// *************************************************************************** *
// *                                                                           *
// *                      Mentor Graphics Corporation                          *
// *                          All rights reserved                              *
// *                                                                           *
// *************************************************************************** *
// *                                                                           *
// * Description:         CANDB File                                           *
// * Generated at:        2020-04-14 13:10:23                                  *
// * System:              SDB20010                                             *
// * Variant:             EX11_AVP                                             *
// * Network:             ChassisCAN1                                          *
// *                                                                           *
// *************************************************************************** *
// *                                                                           *
// *             THIS CONFIGURATION MIGHT CONTAIN SOME ERRORS                  *
// *              IF THE INPUT MODEL WAS NOT PROPERLY FORMED!                  *
// *                    Do Not Use this File directly!                         *
// *                                                                           *
// *************************************************************************** *
VERSION "ChassisCAN1"

NS_ :

BS_:

BU_:  ASDM ECM ETC MVEM PAS PSCM1 SAS TCM VDDM

BO_ 147 AsdmChas1Fr01: 8 ASDM
 SG_ AsyADL3FuncCtrlSts_UB : 32|1@0+ (1,0) [0|1] "" PSCM1
 SG_ AsyADL3FuncCtrlStsADMod : 27|2@0+ (1,0) [0|3] "" PSCM1
 SG_ AsyADL3FuncCtrlStsChks : 23|8@0+ (1.0,0.0) [0.0|255.0] "Unitless" PSCM1
 SG_ AsyADL3FuncCtrlStsCntr : 31|4@0+ (1.0,0.0) [0.0|15.0] "Unitless" PSCM1
 SG_ AsyADL3FuncCtrlStsCtrlSts : 33|1@0+ (1,0) [0|1] "" PSCM1
 SG_ AsyADL3FuncCtrlStsDegraded : 39|4@0+ (1.0,0.0) [0.0|15.0] "Unitless" PSCM1
 SG_ AsyADL3FuncCtrlStsQf : 25|2@0+ (1,0) [0|3] "" PSCM1
 SG_ AsyADL3FuncCtrlStsSts : 35|2@0+ (1,0) [0|3] "" PSCM1
 SG_ AsyADModeReq_UB : 48|1@0+ (1,0) [0|1] "" PSCM1
 SG_ AsyADModeReqADActiveReq : 51|2@0+ (1,0) [0|3] "" PSCM1
 SG_ AsyADModeReqADDeactiveReq : 49|1@0+ (1,0) [0|1] "" PSCM1
 SG_ AsyADModeReqChks : 47|8@0+ (1.0,0.0) [0.0|255.0] "Unitless" PSCM1
 SG_ AsyADModeReqCntr : 55|4@0+ (1.0,0.0) [0.0|15.0] "Unitless" PSCM1
 SG_ PASFuncActive : 15|1@0+ (1,0) [0|1] "" Vector_XXX
 SG_ PASFuncActive_UB : 14|1@0+ (1,0) [0|1] "" Vector_XXX
 SG_ RctaBrkReqQM : 13|1@0+ (1,0) [0|1] "" Vector_XXX
 SG_ RctaBrkReqQM_UB : 12|1@0+ (1,0) [0|1] "" Vector_XXX
 SG_ RcwmBrkReqQM : 11|1@0+ (1,0) [0|1] "" Vector_XXX
 SG_ RcwmBrkReqQM_UB : 10|1@0+ (1,0) [0|1] "" Vector_XXX

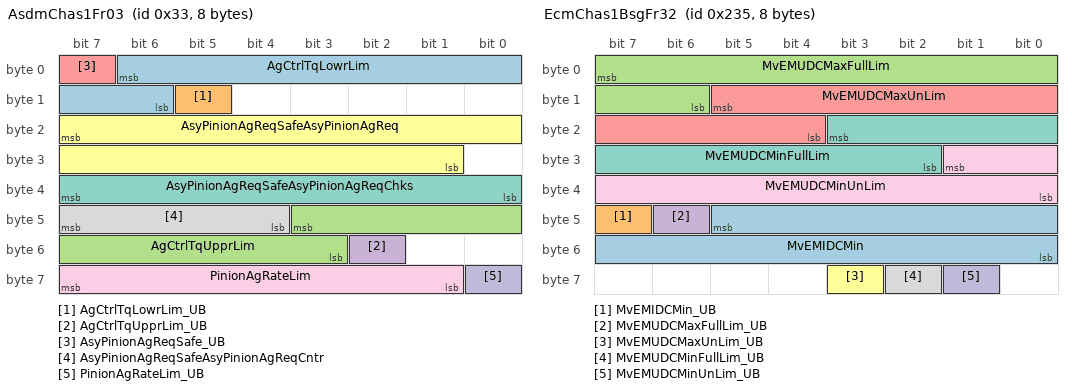
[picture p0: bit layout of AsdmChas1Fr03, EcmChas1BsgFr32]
BO_ 51 AsdmChas1Fr03: 8 ASDM
 SG_ AgCtrlTqLowrLim : 6|9@0+ (0.125,-30.0) [-30.0|30.0] "Nm" PSCM1
 SG_ AgCtrlTqLowrLim_UB : 13|1@0+ (1,0) [0|1] "" PSCM1
 SG_ AgCtrlTqUpprLim : 43|9@0+ (0.125,-30.0) [-30.0|30.0] "Nm" PSCM1
 SG_ AgCtrlTqUpprLim_UB : 50|1@0+ (1,0) [0|1] "" PSCM1
 SG_ AsyPinionAgReqSafe_UB : 7|1@0+ (1,0) [0|1] "" PSCM1
 SG_ AsyPinionAgReqSafeAsyPinionAgReq : 23|15@0+ (0.0009765625,-14.5) [-14.5|17.4990234375] "rad" PSCM1
 SG_ AsyPinionAgReqSafeAsyPinionAgReqChks : 39|8@0+ (1.0,0.0) [0.0|255.0] "Unitless" PSCM1
 SG_ AsyPinionAgReqSafeAsyPinionAgReqCntr : 47|4@0+ (1.0,0.0) [0.0|15.0] "Unitless" PSCM1
 SG_ PinionAgRateLim : 63|7@0+ (0.0175,0.0) [0.0|1.7500000000000002] "rad/s" PSCM1
 SG_ PinionAgRateLim_UB : 56|1@0+ (1,0) [0|1] "" PSCM1

BO_ 1321 AsdmChas1NMFr: 8 ASDM
 SG_ PNC16_ASDM : 16|1@0+ (1,0) [0|0] "" VDDM
 SG_ PNC17_ASDM : 17|1@0+ (1,0) [0|0] "" VDDM
 SG_ PNC18_ASDM : 18|1@0+ (1,0) [0|0] "" VDDM
 SG_ PNC19_ASDM : 19|1@0+ (1,0) [0|0] "" VDDM
 SG_ PNC20_ASDM : 20|1@0+ (1,0) [0|0] "" VDDM
 SG_ PNC21_ASDM : 21|1@0+ (1,0) [0|0] "" VDDM
 SG_ PNC22_ASDM : 22|1@0+ (1,0) [0|0] "" VDDM
 SG_ PNC23_ASDM : 23|1@0+ (1,0) [0|0] "" VDDM
 SG_ PNC24_ASDM : 24|1@0+ (1,0) [0|0] "" VDDM
 SG_ PNC25_ASDM : 25|1@0+ (1,0) [0|0] "" VDDM
 SG_ PNC26_ASDM : 26|1@0+ (1,0) [0|0] "" VDDM
 SG_ PNC27_ASDM : 27|1@0+ (1,0) [0|0] "" VDDM
 SG_ PNC28_ASDM : 28|1@0+ (1,0) [0|0] "" VDDM
 SG_ PNC29_ASDM : 29|1@0+ (1,0) [0|0] "" VDDM
 SG_ PNC30_ASDM : 30|1@0+ (1,0) [0|0] "" VDDM
 SG_ PNC31_ASDM : 31|1@0+ (1,0) [0|0] "" VDDM
 SG_ PNC32_ASDM : 32|1@0+ (1,0) [0|0] "" VDDM
 SG_ PNC33_ASDM : 33|1@0+ (1,0) [0|0] "" VDDM
 SG_ PNC34_ASDM : 34|1@0+ (1,0) [0|0] "" VDDM
 SG_ PNC35_ASDM : 35|1@0+ (1,0) [0|0] "" VDDM
 SG_ PNC36_ASDM : 36|1@0+ (1,0) [0|0] "" VDDM
 SG_ PNC37_ASDM : 37|1@0+ (1,0) [0|0] "" VDDM
 SG_ PNC38_ASDM : 38|1@0+ (1,0) [0|0] "" VDDM
 SG_ PNC39_ASDM : 39|1@0+ (1,0) [0|0] "" VDDM
 SG_ NM_PNI_ASDM : 14|1@0+ (1,0) [0|0] "" VDDM
 SG_ NM_AW_ASDM : 12|1@0+ (1,0) [0|0] "" VDDM
 SG_ NM_CS_ASDM : 11|1@0+ (1,0) [0|0] "" VDDM
 SG_ NM_RMR_ASDM : 8|1@0+ (1,0) [0|0] "" VDDM
 SG_ NM_NodeID_ASDM : 7|8@0+ (1,0) [0|0] "" VDDM

BO_ 565 EcmChas1BsgFr32: 8 ECM
 SG_ MvEMIDCMin : 45|14@0+ (1.0,-500.0) [-500.0|9500.0] "A" MVEM
 SG_ MvEMIDCMin_UB : 47|1@0+ (1,0) [0|1] "" MVEM
 SG_ MvEMUDCMaxFullLim : 7|10@0+ (0.1,0.0) [0.0|102.30000000000001] "Volt" MVEM
 SG_ MvEMUDCMaxFullLim_UB : 46|1@0+ (1,0) [0|1] "" MVEM
 SG_ MvEMUDCMaxUnLim : 13|10@0+ (0.1,0.0) [0.0|102.30000000000001] "Volt" MVEM
 SG_ MvEMUDCMaxUnLim_UB : 59|1@0+ (1,0) [0|1] "" MVEM
 SG_ MvEMUDCMinFullLim : 19|10@0+ (0.1,0.0) [0.0|102.30000000000001] "Volt" MVEM
 SG_ MvEMUDCMinFullLim_UB : 58|1@0+ (1,0) [0|1] "" MVEM
 SG_ MvEMUDCMinUnLim : 25|10@0+ (0.1,0.0) [0.0|102.30000000000001] "Volt" MVEM
 SG_ MvEMUDCMinUnLim_UB : 57|1@0+ (1,0) [0|1] "" MVEM

BO_ 631 EcmChas1BsgFr33: 8 ECM
 SG_ MvEMCooltFlowForDtElec : 7|9@0+ (0.1,0.0) [0.0|51.1] "L / min" MVEM
 SG_ MvEMCooltFlowForDtElec_UB : 8|1@0+ (1,0) [0|1] "" MVEM
 SG_ MvEMCooltT : 23|8@0+ (1.0,-50.0) [-50.0|200.0] "degC" MVEM
 SG_ MvEMCooltT_UB : 14|1@0+ (1,0) [0|1] "" MVEM

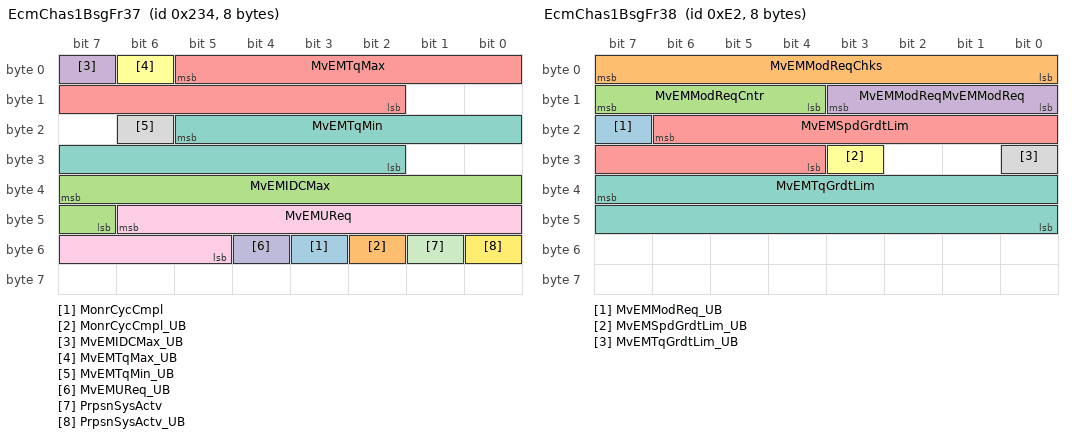
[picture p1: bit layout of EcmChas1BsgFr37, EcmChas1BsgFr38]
BO_ 564 EcmChas1BsgFr37: 8 ECM
 SG_ MonrCycCmpl : 51|1@0+ (1,0) [0|1] "" MVEM
 SG_ MonrCycCmpl_UB : 50|1@0+ (1,0) [0|1] "" MVEM
 SG_ MvEMIDCMax : 39|9@0+ (1.0,0.0) [0.0|511.0] "A" MVEM
 SG_ MvEMIDCMax_UB : 7|1@0+ (1,0) [0|1] "" MVEM
 SG_ MvEMTqMax : 5|12@0+ (0.1,-70.0) [-70.0|70.0] "NewtonMeter" MVEM
 SG_ MvEMTqMax_UB : 6|1@0+ (1,0) [0|1] "" MVEM
 SG_ MvEMTqMin : 21|12@0+ (0.1,-70.0) [-70.0|70.0] "NewtonMeter" MVEM
 SG_ MvEMTqMin_UB : 22|1@0+ (1,0) [0|1] "" MVEM
 SG_ MvEMUReq : 46|10@0+ (0.1,0.0) [0.0|102.30000000000001] "Volt" MVEM
 SG_ MvEMUReq_UB : 52|1@0+ (1,0) [0|1] "" MVEM
 SG_ PrpsnSysActv : 49|1@0+ (1,0) [0|1] "" MVEM
 SG_ PrpsnSysActv_UB : 48|1@0+ (1,0) [0|1] "" MVEM

BO_ 226 EcmChas1BsgFr38: 8 ECM
 SG_ MvEMModReq_UB : 23|1@0+ (1,0) [0|1] "" MVEM
 SG_ MvEMModReqChks : 7|8@0+ (1.0,0.0) [0.0|255.0] "Unitless" MVEM
 SG_ MvEMModReqCntr : 15|4@0+ (1.0,0.0) [0.0|15.0] "Unitless" MVEM
 SG_ MvEMModReqMvEMModReq : 11|4@0+ (1,0) [0|15] "" MVEM
 SG_ MvEMSpdGrdtLim : 22|11@0+ (20.0,0.0) [0.0|40000.0] "RpmPerSec" MVEM
 SG_ MvEMSpdGrdtLim_UB : 27|1@0+ (1,0) [0|1] "" MVEM
 SG_ MvEMTqGrdtLim : 39|16@0+ (1.0,0.0) [0.0|55000.0] "Nm/s" MVEM
 SG_ MvEMTqGrdtLim_UB : 24|1@0+ (1,0) [0|1] "" MVEM

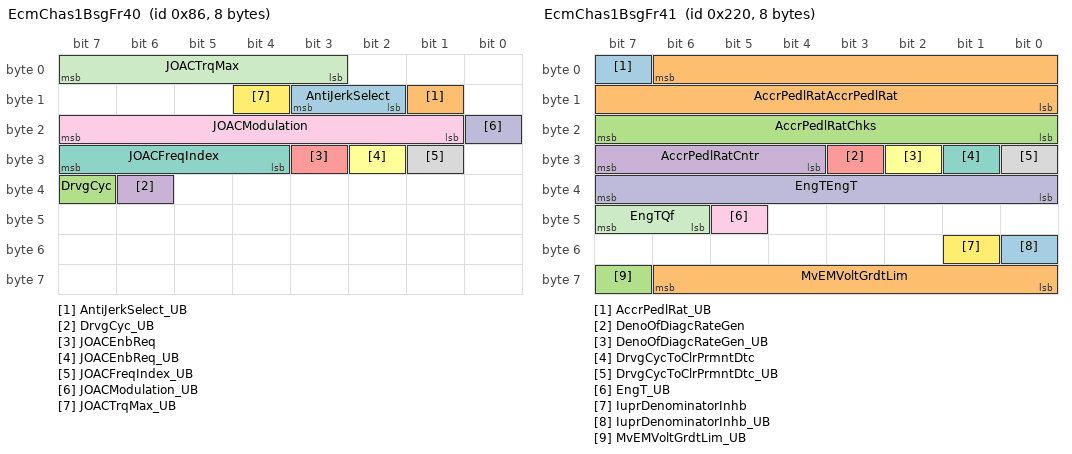
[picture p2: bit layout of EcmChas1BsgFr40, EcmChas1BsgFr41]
BO_ 134 EcmChas1BsgFr40: 8 ECM
 SG_ AntiJerkSelect : 11|2@0+ (1,0) [0|3] "" MVEM
 SG_ AntiJerkSelect_UB : 9|1@0+ (1,0) [0|1] "" MVEM
 SG_ DrvgCyc : 39|1@0+ (1,0) [0|1] "" MVEM
 SG_ DrvgCyc_UB : 38|1@0+ (1,0) [0|1] "" MVEM
 SG_ JOACEnbReq : 27|1@0+ (1,0) [0|1] "" MVEM
 SG_ JOACEnbReq_UB : 26|1@0+ (1,0) [0|1] "" MVEM
 SG_ JOACFreqIndex : 31|4@0+ (1,0) [0|15] "" MVEM
 SG_ JOACFreqIndex_UB : 25|1@0+ (1,0) [0|1] "" MVEM
 SG_ JOACModulation : 23|7@0+ (1.0,0.0) [0.0|100.0] "Unitless" MVEM
 SG_ JOACModulation_UB : 16|1@0+ (1,0) [0|1] "" MVEM
 SG_ JOACTrqMax : 7|5@0+ (1.0,0.0) [0.0|25.0] "Unitless" MVEM
 SG_ JOACTrqMax_UB : 12|1@0+ (1,0) [0|1] "" MVEM

BO_ 544 EcmChas1BsgFr41: 8 ECM
 SG_ AccrPedlRat_UB : 7|1@0+ (1,0) [0|1] "" MVEM
 SG_ AccrPedlRatAccrPedlRat : 6|15@0+ (0.00390625,0.0) [0.0|100.0] "%" MVEM
 SG_ AccrPedlRatChks : 23|8@0+ (1.0,0.0) [0.0|255.0] "Unitless" MVEM
 SG_ AccrPedlRatCntr : 31|4@0+ (1.0,0.0) [0.0|15.0] "Unitless" MVEM
 SG_ DenoOfDiagcRateGen : 27|1@0+ (1,0) [0|1] "" MVEM
 SG_ DenoOfDiagcRateGen_UB : 26|1@0+ (1,0) [0|1] "" MVEM
 SG_ DrvgCycToClrPrmntDtc : 25|1@0+ (1,0) [0|1] "" MVEM
 SG_ DrvgCycToClrPrmntDtc_UB : 24|1@0+ (1,0) [0|1] "" MVEM
 SG_ EngT_UB : 45|1@0+ (1,0) [0|1] "" MVEM
 SG_ EngTEngT : 39|8@0+ (1.0,-50.0) [-50.0|200.0] "degC" MVEM
 SG_ EngTQf : 47|2@0+ (1,0) [0|3] "" MVEM
 SG_ IuprDenominatorInhb : 49|1@0+ (1,0) [0|1] "" MVEM
 SG_ IuprDenominatorInhb_UB : 48|1@0+ (1,0) [0|1] "" MVEM
 SG_ MvEMVoltGrdtLim : 62|7@0+ (1.0,0.0) [0.0|100.0] "V/s" MVEM
 SG_ MvEMVoltGrdtLim_UB : 63|1@0+ (1,0) [0|1] "" MVEM

BO_ 530 EcmChas1BsgFr42: 8 ECM
 SG_ EngTiOn : 31|16@0+ (1.0,0.0) [0.0|65535.0] "s" MVEM
 SG_ EngTiOn_UB : 13|1@0+ (1,0) [0|1] "" MVEM
 SG_ LoadValCalcd : 7|8@0+ (0.392156862745,0.0) [0.0|99.999999999975] "%" MVEM
 SG_ LoadValCalcd_UB : 15|1@0+ (1,0) [0|1] "" MVEM
 SG_ ThrPos : 23|8@0+ (0.5,0.0) [0.0|100.0] "%" MVEM
 SG_ ThrPos_UB : 14|1@0+ (1,0) [0|1] "" MVEM

BO_ 32 EcmChas1Fr01: 8 ECM
 SG_ PtCluSlipCtrl_UB : 5|1@0+ (1,0) [0|1] "" TCM
 SG_ PtCluSlipCtrlModReq : 3|2@0+ (1,0) [0|3] "" TCM
 SG_ PtCluSlipCtrlReq : 4|1@0+ (1,0) [0|1] "" TCM
 SG_ PtCluSlipCtrlSpdReq : 1|10@0+ (1.0,0.0) [0.0|1023.0] "rpm" TCM
 SG_ PtCluTqCp_UB : 21|1@0+ (1,0) [0|1] "" TCM
 SG_ PtCluTqCpReq1 : 20|13@0+ (0.1,-5.0) [-5.0|814.1] "NewtonMeter" TCM
 SG_ PtCluTqCpReq2 : 36|13@0+ (0.1,-5.0) [-5.0|814.1] "NewtonMeter" TCM
 SG_ PtEngTqDstbcActv : 6|1@0+ (1,0) [0|1] "" TCM
 SG_ PtEngTqDstbcActv_UB : 7|1@0+ (1,0) [0|1] "" TCM
 SG_ PtEngTqModlnSts : 23|2@0+ (1,0) [0|3] "" TCM
 SG_ PtEngTqModlnSts_UB : 55|1@0+ (1,0) [0|1] "" TCM
 SG_ PtGearActtnReq3 : 59|4@0+ (1,0) [0|15] "" TCM
 SG_ PtGearActtnReq3_UB : 53|1@0+ (1,0) [0|1] "" TCM
 SG_ PtRotReqAckd1 : 48|1@0+ (1,0) [0|1] "" TCM
 SG_ PtRotReqAckd1_UB : 50|1@0+ (1,0) [0|1] "" TCM
 SG_ PtRotReqAckd2 : 49|1@0+ (1,0) [0|1] "" TCM
 SG_ PtRotReqAckd2_UB : 51|1@0+ (1,0) [0|1] "" TCM

BO_ 37 EcmChas1Fr02: 8 ECM
 SG_ PtCluTqCpMaxCmd1 : 40|1@0+ (1,0) [0|1] "" TCM
 SG_ PtCluTqCpMaxCmd1_UB : 45|1@0+ (1,0) [0|1] "" TCM
 SG_ PtCluTqCpMaxCmd2 : 41|1@0+ (1,0) [0|1] "" TCM
 SG_ PtCluTqCpMaxCmd2_UB : 46|1@0+ (1,0) [0|1] "" TCM
 SG_ PtCluTqCpMinCmd1 : 42|1@0+ (1,0) [0|1] "" TCM
 SG_ PtCluTqCpMinCmd1_UB : 55|1@0+ (1,0) [0|1] "" TCM
 SG_ PtCluTqCpMinCmd2 : 43|1@0+ (1,0) [0|1] "" TCM
 SG_ PtCluTqCpMinCmd2_UB : 54|1@0+ (1,0) [0|1] "" TCM
 SG_ PtDirAllwdToTrsmActr_UB : 47|1@0+ (1,0) [0|1] "" TCM
 SG_ PtDirAllwdToTrsmActrChks : 39|8@0+ (1.0,0.0) [0.0|255.0] "Unitless" TCM
 SG_ PtDirAllwdToTrsmActrCntr : 27|4@0+ (1.0,0.0) [0.0|15.0] "Unitless" TCM
 SG_ PtDirAllwdToTrsmActrFwd : 28|1@0+ (1,0) [0|1] "" TCM
 SG_ PtDirAllwdToTrsmActrNeut : 29|1@0+ (1,0) [0|1] "" TCM
 SG_ PtDirAllwdToTrsmActrParkRls : 30|1@0+ (1,0) [0|1] "" TCM
 SG_ PtDirAllwdToTrsmActrRvs : 31|1@0+ (1,0) [0|1] "" TCM
 SG_ PtGearActrAdpnCmd : 44|1@0+ (1,0) [0|1] "" TCM
 SG_ PtGearActrAdpnCmd_UB : 53|1@0+ (1,0) [0|1] "" TCM
 SG_ PtGearActtn_UB : 7|1@0+ (1,0) [0|1] "" TCM,VDDM
 SG_ PtGearActtnAllwdSts1 : 6|2@0+ (1,0) [0|3] "" TCM,VDDM
 SG_ PtGearActtnAllwdSts2 : 4|2@0+ (1,0) [0|3] "" TCM,VDDM
 SG_ PtGearActtnModReq : 2|2@0+ (1,0) [0|3] "" TCM,VDDM
 SG_ PtGearActtnPfmncReq : 23|8@0+ (1.0,0.0) [0.0|255.0] "Unitless" TCM,VDDM
 SG_ PtGearActtnPrio : 0|1@0+ (1,0) [0|1] "" TCM,VDDM
 SG_ PtGearActtnReq1 : 15|4@0+ (1,0) [0|15] "" TCM,VDDM
 SG_ PtGearActtnReq2 : 11|4@0+ (1,0) [0|15] "" TCM,VDDM

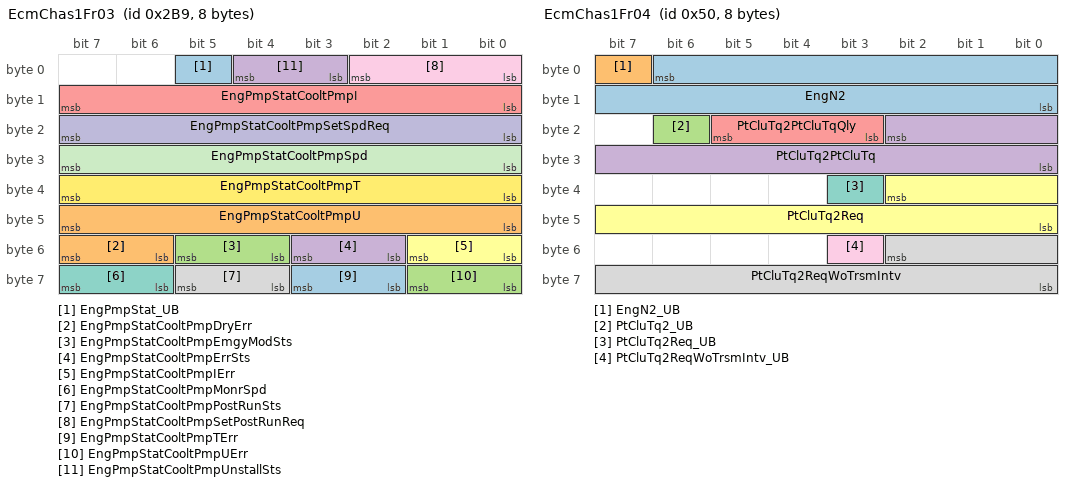
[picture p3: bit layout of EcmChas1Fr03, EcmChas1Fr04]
BO_ 697 EcmChas1Fr03: 8 ECM
 SG_ EngPmpStat_UB : 5|1@0+ (1,0) [0|1] "" VDDM
 SG_ EngPmpStatCooltPmpDryErr : 55|2@0+ (1,0) [0|3] "" VDDM
 SG_ EngPmpStatCooltPmpEmgyModSts : 53|2@0+ (1,0) [0|3] "" VDDM
 SG_ EngPmpStatCooltPmpErrSts : 51|2@0+ (1,0) [0|3] "" VDDM
 SG_ EngPmpStatCooltPmpI : 15|8@0+ (0.2,0.0) [0.0|50.800000000000004] "A" VDDM
 SG_ EngPmpStatCooltPmpIErr : 49|2@0+ (1,0) [0|3] "" VDDM
 SG_ EngPmpStatCooltPmpMonrSpd : 63|2@0+ (1,0) [0|3] "" VDDM
 SG_ EngPmpStatCooltPmpPostRunSts : 61|2@0+ (1,0) [0|3] "" VDDM
 SG_ EngPmpStatCooltPmpSetPostRunReq : 2|3@0+ (1,0) [0|7] "" VDDM
 SG_ EngPmpStatCooltPmpSetSpdReq : 23|8@0+ (1.0,0.0) [0.0|254.0] "Unitless" VDDM
 SG_ EngPmpStatCooltPmpSpd : 31|8@0+ (1.0,0.0) [0.0|254.0] "Unitless" VDDM
 SG_ EngPmpStatCooltPmpT : 39|8@0+ (1.0,-50.0) [-50.0|200.0] "degC" VDDM
 SG_ EngPmpStatCooltPmpTErr : 59|2@0+ (1,0) [0|3] "" VDDM
 SG_ EngPmpStatCooltPmpU : 47|8@0+ (0.1,0.0) [0.0|25.0] "Volt" VDDM
 SG_ EngPmpStatCooltPmpUErr : 57|2@0+ (1,0) [0|3] "" VDDM
 SG_ EngPmpStatCooltPmpUnstallSts : 4|2@0+ (1,0) [0|3] "" VDDM

BO_ 80 EcmChas1Fr04: 8 ECM
 SG_ EngN2 : 6|15@0+ (0.5,0.0) [0.0|16383.5] "rpm" TCM,VDDM
 SG_ EngN2_UB : 7|1@0+ (1,0) [0|1] "" TCM,VDDM
 SG_ PtCluTq2_UB : 22|1@0+ (1,0) [0|1] "" TCM
 SG_ PtCluTq2PtCluTq : 18|11@0+ (1.0,-1024.0) [-1024.0|1023.0] "NewtonMeter" TCM
 SG_ PtCluTq2PtCluTqQly : 21|3@0+ (1,0) [0|7] "" TCM
 SG_ PtCluTq2Req : 34|11@0+ (1.0,-1024.0) [-1024.0|1023.0] "NewtonMeter" TCM
 SG_ PtCluTq2Req_UB : 35|1@0+ (1,0) [0|1] "" TCM
 SG_ PtCluTq2ReqWoTrsmIntv : 50|11@0+ (1.0,-1024.0) [-1024.0|1023.0] "NewtonMeter" TCM
 SG_ PtCluTq2ReqWoTrsmIntv_UB : 51|1@0+ (1,0) [0|1] "" TCM

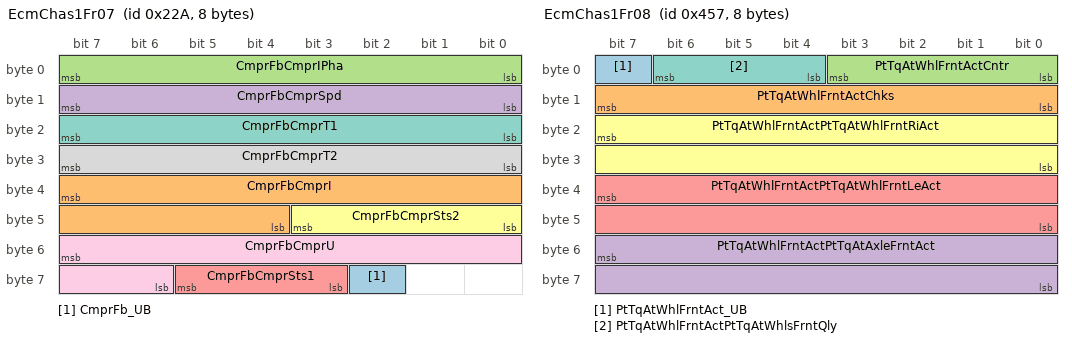
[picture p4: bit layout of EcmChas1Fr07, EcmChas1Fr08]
BO_ 554 EcmChas1Fr07: 8 ECM
 SG_ CmprFb_UB : 58|1@0+ (1,0) [0|1] "" VDDM
 SG_ CmprFbCmprI : 39|12@0+ (0.1,0.0) [0.0|409.5] "A" VDDM
 SG_ CmprFbCmprIPha : 7|8@0+ (0.5,0.0) [0.0|127.0] "A" VDDM
 SG_ CmprFbCmprSpd : 15|8@0+ (50.0,0.0) [0.0|12700.0] "rpm" VDDM
 SG_ CmprFbCmprSts1 : 61|3@0+ (1,0) [0|7] "" VDDM
 SG_ CmprFbCmprSts2 : 43|4@0+ (1,0) [0|15] "" VDDM
 SG_ CmprFbCmprT1 : 23|8@0+ (1.0,-50.0) [-50.0|204.0] "degC" VDDM
 SG_ CmprFbCmprT2 : 31|8@0+ (1.0,-50.0) [-50.0|204.0] "degC" VDDM
 SG_ CmprFbCmprU : 55|10@0+ (2.0,0.0) [0.0|2046.0] "Volt" VDDM

BO_ 1111 EcmChas1Fr08: 8 ECM
 SG_ PtTqAtWhlFrntAct_UB : 7|1@0+ (1,0) [0|1] "" PSCM1
 SG_ PtTqAtWhlFrntActChks : 15|8@0+ (1.0,0.0) [0.0|255.0] "Unitless" PSCM1
 SG_ PtTqAtWhlFrntActCntr : 3|4@0+ (1.0,0.0) [0.0|15.0] "Unitless" PSCM1
 SG_ PtTqAtWhlFrntActPtTqAtAxleFrntAct : 55|16@0- (1.0,0.0) [-20000.0|20000.0] "NewtonMeter" PSCM1
 SG_ PtTqAtWhlFrntActPtTqAtWhlFrntLeAct : 39|16@0- (1.0,0.0) [-20000.0|20000.0] "NewtonMeter" PSCM1
 SG_ PtTqAtWhlFrntActPtTqAtWhlFrntRiAct : 23|16@0- (1.0,0.0) [-20000.0|20000.0] "NewtonMeter" PSCM1
 SG_ PtTqAtWhlFrntActPtTqAtWhlsFrntQly : 6|3@0+ (1,0) [0|7] "" PSCM1

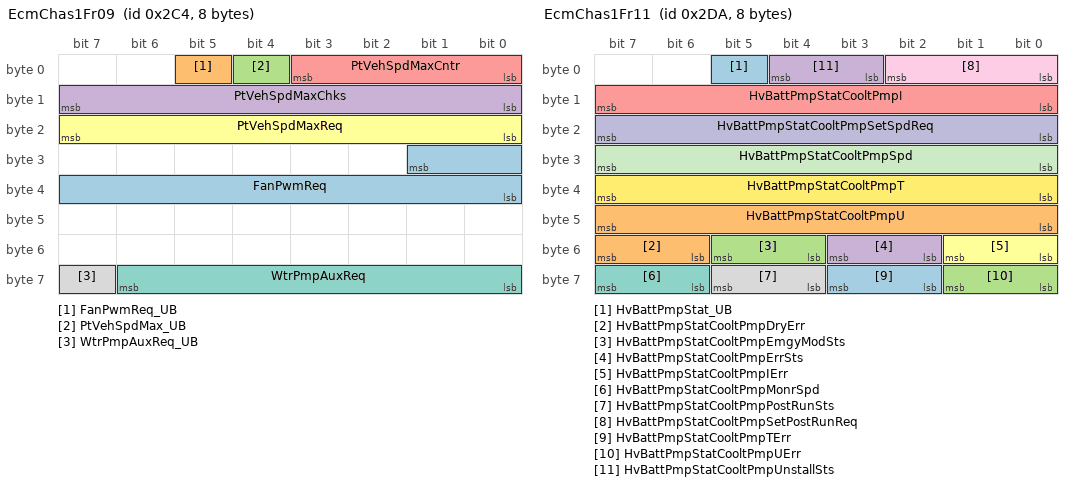
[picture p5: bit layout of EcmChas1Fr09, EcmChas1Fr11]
BO_ 708 EcmChas1Fr09: 8 ECM
 SG_ FanPwmReq : 25|10@0+ (0.1,0.0) [0.0|100.0] "%" VDDM
 SG_ FanPwmReq_UB : 5|1@0+ (1,0) [0|1] "" VDDM
 SG_ PtVehSpdMax_UB : 4|1@0+ (1,0) [0|1] "" VDDM
 SG_ PtVehSpdMaxChks : 15|8@0+ (1.0,0.0) [0.0|255.0] "Unitless" VDDM
 SG_ PtVehSpdMaxCntr : 3|4@0+ (1.0,0.0) [0.0|15.0] "Unitless" VDDM
 SG_ PtVehSpdMaxReq : 23|8@0+ (0.4,0.0) [0.0|102.0] "m/s" VDDM
 SG_ WtrPmpAuxReq : 62|7@0+ (1.0,0.0) [0.0|100.0] "%" VDDM
 SG_ WtrPmpAuxReq_UB : 63|1@0+ (1,0) [0|1] "" VDDM

BO_ 730 EcmChas1Fr11: 8 ECM
 SG_ HvBattPmpStat_UB : 5|1@0+ (1,0) [0|1] "" VDDM
 SG_ HvBattPmpStatCooltPmpDryErr : 55|2@0+ (1,0) [0|3] "" VDDM
 SG_ HvBattPmpStatCooltPmpEmgyModSts : 53|2@0+ (1,0) [0|3] "" VDDM
 SG_ HvBattPmpStatCooltPmpErrSts : 51|2@0+ (1,0) [0|3] "" VDDM
 SG_ HvBattPmpStatCooltPmpI : 15|8@0+ (0.2,0.0) [0.0|50.800000000000004] "A" VDDM
 SG_ HvBattPmpStatCooltPmpIErr : 49|2@0+ (1,0) [0|3] "" VDDM
 SG_ HvBattPmpStatCooltPmpMonrSpd : 63|2@0+ (1,0) [0|3] "" VDDM
 SG_ HvBattPmpStatCooltPmpPostRunSts : 61|2@0+ (1,0) [0|3] "" VDDM
 SG_ HvBattPmpStatCooltPmpSetPostRunReq : 2|3@0+ (1,0) [0|7] "" VDDM
 SG_ HvBattPmpStatCooltPmpSetSpdReq : 23|8@0+ (1.0,0.0) [0.0|254.0] "Unitless" VDDM
 SG_ HvBattPmpStatCooltPmpSpd : 31|8@0+ (1.0,0.0) [0.0|254.0] "Unitless" VDDM
 SG_ HvBattPmpStatCooltPmpT : 39|8@0+ (1.0,-50.0) [-50.0|200.0] "degC" VDDM
 SG_ HvBattPmpStatCooltPmpTErr : 59|2@0+ (1,0) [0|3] "" VDDM
 SG_ HvBattPmpStatCooltPmpU : 47|8@0+ (0.1,0.0) [0.0|25.0] "Volt" VDDM
 SG_ HvBattPmpStatCooltPmpUErr : 57|2@0+ (1,0) [0|3] "" VDDM
 SG_ HvBattPmpStatCooltPmpUnstallSts : 4|2@0+ (1,0) [0|3] "" VDDM

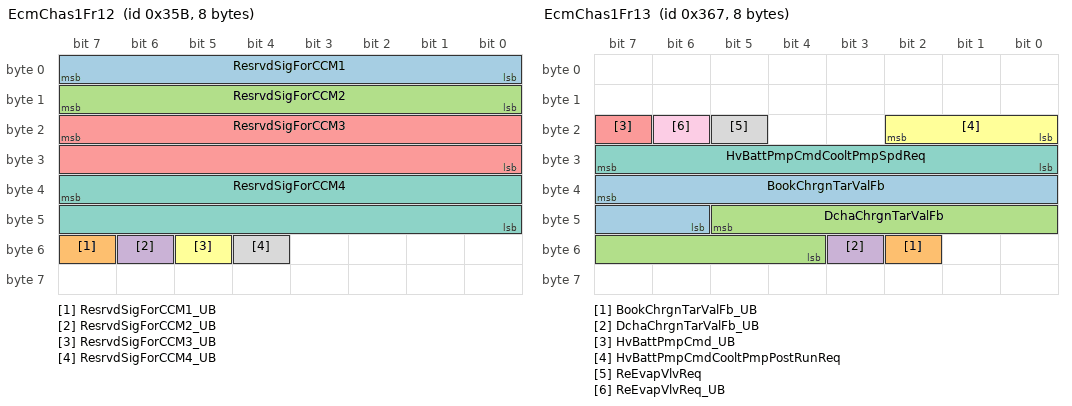
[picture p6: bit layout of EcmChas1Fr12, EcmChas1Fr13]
BO_ 859 EcmChas1Fr12: 8 ECM
 SG_ ResrvdSigForCCM1 : 7|8@0+ (1.0,0.0) [0.0|255.0] "Unitless" VDDM
 SG_ ResrvdSigForCCM1_UB : 55|1@0+ (1,0) [0|1] "" VDDM
 SG_ ResrvdSigForCCM2 : 15|8@0+ (1.0,0.0) [0.0|255.0] "Unitless" VDDM
 SG_ ResrvdSigForCCM2_UB : 54|1@0+ (1,0) [0|1] "" VDDM
 SG_ ResrvdSigForCCM3 : 23|16@0+ (1.0,0.0) [0.0|65535.0] "Unitless" VDDM
 SG_ ResrvdSigForCCM3_UB : 53|1@0+ (1,0) [0|1] "" VDDM
 SG_ ResrvdSigForCCM4 : 39|16@0+ (1.0,0.0) [0.0|65535.0] "Unitless" VDDM
 SG_ ResrvdSigForCCM4_UB : 52|1@0+ (1,0) [0|1] "" VDDM

BO_ 871 EcmChas1Fr13: 8 ECM
 SG_ BookChrgnTarValFb : 39|10@0+ (0.1,0.0) [0.0|100.0] "%" VDDM
 SG_ BookChrgnTarValFb_UB : 50|1@0+ (1,0) [0|1] "" VDDM
 SG_ DchaChrgnTarValFb : 45|10@0+ (0.1,0.0) [0.0|100.0] "%" VDDM
 SG_ DchaChrgnTarValFb_UB : 51|1@0+ (1,0) [0|1] "" VDDM
 SG_ HvBattPmpCmd_UB : 23|1@0+ (1,0) [0|1] "" VDDM
 SG_ HvBattPmpCmdCooltPmpPostRunReq : 18|3@0+ (1,0) [0|7] "" VDDM
 SG_ HvBattPmpCmdCooltPmpSpdReq : 31|8@0+ (1.0,0.0) [0.0|254.0] "Unitless" VDDM
 SG_ ReEvapVlvReq : 21|1@0+ (1,0) [0|1] "" VDDM
 SG_ ReEvapVlvReq_UB : 22|1@0+ (1,0) [0|1] "" VDDM

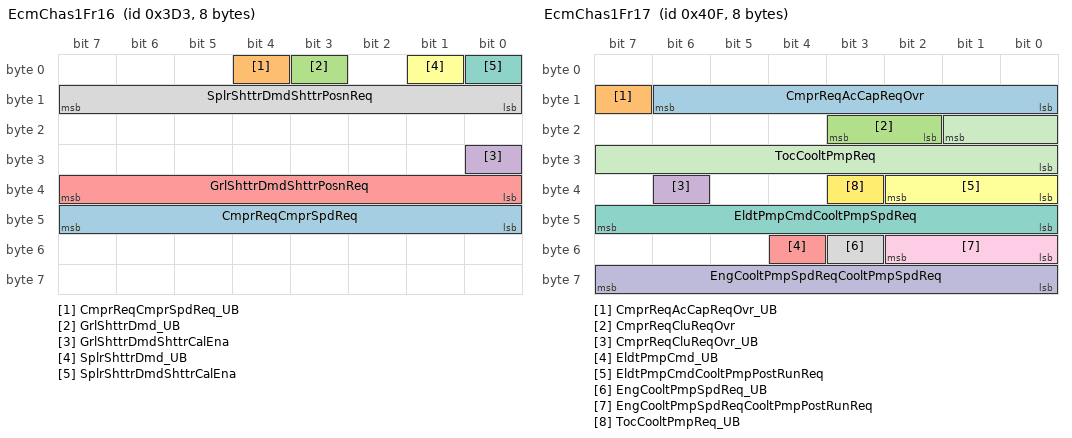
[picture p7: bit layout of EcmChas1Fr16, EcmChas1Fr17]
BO_ 979 EcmChas1Fr16: 8 ECM
 SG_ CmprReqCmprSpdReq : 47|8@0+ (50.0,0.0) [0.0|12700.0] "rpm" VDDM
 SG_ CmprReqCmprSpdReq_UB : 4|1@0+ (1,0) [0|1] "" VDDM
 SG_ GrlShttrDmd_UB : 3|1@0+ (1,0) [0|1] "" VDDM
 SG_ GrlShttrDmdShttrCalEna : 24|1@0+ (1,0) [0|1] "" VDDM
 SG_ GrlShttrDmdShttrPosnReq : 39|8@0+ (1.0,0.0) [0.0|255.0] "Unitless" VDDM
 SG_ SplrShttrDmd_UB : 1|1@0+ (1,0) [0|1] "" VDDM
 SG_ SplrShttrDmdShttrCalEna : 0|1@0+ (1,0) [0|1] "" VDDM
 SG_ SplrShttrDmdShttrPosnReq : 15|8@0+ (1.0,0.0) [0.0|255.0] "Unitless" VDDM

BO_ 1039 EcmChas1Fr17: 8 ECM
 SG_ CmprReqAcCapReqOvr : 14|7@0+ (1.0,0.0) [0.0|100.0] "%" VDDM
 SG_ CmprReqAcCapReqOvr_UB : 15|1@0+ (1,0) [0|1] "" VDDM
 SG_ CmprReqCluReqOvr : 19|2@0+ (1,0) [0|3] "" VDDM
 SG_ CmprReqCluReqOvr_UB : 38|1@0+ (1,0) [0|1] "" VDDM
 SG_ EldtPmpCmd_UB : 52|1@0+ (1,0) [0|1] "" VDDM
 SG_ EldtPmpCmdCooltPmpPostRunReq : 34|3@0+ (1,0) [0|7] "" VDDM
 SG_ EldtPmpCmdCooltPmpSpdReq : 47|8@0+ (1.0,0.0) [0.0|254.0] "Unitless" VDDM
 SG_ EngCooltPmpSpdReq_UB : 51|1@0+ (1,0) [0|1] "" VDDM
 SG_ EngCooltPmpSpdReqCooltPmpPostRunReq : 50|3@0+ (1,0) [0|7] "" VDDM
 SG_ EngCooltPmpSpdReqCooltPmpSpdReq : 63|8@0+ (1.0,0.0) [0.0|254.0] "Unitless" VDDM
 SG_ TocCooltPmpReq : 17|10@0+ (0.1,0.0) [0.0|100.0] "%" VDDM
 SG_ TocCooltPmpReq_UB : 35|1@0+ (1,0) [0|1] "" VDDM

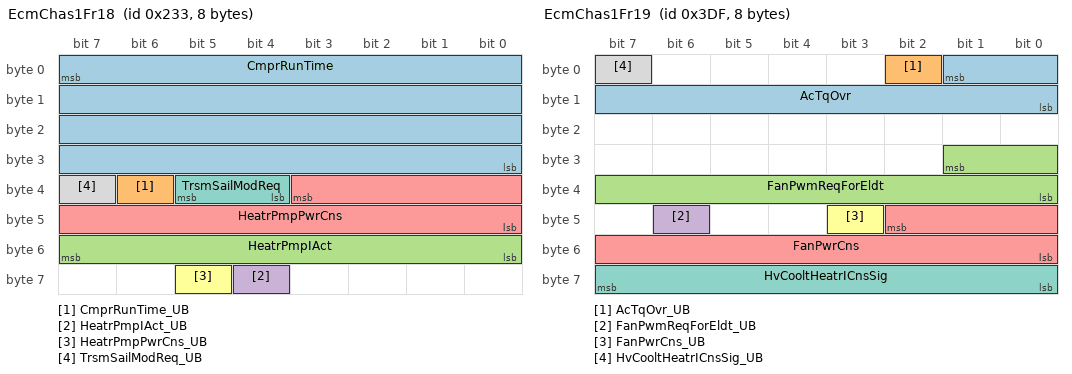
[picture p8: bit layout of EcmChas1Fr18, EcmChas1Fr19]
BO_ 563 EcmChas1Fr18: 8 ECM
 SG_ CmprRunTime : 7|32@0+ (1.0,0.0) [0.0|4294967295.0] "Unitless" VDDM
 SG_ CmprRunTime_UB : 38|1@0+ (1,0) [0|1] "" VDDM
 SG_ HeatrPmpIAct : 55|8@0+ (0.2,0.0) [0.0|50.800000000000004] "A" VDDM
 SG_ HeatrPmpIAct_UB : 60|1@0+ (1,0) [0|1] "" VDDM
 SG_ HeatrPmpPwrCns : 35|12@0+ (1.0,0.0) [0.0|4095.0] "W" VDDM
 SG_ HeatrPmpPwrCns_UB : 61|1@0+ (1,0) [0|1] "" VDDM
 SG_ TrsmSailModReq : 37|2@0+ (1,0) [0|3] "" TCM
 SG_ TrsmSailModReq_UB : 39|1@0+ (1,0) [0|1] "" TCM

BO_ 991 EcmChas1Fr19: 8 ECM
 SG_ AcTqOvr : 1|10@0+ (1.0,0.0) [0.0|1000.0] "NewtonMeter" VDDM
 SG_ AcTqOvr_UB : 2|1@0+ (1,0) [0|1] "" VDDM
 SG_ FanPwmReqForEldt : 25|10@0+ (0.1,0.0) [0.0|100.0] "%" VDDM
 SG_ FanPwmReqForEldt_UB : 46|1@0+ (1,0) [0|1] "" VDDM
 SG_ FanPwrCns : 42|11@0+ (1.0,0.0) [0.0|2047.0] "W" VDDM
 SG_ FanPwrCns_UB : 43|1@0+ (1,0) [0|1] "" VDDM
 SG_ HvCooltHeatrICnsSig : 63|8@0+ (0.25,0.0) [0.0|63.75] "Unitless" VDDM
 SG_ HvCooltHeatrICnsSig_UB : 7|1@0+ (1,0) [0|1] "" VDDM

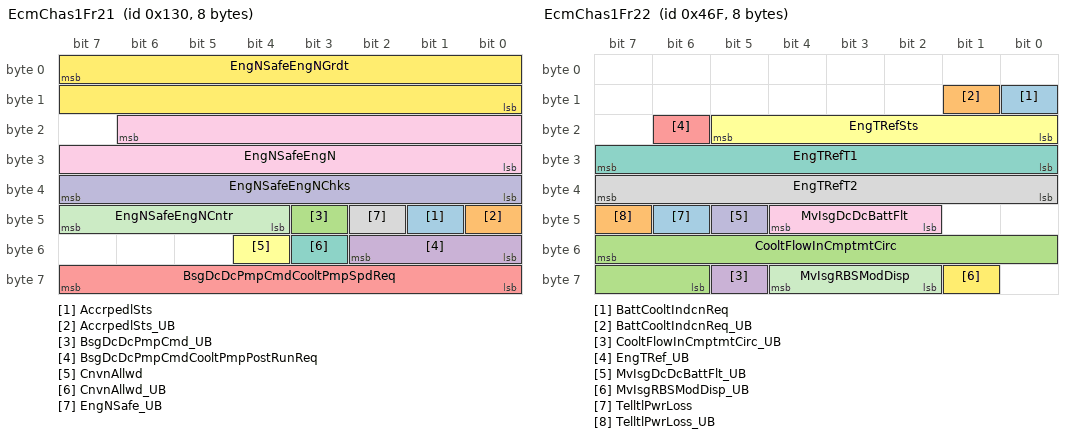
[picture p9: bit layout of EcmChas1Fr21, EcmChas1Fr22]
BO_ 304 EcmChas1Fr21: 8 ECM
 SG_ AccrpedlSts : 41|1@0+ (1,0) [0|1] "" VDDM
 SG_ AccrpedlSts_UB : 40|1@0+ (1,0) [0|1] "" VDDM
 SG_ BsgDcDcPmpCmd_UB : 43|1@0+ (1,0) [0|1] "" VDDM
 SG_ BsgDcDcPmpCmdCooltPmpPostRunReq : 50|3@0+ (1,0) [0|7] "" VDDM
 SG_ BsgDcDcPmpCmdCooltPmpSpdReq : 63|8@0+ (1.0,0.0) [0.0|254.0] "Unitless" VDDM
 SG_ CnvnAllwd : 52|1@0+ (1,0) [0|1] "" VDDM
 SG_ CnvnAllwd_UB : 51|1@0+ (1,0) [0|1] "" VDDM
 SG_ EngNSafe_UB : 42|1@0+ (1,0) [0|1] "" MVEM,SAS
 SG_ EngNSafeEngN : 22|15@0+ (0.5,0.0) [0.0|16383.5] "rpm" MVEM,SAS
 SG_ EngNSafeEngNChks : 39|8@0+ (1.0,0.0) [0.0|255.0] "Unitless" MVEM,SAS
 SG_ EngNSafeEngNCntr : 47|4@0+ (1.0,0.0) [0.0|15.0] "Unitless" MVEM,SAS
 SG_ EngNSafeEngNGrdt : 7|16@0- (1.0,0.0) [-30000.0|32767.0] "RpmPerSec" MVEM,SAS

BO_ 1135 EcmChas1Fr22: 8 ECM
 SG_ BattCooltIndcnReq : 8|1@0+ (1,0) [0|1] "" VDDM
 SG_ BattCooltIndcnReq_UB : 9|1@0+ (1,0) [0|1] "" VDDM
 SG_ CooltFlowInCmptmtCirc : 55|10@0+ (0.05,0.0) [0.0|51.150000000000006] "L / min" VDDM
 SG_ CooltFlowInCmptmtCirc_UB : 61|1@0+ (1,0) [0|1] "" VDDM
 SG_ EngTRef_UB : 22|1@0+ (1,0) [0|1] "" TCM
 SG_ EngTRefSts : 21|6@0+ (1.0,0.0) [0.0|63.0] "Unitless" TCM
 SG_ EngTRefT1 : 31|8@0+ (1.0,-50.0) [-50.0|200.0] "degC" TCM
 SG_ EngTRefT2 : 39|8@0+ (1.0,-50.0) [-50.0|200.0] "degC" TCM
 SG_ MvIsgDcDcBattFlt : 44|3@0+ (1,0) [0|7] "" VDDM
 SG_ MvIsgDcDcBattFlt_UB : 45|1@0+ (1,0) [0|1] "" VDDM
 SG_ MvIsgRBSModDisp : 60|3@0+ (1,0) [0|7] "" VDDM
 SG_ MvIsgRBSModDisp_UB : 57|1@0+ (1,0) [0|1] "" VDDM
 SG_ TelltlPwrLoss : 46|1@0+ (1,0) [0|1] "" VDDM
 SG_ TelltlPwrLoss_UB : 47|1@0+ (1,0) [0|1] "" VDDM

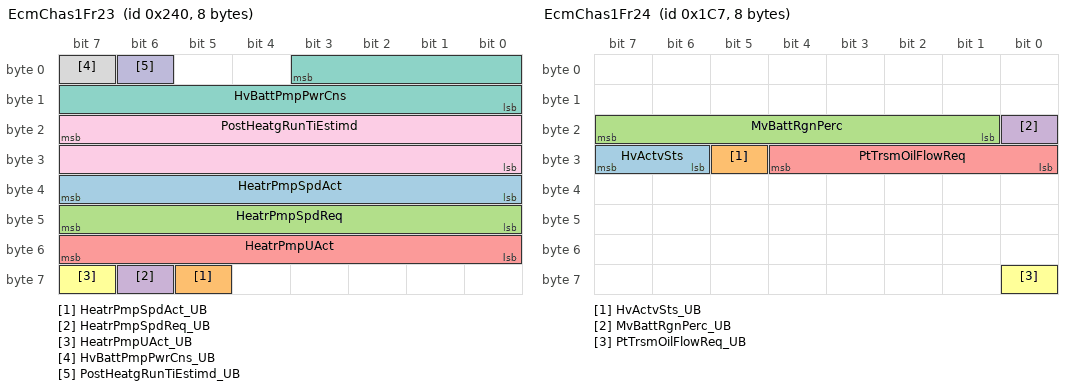
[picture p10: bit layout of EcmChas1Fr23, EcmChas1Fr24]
BO_ 576 EcmChas1Fr23: 8 ECM
 SG_ HeatrPmpSpdAct : 39|8@0+ (1.0,0.0) [0.0|254.0] "Unitless" VDDM
 SG_ HeatrPmpSpdAct_UB : 61|1@0+ (1,0) [0|1] "" VDDM
 SG_ HeatrPmpSpdReq : 47|8@0+ (1.0,0.0) [0.0|254.0] "Unitless" VDDM
 SG_ HeatrPmpSpdReq_UB : 62|1@0+ (1,0) [0|1] "" VDDM
 SG_ HeatrPmpUAct : 55|8@0+ (0.1,0.0) [0.0|25.0] "Volt" VDDM
 SG_ HeatrPmpUAct_UB : 63|1@0+ (1,0) [0|1] "" VDDM
 SG_ HvBattPmpPwrCns : 3|12@0+ (1.0,0.0) [0.0|4095.0] "W" VDDM
 SG_ HvBattPmpPwrCns_UB : 7|1@0+ (1,0) [0|1] "" VDDM
 SG_ PostHeatgRunTiEstimd : 23|16@0+ (1.0,0.0) [0.0|65535.0] "Unitless" VDDM
 SG_ PostHeatgRunTiEstimd_UB : 6|1@0+ (1,0) [0|1] "" VDDM

BO_ 455 EcmChas1Fr24: 8 ECM
 SG_ HvActvSts : 31|2@0+ (1,0) [0|3] "" VDDM
 SG_ HvActvSts_UB : 29|1@0+ (1,0) [0|1] "" VDDM
 SG_ MvBattRgnPerc : 23|7@0+ (1.0,0.0) [0.0|100.0] "%" VDDM
 SG_ MvBattRgnPerc_UB : 16|1@0+ (1,0) [0|1] "" VDDM
 SG_ PtTrsmOilFlowReq : 28|5@0+ (1,0) [0|31] "" TCM
 SG_ PtTrsmOilFlowReq_UB : 56|1@0+ (1,0) [0|1] "" TCM

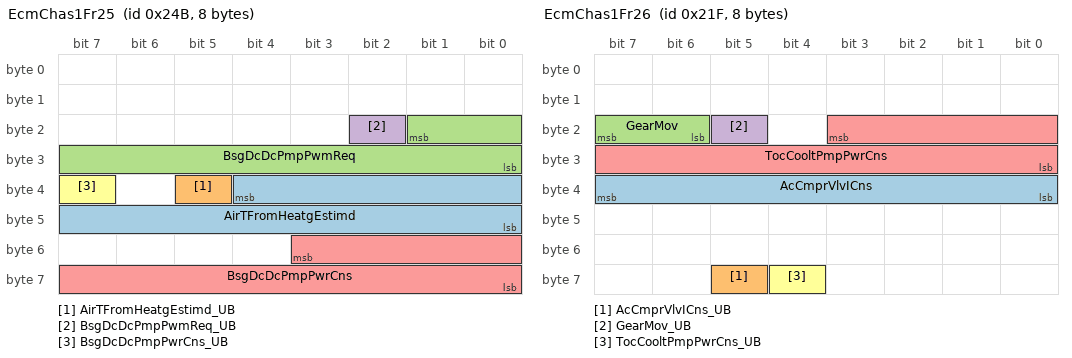
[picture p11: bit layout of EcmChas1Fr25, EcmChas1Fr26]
BO_ 587 EcmChas1Fr25: 8 ECM
 SG_ AirTFromHeatgEstimd : 36|13@0- (0.1,0.0) [-256.0|255.9] "degC" VDDM
 SG_ AirTFromHeatgEstimd_UB : 37|1@0+ (1,0) [0|1] "" VDDM
 SG_ BsgDcDcPmpPwmReq : 17|10@0+ (0.1,0.0) [0.0|100.0] "%" VDDM
 SG_ BsgDcDcPmpPwmReq_UB : 18|1@0+ (1,0) [0|1] "" VDDM
 SG_ BsgDcDcPmpPwrCns : 51|12@0+ (1.0,0.0) [0.0|4095.0] "W" VDDM
 SG_ BsgDcDcPmpPwrCns_UB : 39|1@0+ (1,0) [0|1] "" VDDM

BO_ 543 EcmChas1Fr26: 8 ECM
 SG_ AcCmprVlvICns : 39|8@0+ (0.05,0.0) [0.0|12.600000000000001] "A" VDDM
 SG_ AcCmprVlvICns_UB : 61|1@0+ (1,0) [0|1] "" VDDM
 SG_ GearMov : 23|2@0+ (1,0) [0|3] "" VDDM
 SG_ GearMov_UB : 21|1@0+ (1,0) [0|1] "" VDDM
 SG_ TocCooltPmpPwrCns : 19|12@0+ (1.0,0.0) [0.0|4095.0] "W" VDDM
 SG_ TocCooltPmpPwrCns_UB : 60|1@0+ (1,0) [0|1] "" VDDM

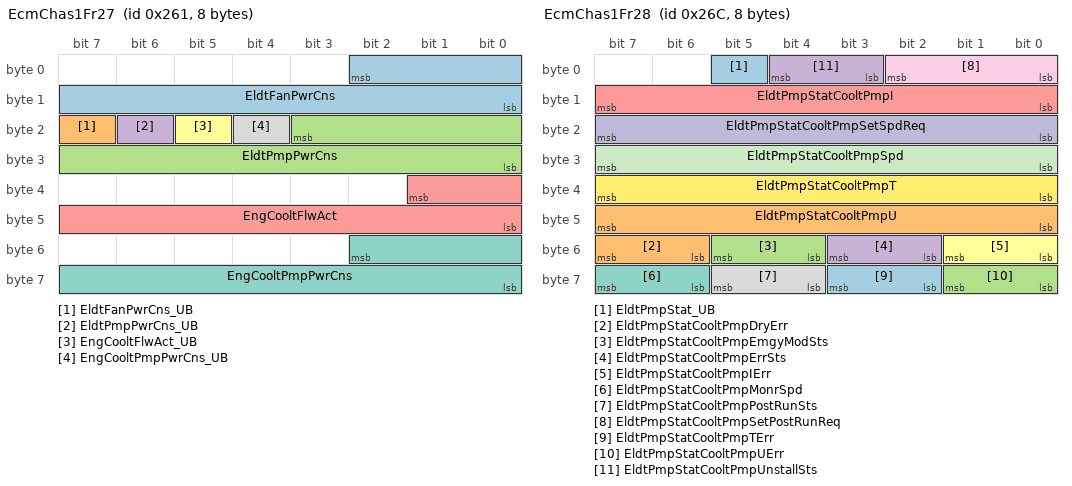
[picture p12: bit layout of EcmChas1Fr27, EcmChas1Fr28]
BO_ 609 EcmChas1Fr27: 8 ECM
 SG_ EldtFanPwrCns : 2|11@0+ (1.0,0.0) [0.0|2047.0] "W" VDDM
 SG_ EldtFanPwrCns_UB : 23|1@0+ (1,0) [0|1] "" VDDM
 SG_ EldtPmpPwrCns : 19|12@0+ (1.0,0.0) [0.0|4095.0] "W" VDDM
 SG_ EldtPmpPwrCns_UB : 22|1@0+ (1,0) [0|1] "" VDDM
 SG_ EngCooltFlwAct : 33|10@0+ (0.1,0.0) [0.0|102.30000000000001] "L / min" VDDM
 SG_ EngCooltFlwAct_UB : 21|1@0+ (1,0) [0|1] "" VDDM
 SG_ EngCooltPmpPwrCns : 50|11@0+ (1.0,0.0) [0.0|2047.0] "W" VDDM
 SG_ EngCooltPmpPwrCns_UB : 20|1@0+ (1,0) [0|1] "" VDDM

BO_ 620 EcmChas1Fr28: 8 ECM
 SG_ EldtPmpStat_UB : 5|1@0+ (1,0) [0|1] "" VDDM
 SG_ EldtPmpStatCooltPmpDryErr : 55|2@0+ (1,0) [0|3] "" VDDM
 SG_ EldtPmpStatCooltPmpEmgyModSts : 53|2@0+ (1,0) [0|3] "" VDDM
 SG_ EldtPmpStatCooltPmpErrSts : 51|2@0+ (1,0) [0|3] "" VDDM
 SG_ EldtPmpStatCooltPmpI : 15|8@0+ (0.2,0.0) [0.0|50.800000000000004] "A" VDDM
 SG_ EldtPmpStatCooltPmpIErr : 49|2@0+ (1,0) [0|3] "" VDDM
 SG_ EldtPmpStatCooltPmpMonrSpd : 63|2@0+ (1,0) [0|3] "" VDDM
 SG_ EldtPmpStatCooltPmpPostRunSts : 61|2@0+ (1,0) [0|3] "" VDDM
 SG_ EldtPmpStatCooltPmpSetPostRunReq : 2|3@0+ (1,0) [0|7] "" VDDM
 SG_ EldtPmpStatCooltPmpSetSpdReq : 23|8@0+ (1.0,0.0) [0.0|254.0] "Unitless" VDDM
 SG_ EldtPmpStatCooltPmpSpd : 31|8@0+ (1.0,0.0) [0.0|254.0] "Unitless" VDDM
 SG_ EldtPmpStatCooltPmpT : 39|8@0+ (1.0,-50.0) [-50.0|200.0] "degC" VDDM
 SG_ EldtPmpStatCooltPmpTErr : 59|2@0+ (1,0) [0|3] "" VDDM
 SG_ EldtPmpStatCooltPmpU : 47|8@0+ (0.1,0.0) [0.0|25.0] "Volt" VDDM
 SG_ EldtPmpStatCooltPmpUErr : 57|2@0+ (1,0) [0|3] "" VDDM
 SG_ EldtPmpStatCooltPmpUnstallSts : 4|2@0+ (1,0) [0|3] "" VDDM

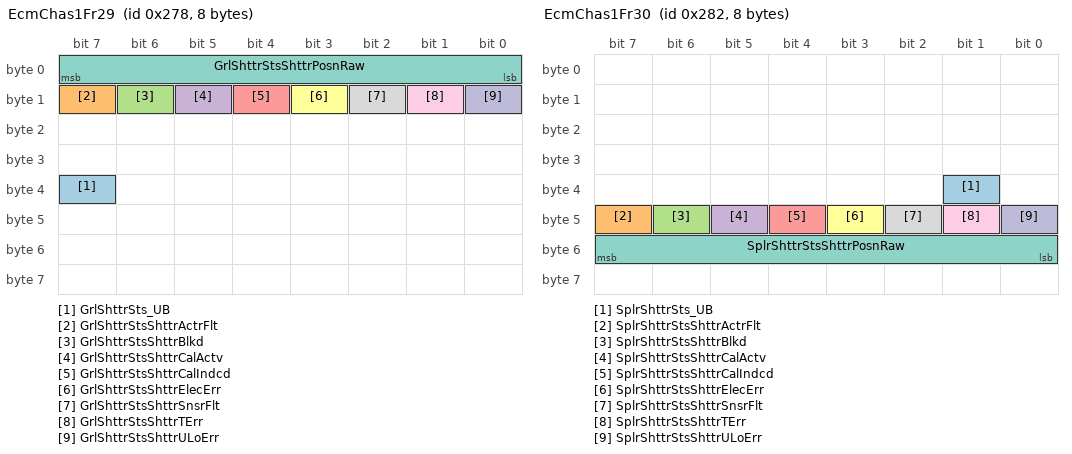
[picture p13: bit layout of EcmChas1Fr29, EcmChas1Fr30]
BO_ 632 EcmChas1Fr29: 8 ECM
 SG_ GrlShttrSts_UB : 39|1@0+ (1,0) [0|1] "" VDDM
 SG_ GrlShttrStsShttrActrFlt : 15|1@0+ (1,0) [0|1] "" VDDM
 SG_ GrlShttrStsShttrBlkd : 14|1@0+ (1,0) [0|1] "" VDDM
 SG_ GrlShttrStsShttrCalActv : 13|1@0+ (1,0) [0|1] "" VDDM
 SG_ GrlShttrStsShttrCalIndcd : 12|1@0+ (1,0) [0|1] "" VDDM
 SG_ GrlShttrStsShttrElecErr : 11|1@0+ (1,0) [0|1] "" VDDM
 SG_ GrlShttrStsShttrPosnRaw : 7|8@0+ (1.0,0.0) [0.0|255.0] "Unitless" VDDM
 SG_ GrlShttrStsShttrSnsrFlt : 10|1@0+ (1,0) [0|1] "" VDDM
 SG_ GrlShttrStsShttrTErr : 9|1@0+ (1,0) [0|1] "" VDDM
 SG_ GrlShttrStsShttrULoErr : 8|1@0+ (1,0) [0|1] "" VDDM

BO_ 642 EcmChas1Fr30: 8 ECM
 SG_ SplrShttrSts_UB : 33|1@0+ (1,0) [0|1] "" VDDM
 SG_ SplrShttrStsShttrActrFlt : 47|1@0+ (1,0) [0|1] "" VDDM
 SG_ SplrShttrStsShttrBlkd : 46|1@0+ (1,0) [0|1] "" VDDM
 SG_ SplrShttrStsShttrCalActv : 45|1@0+ (1,0) [0|1] "" VDDM
 SG_ SplrShttrStsShttrCalIndcd : 44|1@0+ (1,0) [0|1] "" VDDM
 SG_ SplrShttrStsShttrElecErr : 43|1@0+ (1,0) [0|1] "" VDDM
 SG_ SplrShttrStsShttrPosnRaw : 55|8@0+ (1.0,0.0) [0.0|255.0] "Unitless" VDDM
 SG_ SplrShttrStsShttrSnsrFlt : 42|1@0+ (1,0) [0|1] "" VDDM
 SG_ SplrShttrStsShttrTErr : 41|1@0+ (1,0) [0|1] "" VDDM
 SG_ SplrShttrStsShttrULoErr : 40|1@0+ (1,0) [0|1] "" VDDM

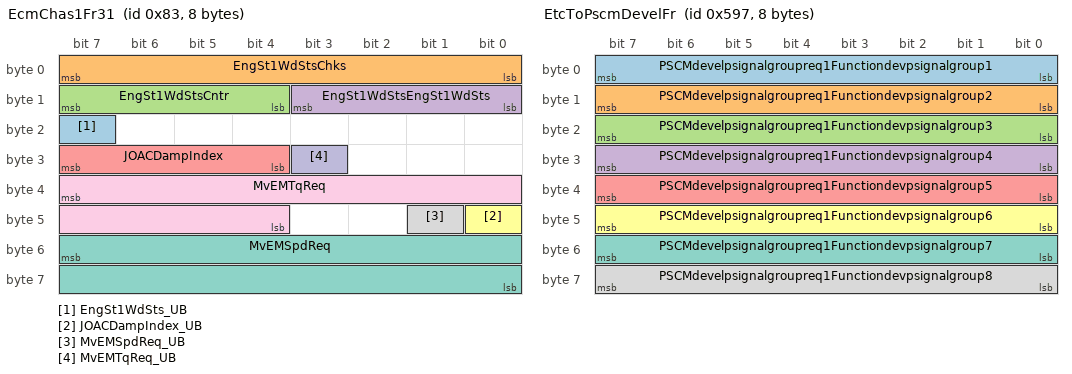
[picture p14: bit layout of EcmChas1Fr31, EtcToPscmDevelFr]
BO_ 131 EcmChas1Fr31: 8 ECM
 SG_ EngSt1WdSts_UB : 23|1@0+ (1,0) [0|1] "" MVEM,TCM,VDDM
 SG_ EngSt1WdStsChks : 7|8@0+ (1.0,0.0) [0.0|255.0] "Unitless" MVEM,TCM,VDDM
 SG_ EngSt1WdStsCntr : 15|4@0+ (1.0,0.0) [0.0|15.0] "Unitless" MVEM,TCM,VDDM
 SG_ EngSt1WdStsEngSt1WdSts : 11|4@0+ (1,0) [0|15] "" MVEM,TCM,VDDM
 SG_ JOACDampIndex : 31|4@0+ (1,0) [0|15] "" MVEM
 SG_ JOACDampIndex_UB : 40|1@0+ (1,0) [0|1] "" MVEM
 SG_ MvEMSpdReq : 55|16@0+ (1.0,-10000.0) [-10000.0|55535.0] "rpm" MVEM
 SG_ MvEMSpdReq_UB : 41|1@0+ (1,0) [0|1] "" MVEM
 SG_ MvEMTqReq : 39|12@0+ (0.1,-70.0) [-70.0|70.0] "NewtonMeter" MVEM
 SG_ MvEMTqReq_UB : 27|1@0+ (1,0) [0|1] "" MVEM

BO_ 752 EcmChas1Fr37: 8 ECM
 SG_ EngSt1WdSts1 : 11|4@0+ (1,0) [0|15] "" SAS
 SG_ EngSt1WdSts1_UB : 41|1@0+ (1,0) [0|1] "" SAS

BO_ 1296 EcmChas1NMFr: 8 ECM
 SG_ PNC16_ECM : 16|1@0+ (1,0) [0|0] "" Vector_XXX
 SG_ PNC17_ECM : 17|1@0+ (1,0) [0|0] "" Vector_XXX
 SG_ PNC18_ECM : 18|1@0+ (1,0) [0|0] "" Vector_XXX
 SG_ PNC19_ECM : 19|1@0+ (1,0) [0|0] "" Vector_XXX
 SG_ PNC20_ECM : 20|1@0+ (1,0) [0|0] "" Vector_XXX
 SG_ PNC21_ECM : 21|1@0+ (1,0) [0|0] "" Vector_XXX
 SG_ PNC22_ECM : 22|1@0+ (1,0) [0|0] "" Vector_XXX
 SG_ PNC23_ECM : 23|1@0+ (1,0) [0|0] "" Vector_XXX
 SG_ PNC24_ECM : 24|1@0+ (1,0) [0|0] "" Vector_XXX
 SG_ PNC25_ECM : 25|1@0+ (1,0) [0|0] "" Vector_XXX
 SG_ PNC26_ECM : 26|1@0+ (1,0) [0|0] "" Vector_XXX
 SG_ PNC27_ECM : 27|1@0+ (1,0) [0|0] "" Vector_XXX
 SG_ PNC28_ECM : 28|1@0+ (1,0) [0|0] "" Vector_XXX
 SG_ PNC29_ECM : 29|1@0+ (1,0) [0|0] "" Vector_XXX
 SG_ PNC30_ECM : 30|1@0+ (1,0) [0|0] "" Vector_XXX
 SG_ PNC31_ECM : 31|1@0+ (1,0) [0|0] "" Vector_XXX
 SG_ PNC32_ECM : 32|1@0+ (1,0) [0|0] "" Vector_XXX
 SG_ PNC33_ECM : 33|1@0+ (1,0) [0|0] "" Vector_XXX
 SG_ PNC34_ECM : 34|1@0+ (1,0) [0|0] "" Vector_XXX
 SG_ PNC35_ECM : 35|1@0+ (1,0) [0|0] "" Vector_XXX
 SG_ PNC36_ECM : 36|1@0+ (1,0) [0|0] "" Vector_XXX
 SG_ PNC37_ECM : 37|1@0+ (1,0) [0|0] "" Vector_XXX
 SG_ PNC38_ECM : 38|1@0+ (1,0) [0|0] "" Vector_XXX
 SG_ PNC39_ECM : 39|1@0+ (1,0) [0|0] "" Vector_XXX
 SG_ NM_PNI_ECM : 14|1@0+ (1,0) [0|0] "" Vector_XXX
 SG_ NM_AW_ECM : 12|1@0+ (1,0) [0|0] "" Vector_XXX
 SG_ NM_CS_ECM : 11|1@0+ (1,0) [0|0] "" Vector_XXX
 SG_ NM_RMR_ECM : 8|1@0+ (1,0) [0|0] "" Vector_XXX
 SG_ NM_NodeID_ECM : 7|8@0+ (1,0) [0|0] "" Vector_XXX

BO_ 1429 EtcToMvemXcpFr01: 8 ETC

BO_ 1424 EtcToMvemXcpFr02: 8 ETC

BO_ 1425 EtcToMvemXcpFr03: 8 ETC

BO_ 1441 EtcToPscm1cChas1XcpFr01: 8 ETC

BO_ 1409 EtcToPscmChas1XcpFr01: 8 ETC

BO_ 1416 EtcToPscmChas1XcpFr02: 8 ETC

BO_ 1418 EtcToPscmChas1XcpFr03: 8 ETC

BO_ 1420 EtcToPscmChas1XcpFr04: 8 ETC

BO_ 1431 EtcToPscmDevelFr: 8 ETC
 SG_ PSCMdevelpsignalgroupreq1Functiondevpsignalgroup1 : 7|8@0+ (1.0,0.0) [0.0|255.0] "Unitless" PSCM1
 SG_ PSCMdevelpsignalgroupreq1Functiondevpsignalgroup2 : 15|8@0+ (1.0,0.0) [0.0|255.0] "Unitless" PSCM1
 SG_ PSCMdevelpsignalgroupreq1Functiondevpsignalgroup3 : 23|8@0+ (1.0,0.0) [0.0|255.0] "Unitless" PSCM1
 SG_ PSCMdevelpsignalgroupreq1Functiondevpsignalgroup4 : 31|8@0+ (1.0,0.0) [0.0|255.0] "Unitless" PSCM1
 SG_ PSCMdevelpsignalgroupreq1Functiondevpsignalgroup5 : 39|8@0+ (1.0,0.0) [0.0|255.0] "Unitless" PSCM1
 SG_ PSCMdevelpsignalgroupreq1Functiondevpsignalgroup6 : 47|8@0+ (1.0,0.0) [0.0|255.0] "Unitless" PSCM1
 SG_ PSCMdevelpsignalgroupreq1Functiondevpsignalgroup7 : 55|8@0+ (1.0,0.0) [0.0|255.0] "Unitless" PSCM1
 SG_ PSCMdevelpsignalgroupreq1Functiondevpsignalgroup8 : 63|8@0+ (1.0,0.0) [0.0|255.0] "Unitless" PSCM1

BO_ 1442 EtcToRasmChas1XcpFr01: 8 ETC

BO_ 1414 EtcToTcmXcpFr01: 8 ETC

BO_ 1411 EtcToTcmXcpFr02: 8 ETC

BO_ 1421 EtctoVddmBcmXCPFr01: 8 ETC

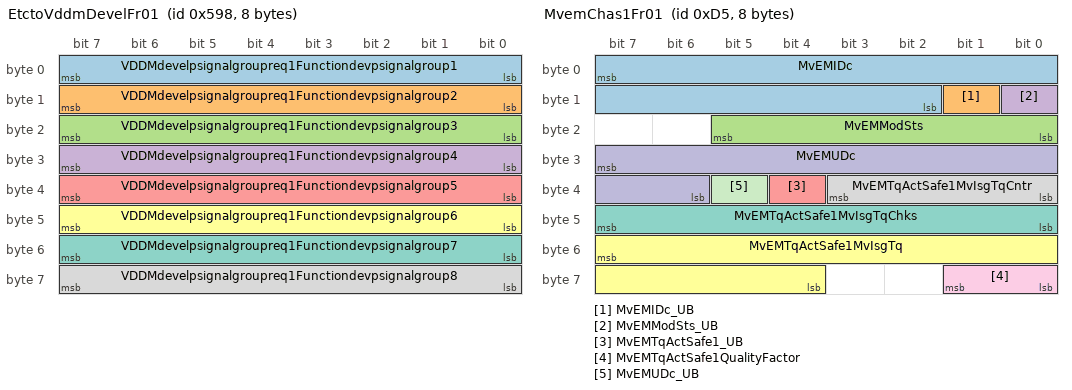
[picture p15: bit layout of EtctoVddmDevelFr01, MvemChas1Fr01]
BO_ 1432 EtctoVddmDevelFr01: 8 ETC
 SG_ VDDMdevelpsignalgroupreq1Functiondevpsignalgroup1 : 7|8@0+ (1.0,0.0) [0.0|255.0] "Unitless" VDDM
 SG_ VDDMdevelpsignalgroupreq1Functiondevpsignalgroup2 : 15|8@0+ (1.0,0.0) [0.0|255.0] "Unitless" VDDM
 SG_ VDDMdevelpsignalgroupreq1Functiondevpsignalgroup3 : 23|8@0+ (1.0,0.0) [0.0|255.0] "Unitless" VDDM
 SG_ VDDMdevelpsignalgroupreq1Functiondevpsignalgroup4 : 31|8@0+ (1.0,0.0) [0.0|255.0] "Unitless" VDDM
 SG_ VDDMdevelpsignalgroupreq1Functiondevpsignalgroup5 : 39|8@0+ (1.0,0.0) [0.0|255.0] "Unitless" VDDM
 SG_ VDDMdevelpsignalgroupreq1Functiondevpsignalgroup6 : 47|8@0+ (1.0,0.0) [0.0|255.0] "Unitless" VDDM
 SG_ VDDMdevelpsignalgroupreq1Functiondevpsignalgroup7 : 55|8@0+ (1.0,0.0) [0.0|255.0] "Unitless" VDDM
 SG_ VDDMdevelpsignalgroupreq1Functiondevpsignalgroup8 : 63|8@0+ (1.0,0.0) [0.0|255.0] "Unitless" VDDM

BO_ 1433 EtctoVddmDevelFr02: 8 ETC
 SG_ VDDMdevelpsignalgroupreq2Functiondevpsignalgroup1 : 7|8@0+ (1.0,0.0) [0.0|255.0] "Unitless" VDDM
 SG_ VDDMdevelpsignalgroupreq2Functiondevpsignalgroup2 : 15|8@0+ (1.0,0.0) [0.0|255.0] "Unitless" VDDM
 SG_ VDDMdevelpsignalgroupreq2Functiondevpsignalgroup3 : 23|8@0+ (1.0,0.0) [0.0|255.0] "Unitless" VDDM
 SG_ VDDMdevelpsignalgroupreq2Functiondevpsignalgroup4 : 31|8@0+ (1.0,0.0) [0.0|255.0] "Unitless" VDDM
 SG_ VDDMdevelpsignalgroupreq2Functiondevpsignalgroup5 : 39|8@0+ (1.0,0.0) [0.0|255.0] "Unitless" VDDM
 SG_ VDDMdevelpsignalgroupreq2Functiondevpsignalgroup6 : 47|8@0+ (1.0,0.0) [0.0|255.0] "Unitless" VDDM
 SG_ VDDMdevelpsignalgroupreq2Functiondevpsignalgroup7 : 55|8@0+ (1.0,0.0) [0.0|255.0] "Unitless" VDDM
 SG_ VDDMdevelpsignalgroupreq2Functiondevpsignalgroup8 : 63|8@0+ (1.0,0.0) [0.0|255.0] "Unitless" VDDM

BO_ 213 MvemChas1Fr01: 8 MVEM
 SG_ MvEMIDc : 7|14@0+ (1.0,-500.0) [-500.0|9500.0] "A" ECM
 SG_ MvEMIDc_UB : 9|1@0+ (1,0) [0|1] "" ECM
 SG_ MvEMModSts : 21|6@0+ (1,0) [0|63] "" ECM,VDDM
 SG_ MvEMModSts_UB : 8|1@0+ (1,0) [0|1] "" ECM,VDDM
 SG_ MvEMTqActSafe1_UB : 36|1@0+ (1,0) [0|1] "" ECM
 SG_ MvEMTqActSafe1MvIsgTq : 55|12@0+ (0.1,-70.0) [-70.0|70.0] "NewtonMeter" ECM
 SG_ MvEMTqActSafe1MvIsgTqChks : 47|8@0+ (1.0,0.0) [0.0|255.0] "Unitless" ECM
 SG_ MvEMTqActSafe1MvIsgTqCntr : 35|4@0+ (1.0,0.0) [0.0|15.0] "Unitless" ECM
 SG_ MvEMTqActSafe1QualityFactor : 57|2@0+ (1,0) [0|3] "" ECM
 SG_ MvEMUDc : 31|10@0+ (0.1,0.0) [0.0|102.30000000000001] "Volt" ECM
 SG_ MvEMUDc_UB : 37|1@0+ (1,0) [0|1] "" ECM

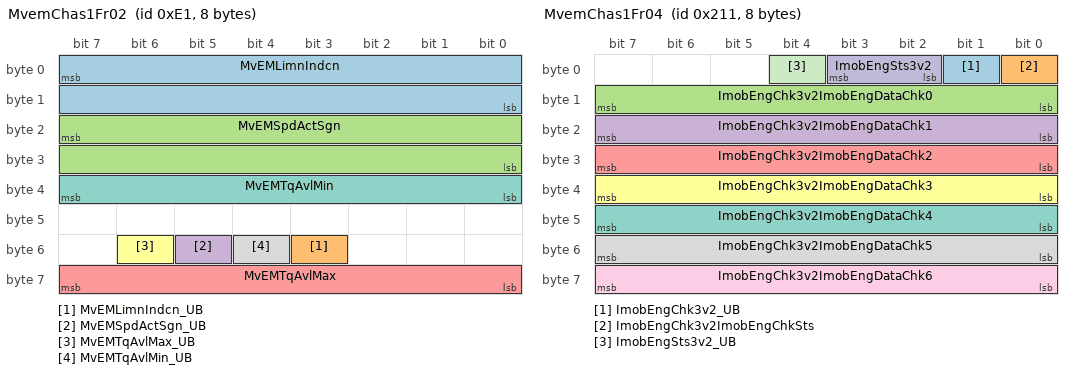
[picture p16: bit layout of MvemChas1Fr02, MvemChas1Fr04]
BO_ 225 MvemChas1Fr02: 8 MVEM
 SG_ MvEMLimnIndcn : 7|16@0+ (1.0,0.0) [0.0|65535.0] "Unitless" ECM
 SG_ MvEMLimnIndcn_UB : 51|1@0+ (1,0) [0|1] "" ECM
 SG_ MvEMSpdActSgn : 23|16@0+ (1.0,-10000.0) [-10000.0|55535.0] "rpm" ECM
 SG_ MvEMSpdActSgn_UB : 53|1@0+ (1,0) [0|1] "" ECM
 SG_ MvEMTqAvlMax : 63|8@0+ (0.5,0.0) [0.0|70.0] "NewtonMeter" ECM
 SG_ MvEMTqAvlMax_UB : 54|1@0+ (1,0) [0|1] "" ECM
 SG_ MvEMTqAvlMin : 39|8@0+ (0.5,-70.0) [-70.0|0.0] "NewtonMeter" ECM
 SG_ MvEMTqAvlMin_UB : 52|1@0+ (1,0) [0|1] "" ECM

BO_ 499 MvemChas1Fr03: 8 MVEM
 SG_ MvEMFltSts : 47|16@0+ (1.0,0.0) [0.0|65535.0] "Unitless" ECM
 SG_ MvEMFltSts_UB : 37|1@0+ (1,0) [0|1] "" ECM
 SG_ MvEMTRate : 6|7@0+ (1.0,0.0) [0.0|127.0] "%" ECM,VDDM
 SG_ MvEMTRate_UB : 7|1@0+ (1,0) [0|1] "" ECM,VDDM

BO_ 529 MvemChas1Fr04: 8 MVEM
 SG_ ImobEngChk3v2_UB : 1|1@0+ (1,0) [0|1] "" VDDM
 SG_ ImobEngChk3v2ImobEngChkSts : 0|1@0+ (1,0) [0|1] "" VDDM
 SG_ ImobEngChk3v2ImobEngDataChk0 : 15|8@0+ (1.0,0.0) [0.0|255.0] "Unitless" VDDM
 SG_ ImobEngChk3v2ImobEngDataChk1 : 23|8@0+ (1.0,0.0) [0.0|255.0] "Unitless" VDDM
 SG_ ImobEngChk3v2ImobEngDataChk2 : 31|8@0+ (1.0,0.0) [0.0|255.0] "Unitless" VDDM
 SG_ ImobEngChk3v2ImobEngDataChk3 : 39|8@0+ (1.0,0.0) [0.0|255.0] "Unitless" VDDM
 SG_ ImobEngChk3v2ImobEngDataChk4 : 47|8@0+ (1.0,0.0) [0.0|255.0] "Unitless" VDDM
 SG_ ImobEngChk3v2ImobEngDataChk5 : 55|8@0+ (1.0,0.0) [0.0|255.0] "Unitless" VDDM
 SG_ ImobEngChk3v2ImobEngDataChk6 : 63|8@0+ (1.0,0.0) [0.0|255.0] "Unitless" VDDM
 SG_ ImobEngSts3v2 : 3|2@0+ (1,0) [0|3] "" VDDM
 SG_ ImobEngSts3v2_UB : 4|1@0+ (1,0) [0|1] "" VDDM

BO_ 1330 MvemChas1NMFr: 8 MVEM
 SG_ PNC16_MVEM : 16|1@0+ (1,0) [0|0] "" ECM
 SG_ PNC17_MVEM : 17|1@0+ (1,0) [0|0] "" ECM
 SG_ PNC18_MVEM : 18|1@0+ (1,0) [0|0] "" ECM
 SG_ PNC19_MVEM : 19|1@0+ (1,0) [0|0] "" ECM
 SG_ PNC20_MVEM : 20|1@0+ (1,0) [0|0] "" ECM
 SG_ PNC21_MVEM : 21|1@0+ (1,0) [0|0] "" ECM
 SG_ PNC22_MVEM : 22|1@0+ (1,0) [0|0] "" ECM
 SG_ PNC23_MVEM : 23|1@0+ (1,0) [0|0] "" ECM
 SG_ PNC24_MVEM : 24|1@0+ (1,0) [0|0] "" ECM
 SG_ PNC25_MVEM : 25|1@0+ (1,0) [0|0] "" ECM
 SG_ PNC26_MVEM : 26|1@0+ (1,0) [0|0] "" ECM
 SG_ PNC27_MVEM : 27|1@0+ (1,0) [0|0] "" ECM
 SG_ PNC28_MVEM : 28|1@0+ (1,0) [0|0] "" ECM
 SG_ PNC29_MVEM : 29|1@0+ (1,0) [0|0] "" ECM
 SG_ PNC30_MVEM : 30|1@0+ (1,0) [0|0] "" ECM
 SG_ PNC31_MVEM : 31|1@0+ (1,0) [0|0] "" ECM
 SG_ PNC32_MVEM : 32|1@0+ (1,0) [0|0] "" ECM
 SG_ PNC33_MVEM : 33|1@0+ (1,0) [0|0] "" ECM
 SG_ PNC34_MVEM : 34|1@0+ (1,0) [0|0] "" ECM
 SG_ PNC35_MVEM : 35|1@0+ (1,0) [0|0] "" ECM
 SG_ PNC36_MVEM : 36|1@0+ (1,0) [0|0] "" ECM
 SG_ PNC37_MVEM : 37|1@0+ (1,0) [0|0] "" ECM
 SG_ PNC38_MVEM : 38|1@0+ (1,0) [0|0] "" ECM
 SG_ PNC39_MVEM : 39|1@0+ (1,0) [0|0] "" ECM
 SG_ NM_PNI_MVEM : 14|1@0+ (1,0) [0|0] "" ECM
 SG_ NM_AW_MVEM : 12|1@0+ (1,0) [0|0] "" ECM
 SG_ NM_CS_MVEM : 11|1@0+ (1,0) [0|0] "" ECM
 SG_ NM_RMR_MVEM : 8|1@0+ (1,0) [0|0] "" ECM
 SG_ NM_NodeID_MVEM : 7|8@0+ (1,0) [0|0] "" ECM

BO_ 1426 MvemToEtcXcpFr01: 8 MVEM

BO_ 1427 MvemToEtcXcpFr02: 8 MVEM

BO_ 1428 MvemToEtcXcpFr03: 8 MVEM

BO_ 235 PasChas1Fr02: 8 PAS
 SG_ PrkgPinionAgReqGroup_UB : 24|1@0+ (1,0) [0|1] "" PSCM1
 SG_ PrkgPinionAgReqGroupParkAssiPinionAgReq : 23|15@0+ (0.000976563,-14.5) [-14.5|17.499039821] "rad" PSCM1
 SG_ PrkgPinionAgReqGroupParkAssiPinionAgReqChks : 7|8@0+ (1.0,0.0) [0.0|255.0] "Unitless" PSCM1
 SG_ PrkgPinionAgReqGroupParkAssiPinionAgReqCntr : 15|4@0+ (1.0,0.0) [0.0|15.0] "Unitless" PSCM1
 SG_ PrkgPinionAgReqGroupQF : 11|2@0+ (1,0) [0|3] "" PSCM1

BO_ 1320 PasChas1NMFr: 8 PAS
 SG_ PNC16_PAS : 16|1@0+ (1,0) [0|0] "" MVEM
 SG_ PNC17_PAS : 17|1@0+ (1,0) [0|0] "" MVEM
 SG_ PNC18_PAS : 18|1@0+ (1,0) [0|0] "" MVEM
 SG_ PNC19_PAS : 19|1@0+ (1,0) [0|0] "" MVEM
 SG_ PNC20_PAS : 20|1@0+ (1,0) [0|0] "" MVEM
 SG_ PNC21_PAS : 21|1@0+ (1,0) [0|0] "" MVEM
 SG_ PNC22_PAS : 22|1@0+ (1,0) [0|0] "" MVEM
 SG_ PNC23_PAS : 23|1@0+ (1,0) [0|0] "" MVEM
 SG_ PNC24_PAS : 24|1@0+ (1,0) [0|0] "" MVEM
 SG_ PNC25_PAS : 25|1@0+ (1,0) [0|0] "" MVEM
 SG_ PNC26_PAS : 26|1@0+ (1,0) [0|0] "" MVEM
 SG_ PNC27_PAS : 27|1@0+ (1,0) [0|0] "" MVEM
 SG_ PNC28_PAS : 28|1@0+ (1,0) [0|0] "" MVEM
 SG_ PNC29_PAS : 29|1@0+ (1,0) [0|0] "" MVEM
 SG_ PNC30_PAS : 30|1@0+ (1,0) [0|0] "" MVEM
 SG_ PNC31_PAS : 31|1@0+ (1,0) [0|0] "" MVEM
 SG_ PNC32_PAS : 32|1@0+ (1,0) [0|0] "" MVEM
 SG_ PNC33_PAS : 33|1@0+ (1,0) [0|0] "" MVEM
 SG_ PNC34_PAS : 34|1@0+ (1,0) [0|0] "" MVEM
 SG_ PNC35_PAS : 35|1@0+ (1,0) [0|0] "" MVEM
 SG_ PNC36_PAS : 36|1@0+ (1,0) [0|0] "" MVEM
 SG_ PNC37_PAS : 37|1@0+ (1,0) [0|0] "" MVEM
 SG_ PNC38_PAS : 38|1@0+ (1,0) [0|0] "" MVEM
 SG_ PNC39_PAS : 39|1@0+ (1,0) [0|0] "" MVEM
 SG_ NM_PNI_PAS : 14|1@0+ (1,0) [0|0] "" MVEM
 SG_ NM_AW_PAS : 12|1@0+ (1,0) [0|0] "" MVEM
 SG_ NM_CS_PAS : 11|1@0+ (1,0) [0|0] "" MVEM
 SG_ NM_RMR_PAS : 8|1@0+ (1,0) [0|0] "" MVEM
 SG_ NM_NodeID_PAS : 7|8@0+ (1,0) [0|0] "" MVEM

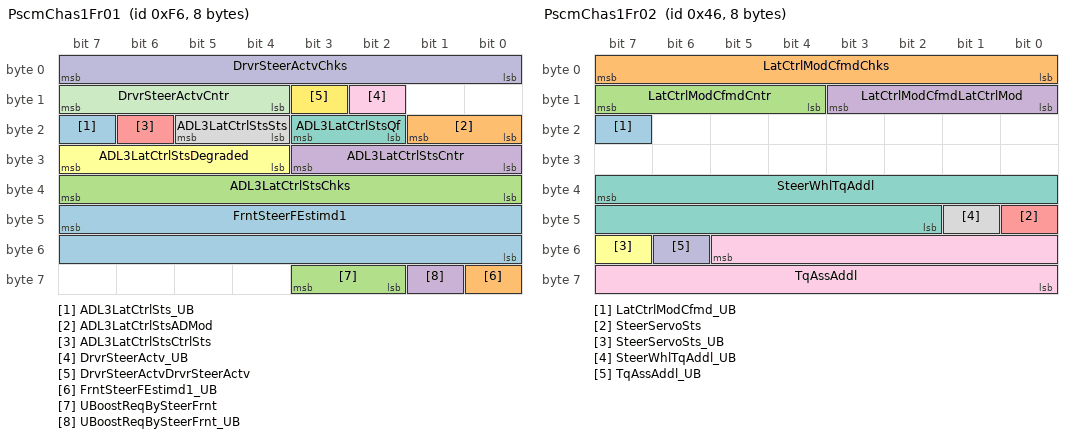
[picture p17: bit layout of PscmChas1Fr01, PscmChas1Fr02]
BO_ 246 PscmChas1Fr01: 8 PSCM1
 SG_ ADL3LatCtrlSts_UB : 23|1@0+ (1,0) [0|1] "" ASDM
 SG_ ADL3LatCtrlStsADMod : 17|2@0+ (1,0) [0|3] "" ASDM
 SG_ ADL3LatCtrlStsChks : 39|8@0+ (1.0,0.0) [0.0|255.0] "Unitless" ASDM
 SG_ ADL3LatCtrlStsCntr : 27|4@0+ (1.0,0.0) [0.0|15.0] "Unitless" ASDM
 SG_ ADL3LatCtrlStsCtrlSts : 22|1@0+ (1,0) [0|1] "" ASDM
 SG_ ADL3LatCtrlStsDegraded : 31|4@0+ (1,0) [0|15] "" ASDM
 SG_ ADL3LatCtrlStsQf : 19|2@0+ (1,0) [0|3] "" ASDM
 SG_ ADL3LatCtrlStsSts : 21|2@0+ (1,0) [0|3] "" ASDM
 SG_ DrvrSteerActv_UB : 10|1@0+ (1,0) [0|1] "" ASDM
 SG_ DrvrSteerActvChks : 7|8@0+ (1.0,0.0) [0.0|255.0] "Unitless" ASDM
 SG_ DrvrSteerActvCntr : 15|4@0+ (1.0,0.0) [0.0|15.0] "Unitless" ASDM
 SG_ DrvrSteerActvDrvrSteerActv : 11|1@0+ (1,0) [0|1] "" ASDM
 SG_ FrntSteerFEstimd1 : 47|16@0- (1.0,0.0) [-32768.0|32767.0] "N" VDDM
 SG_ FrntSteerFEstimd1_UB : 56|1@0+ (1,0) [0|1] "" VDDM
 SG_ UBoostReqBySteerFrnt : 59|2@0+ (1,0) [0|3] "" ECM,VDDM
 SG_ UBoostReqBySteerFrnt_UB : 57|1@0+ (1,0) [0|1] "" ECM,VDDM

BO_ 70 PscmChas1Fr02: 8 PSCM1
 SG_ LatCtrlModCfmd_UB : 23|1@0+ (1,0) [0|1] "" ASDM,VDDM
 SG_ LatCtrlModCfmdChks : 7|8@0+ (1.0,0.0) [0.0|255.0] "Unitless" ASDM,VDDM
 SG_ LatCtrlModCfmdCntr : 15|4@0+ (1.0,0.0) [0.0|15.0] "Unitless" ASDM,VDDM
 SG_ LatCtrlModCfmdLatCtrlMod : 11|4@0+ (1,0) [0|15] "" ASDM,VDDM
 SG_ SteerServoSts : 40|1@0+ (1,0) [0|1] "" ASDM,VDDM
 SG_ SteerServoSts_UB : 55|1@0+ (1,0) [0|1] "" ASDM,VDDM
 SG_ SteerWhlTqAddl : 39|14@0- (0.00390625,0.0) [-30.0|30.0] "NewtonMeter" ASDM,VDDM
 SG_ SteerWhlTqAddl_UB : 41|1@0+ (1,0) [0|1] "" ASDM,VDDM
 SG_ TqAssAddl : 53|14@0- (0.00390625,0.0) [-30.0|30.0] "NewtonMeter" ASDM
 SG_ TqAssAddl_UB : 54|1@0+ (1,0) [0|1] "" ASDM

BO_ 444 PscmChas1Fr03: 8 PSCM1
 SG_ DrvrSteerWhlHldGroup_UB : 1|1@0+ (1,0) [0|1] "" ASDM,VDDM
 SG_ DrvrSteerWhlHldGroupDrvrSteerWhlHld : 7|2@0+ (1,0) [0|3] "" ASDM,VDDM
 SG_ DrvrSteerWhlHldGroupDrvrSteerWhlHldQly : 5|4@0+ (1.0,0.0) [0.0|15.0] "Unitless" ASDM,VDDM
 SG_ SteerErrReq : 46|3@0+ (1,0) [0|7] "" VDDM
 SG_ SteerErrReq_UB : 47|1@0+ (1,0) [0|1] "" VDDM
 SG_ SteerExtFctSts_UB : 43|1@0+ (1,0) [0|1] "" ASDM
 SG_ SteerExtFctStsChks : 63|8@0+ (1.0,0.0) [0.0|255.0] "Unitless" ASDM
 SG_ SteerExtFctStsCntr : 51|4@0+ (1.0,0.0) [0.0|15.0] "Unitless" ASDM
 SG_ SteerExtFctStsDrvrSteerOvrd : 52|1@0+ (1,0) [0|1] "" ASDM
 SG_ SteerExtFctStsExtFctLowerLimActive : 53|1@0+ (1,0) [0|1] "" ASDM
 SG_ SteerExtFctStsExtFctRateLimActive : 54|1@0+ (1,0) [0|1] "" ASDM
 SG_ SteerExtFctStsExtFctUpperLimActive : 55|1@0+ (1,0) [0|1] "" ASDM
 SG_ SteerExtFctStsExtSafeLimActive : 40|1@0+ (1,0) [0|1] "" ASDM
 SG_ SteerExtFctStsLatAgReqNotInRange : 41|1@0+ (1,0) [0|1] "" ASDM
 SG_ SteerExtFctStsLatCtrlReqNotInRange : 42|1@0+ (1,0) [0|1] "" ASDM
 SG_ SteerStsToParkAssi : 15|3@0+ (1,0) [0|7] "" PAS,VDDM
 SG_ SteerStsToParkAssi_UB : 0|1@0+ (1,0) [0|1] "" PAS,VDDM

BO_ 955 PscmChas1Fr06: 8 PSCM1
 SG_ PinionSteerAgMax1 : 54|15@0- (0.0009765625,0.0) [-14.5|14.5] "rad" VDDM
 SG_ PinionSteerAgMax1_UB : 55|1@0+ (1,0) [0|1] "" VDDM

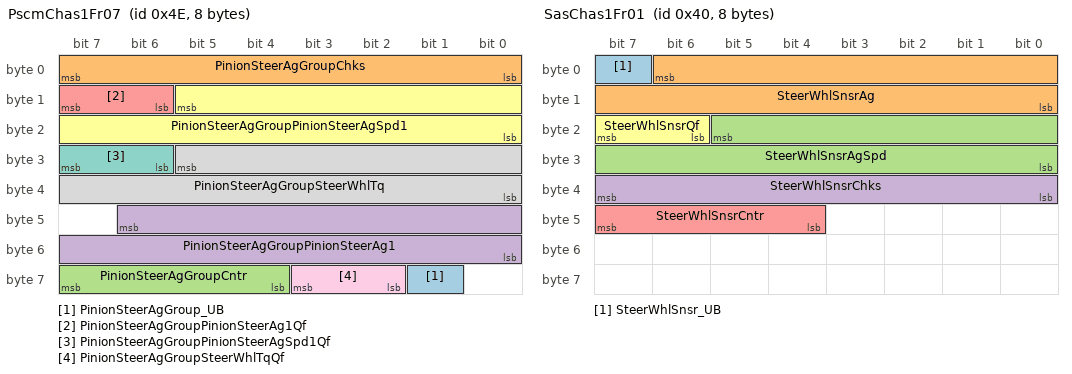
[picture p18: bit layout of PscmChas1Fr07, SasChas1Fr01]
BO_ 78 PscmChas1Fr07: 8 PSCM1
 SG_ PinionSteerAgGroup_UB : 57|1@0+ (1,0) [0|1] "" ASDM,PAS,VDDM
 SG_ PinionSteerAgGroupChks : 7|8@0+ (1.0,0.0) [0.0|255.0] "Unitless" ASDM,PAS,VDDM
 SG_ PinionSteerAgGroupCntr : 63|4@0+ (1.0,0.0) [0.0|15.0] "Unitless" ASDM,PAS,VDDM
 SG_ PinionSteerAgGroupPinionSteerAg1 : 46|15@0- (0.0009765625,0.0) [-14.5|14.5] "rad" ASDM,PAS,VDDM
 SG_ PinionSteerAgGroupPinionSteerAg1Qf : 15|2@0+ (1,0) [0|3] "" ASDM,PAS,VDDM
 SG_ PinionSteerAgGroupPinionSteerAgSpd1 : 13|14@0- (0.0078125,0.0) [-50.0|50.0] "rad/s" ASDM,PAS,VDDM
 SG_ PinionSteerAgGroupPinionSteerAgSpd1Qf : 31|2@0+ (1,0) [0|3] "" ASDM,PAS,VDDM
 SG_ PinionSteerAgGroupSteerWhlTq : 29|14@0- (0.00390625,0.0) [-30.0|30.0] "NewtonMeter" ASDM,PAS,VDDM
 SG_ PinionSteerAgGroupSteerWhlTqQf : 59|2@0+ (1,0) [0|3] "" ASDM,PAS,VDDM

BO_ 1315 PscmChas1NMFr: 8 PSCM1
 SG_ PNC16_PSCM1 : 16|1@0+ (1,0) [0|0] "" Vector_XXX
 SG_ PNC17_PSCM1 : 17|1@0+ (1,0) [0|0] "" Vector_XXX
 SG_ PNC18_PSCM1 : 18|1@0+ (1,0) [0|0] "" Vector_XXX
 SG_ PNC19_PSCM1 : 19|1@0+ (1,0) [0|0] "" Vector_XXX
 SG_ PNC20_PSCM1 : 20|1@0+ (1,0) [0|0] "" Vector_XXX
 SG_ PNC21_PSCM1 : 21|1@0+ (1,0) [0|0] "" Vector_XXX
 SG_ PNC22_PSCM1 : 22|1@0+ (1,0) [0|0] "" Vector_XXX
 SG_ PNC23_PSCM1 : 23|1@0+ (1,0) [0|0] "" Vector_XXX
 SG_ PNC24_PSCM1 : 24|1@0+ (1,0) [0|0] "" Vector_XXX
 SG_ PNC25_PSCM1 : 25|1@0+ (1,0) [0|0] "" Vector_XXX
 SG_ PNC26_PSCM1 : 26|1@0+ (1,0) [0|0] "" Vector_XXX
 SG_ PNC27_PSCM1 : 27|1@0+ (1,0) [0|0] "" Vector_XXX
 SG_ PNC28_PSCM1 : 28|1@0+ (1,0) [0|0] "" Vector_XXX
 SG_ PNC29_PSCM1 : 29|1@0+ (1,0) [0|0] "" Vector_XXX
 SG_ PNC30_PSCM1 : 30|1@0+ (1,0) [0|0] "" Vector_XXX
 SG_ PNC31_PSCM1 : 31|1@0+ (1,0) [0|0] "" Vector_XXX
 SG_ PNC32_PSCM1 : 32|1@0+ (1,0) [0|0] "" Vector_XXX
 SG_ PNC33_PSCM1 : 33|1@0+ (1,0) [0|0] "" Vector_XXX
 SG_ PNC34_PSCM1 : 34|1@0+ (1,0) [0|0] "" Vector_XXX
 SG_ PNC35_PSCM1 : 35|1@0+ (1,0) [0|0] "" Vector_XXX
 SG_ PNC36_PSCM1 : 36|1@0+ (1,0) [0|0] "" Vector_XXX
 SG_ PNC37_PSCM1 : 37|1@0+ (1,0) [0|0] "" Vector_XXX
 SG_ PNC38_PSCM1 : 38|1@0+ (1,0) [0|0] "" Vector_XXX
 SG_ PNC39_PSCM1 : 39|1@0+ (1,0) [0|0] "" Vector_XXX
 SG_ NM_PNI_PSCM1 : 14|1@0+ (1,0) [0|0] "" Vector_XXX
 SG_ NM_AW_PSCM1 : 12|1@0+ (1,0) [0|0] "" Vector_XXX
 SG_ NM_CS_PSCM1 : 11|1@0+ (1,0) [0|0] "" Vector_XXX
 SG_ NM_RMR_PSCM1 : 8|1@0+ (1,0) [0|0] "" Vector_XXX
 SG_ NM_NodeID_PSCM1 : 7|8@0+ (1,0) [0|0] "" Vector_XXX

BO_ 1430 PscmDevelpFr: 8 PSCM1
 SG_ PSCMdevelpsignalgroupresp1Functiondevpsignalgroup1 : 7|8@0+ (1.0,0.0) [0.0|255.0] "Unitless" ETC
 SG_ PSCMdevelpsignalgroupresp1Functiondevpsignalgroup2 : 15|8@0+ (1.0,0.0) [0.0|255.0] "Unitless" ETC
 SG_ PSCMdevelpsignalgroupresp1Functiondevpsignalgroup3 : 23|8@0+ (1.0,0.0) [0.0|255.0] "Unitless" ETC
 SG_ PSCMdevelpsignalgroupresp1Functiondevpsignalgroup4 : 31|8@0+ (1.0,0.0) [0.0|255.0] "Unitless" ETC
 SG_ PSCMdevelpsignalgroupresp1Functiondevpsignalgroup5 : 39|8@0+ (1.0,0.0) [0.0|255.0] "Unitless" ETC
 SG_ PSCMdevelpsignalgroupresp1Functiondevpsignalgroup6 : 47|8@0+ (1.0,0.0) [0.0|255.0] "Unitless" ETC
 SG_ PSCMdevelpsignalgroupresp1Functiondevpsignalgroup7 : 55|8@0+ (1.0,0.0) [0.0|255.0] "Unitless" ETC
 SG_ PSCMdevelpsignalgroupresp1Functiondevpsignalgroup8 : 63|8@0+ (1.0,0.0) [0.0|255.0] "Unitless" ETC

BO_ 1410 PscmToEtcChas1XcpFr01: 8 PSCM1

BO_ 1417 PscmToEtcChas1XcpFr02: 8 PSCM1

BO_ 1419 PscmToEtcChas1XcpFr03: 8 PSCM1

BO_ 1415 PscmToEtcChas1XcpFr04: 8 PSCM1

BO_ 1412 PscmToEtcChas1XcpFr05: 8 PSCM1

BO_ 1423 PscmToEtcChas1XcpFr06: 8 PSCM1

BO_ 1648 PscmToVddmChas1DiagResFrame: 8 PSCM1
 SG_ PscmToVddmChas1DiagResNpdu : 7|64@0+ (1,0) [0|0] "" VDDM

BO_ 64 SasChas1Fr01: 8 SAS
 SG_ SteerWhlSnsr_UB : 7|1@0+ (1,0) [0|1] "" ASDM,ECM,PSCM1,VDDM
 SG_ SteerWhlSnsrAg : 6|15@0- (0.0009765625,0.0) [-14.5|14.5] "rad" ASDM,ECM,PSCM1,VDDM
 SG_ SteerWhlSnsrAgSpd : 21|14@0- (0.0078125,0.0) [-50.0|50.0] "rad/s" ASDM,ECM,PSCM1,VDDM
 SG_ SteerWhlSnsrChks : 39|8@0+ (1.0,0.0) [0.0|255.0] "Unitless" ASDM,ECM,PSCM1,VDDM
 SG_ SteerWhlSnsrCntr : 47|4@0+ (1.0,0.0) [0.0|15.0] "Unitless" ASDM,ECM,PSCM1,VDDM
 SG_ SteerWhlSnsrQf : 23|2@0+ (1,0) [0|3] "" ASDM,ECM,PSCM1,VDDM

BO_ 1319 SasChas1NMFr: 8 SAS
 SG_ PNC16_SAS : 16|1@0+ (1,0) [0|0] "" Vector_XXX
 SG_ PNC17_SAS : 17|1@0+ (1,0) [0|0] "" Vector_XXX
 SG_ PNC18_SAS : 18|1@0+ (1,0) [0|0] "" Vector_XXX
 SG_ PNC19_SAS : 19|1@0+ (1,0) [0|0] "" Vector_XXX
 SG_ PNC20_SAS : 20|1@0+ (1,0) [0|0] "" Vector_XXX
 SG_ PNC21_SAS : 21|1@0+ (1,0) [0|0] "" Vector_XXX
 SG_ PNC22_SAS : 22|1@0+ (1,0) [0|0] "" Vector_XXX
 SG_ PNC23_SAS : 23|1@0+ (1,0) [0|0] "" Vector_XXX
 SG_ PNC24_SAS : 24|1@0+ (1,0) [0|0] "" Vector_XXX
 SG_ PNC25_SAS : 25|1@0+ (1,0) [0|0] "" Vector_XXX
 SG_ PNC26_SAS : 26|1@0+ (1,0) [0|0] "" Vector_XXX
 SG_ PNC27_SAS : 27|1@0+ (1,0) [0|0] "" Vector_XXX
 SG_ PNC28_SAS : 28|1@0+ (1,0) [0|0] "" Vector_XXX
 SG_ PNC29_SAS : 29|1@0+ (1,0) [0|0] "" Vector_XXX
 SG_ PNC30_SAS : 30|1@0+ (1,0) [0|0] "" Vector_XXX
 SG_ PNC31_SAS : 31|1@0+ (1,0) [0|0] "" Vector_XXX
 SG_ PNC32_SAS : 32|1@0+ (1,0) [0|0] "" Vector_XXX
 SG_ PNC33_SAS : 33|1@0+ (1,0) [0|0] "" Vector_XXX
 SG_ PNC34_SAS : 34|1@0+ (1,0) [0|0] "" Vector_XXX
 SG_ PNC35_SAS : 35|1@0+ (1,0) [0|0] "" Vector_XXX
 SG_ PNC36_SAS : 36|1@0+ (1,0) [0|0] "" Vector_XXX
 SG_ PNC37_SAS : 37|1@0+ (1,0) [0|0] "" Vector_XXX
 SG_ PNC38_SAS : 38|1@0+ (1,0) [0|0] "" Vector_XXX
 SG_ PNC39_SAS : 39|1@0+ (1,0) [0|0] "" Vector_XXX
 SG_ NM_PNI_SAS : 14|1@0+ (1,0) [0|0] "" Vector_XXX
 SG_ NM_AW_SAS : 12|1@0+ (1,0) [0|0] "" Vector_XXX
 SG_ NM_CS_SAS : 11|1@0+ (1,0) [0|0] "" Vector_XXX
 SG_ NM_RMR_SAS : 8|1@0+ (1,0) [0|0] "" Vector_XXX
 SG_ NM_NodeID_SAS : 7|8@0+ (1,0) [0|0] "" Vector_XXX

BO_ 1650 SasToVddmChas1DiagResFrame: 8 SAS
 SG_ SasToVddmChas1DiagResNpdu : 7|64@0+ (1,0) [0|0] "" VDDM

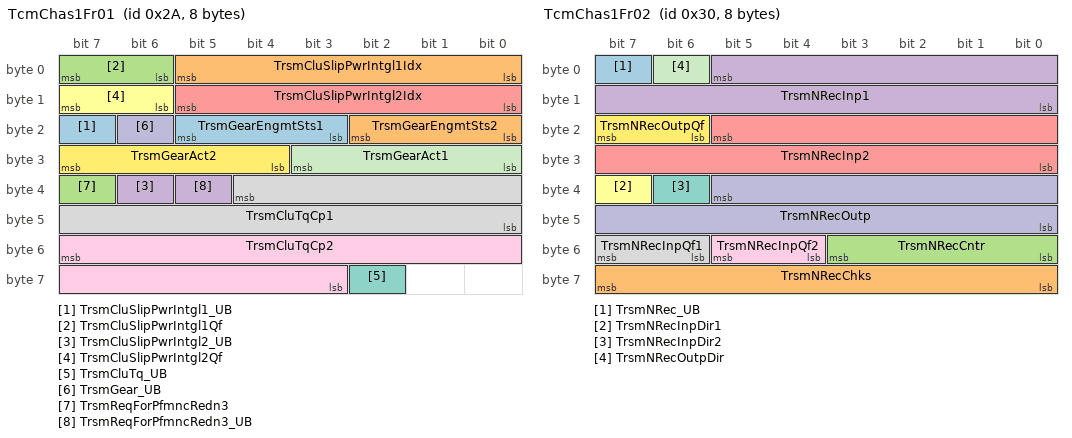
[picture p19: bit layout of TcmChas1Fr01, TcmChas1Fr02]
BO_ 42 TcmChas1Fr01: 8 TCM
 SG_ TrsmCluSlipPwrIntgl1_UB : 23|1@0+ (1,0) [0|1] "" ECM
 SG_ TrsmCluSlipPwrIntgl1Idx : 5|6@0+ (1.6,0.0) [0.0|100.80000000000001] "%" ECM
 SG_ TrsmCluSlipPwrIntgl1Qf : 7|2@0+ (1,0) [0|3] "" ECM
 SG_ TrsmCluSlipPwrIntgl2_UB : 38|1@0+ (1,0) [0|1] "" ECM
 SG_ TrsmCluSlipPwrIntgl2Idx : 13|6@0+ (1.6,0.0) [0.0|100.80000000000001] "%" ECM
 SG_ TrsmCluSlipPwrIntgl2Qf : 15|2@0+ (1,0) [0|3] "" ECM
 SG_ TrsmCluTq_UB : 58|1@0+ (1,0) [0|1] "" ECM
 SG_ TrsmCluTqCp1 : 36|13@0+ (0.1,-5.0) [-5.0|814.1] "NewtonMeter" ECM
 SG_ TrsmCluTqCp2 : 55|13@0+ (0.1,-5.0) [-5.0|814.1] "NewtonMeter" ECM
 SG_ TrsmGear_UB : 22|1@0+ (1,0) [0|1] "" ECM
 SG_ TrsmGearAct1 : 27|4@0+ (1,0) [0|15] "" ECM
 SG_ TrsmGearAct2 : 31|4@0+ (1,0) [0|15] "" ECM
 SG_ TrsmGearEngmtSts1 : 21|3@0+ (1,0) [0|7] "" ECM
 SG_ TrsmGearEngmtSts2 : 18|3@0+ (1,0) [0|7] "" ECM
 SG_ TrsmReqForPfmncRedn3 : 39|1@0+ (1,0) [0|1] "" ECM
 SG_ TrsmReqForPfmncRedn3_UB : 37|1@0+ (1,0) [0|1] "" ECM

BO_ 48 TcmChas1Fr02: 8 TCM
 SG_ TrsmNRec_UB : 7|1@0+ (1,0) [0|1] "" ECM,VDDM
 SG_ TrsmNRecChks : 63|8@0+ (1.0,0.0) [0.0|255.0] "Unitless" ECM,VDDM
 SG_ TrsmNRecCntr : 51|4@0+ (1.0,0.0) [0.0|15.0] "Unitless" ECM,VDDM
 SG_ TrsmNRecInp1 : 5|14@0+ (1.0,0.0) [0.0|16383.0] "rpm" ECM,VDDM
 SG_ TrsmNRecInp2 : 21|14@0+ (1.0,0.0) [0.0|16383.0] "rpm" ECM,VDDM
 SG_ TrsmNRecInpDir1 : 39|1@0+ (1,0) [0|1] "" ECM,VDDM
 SG_ TrsmNRecInpDir2 : 38|1@0+ (1,0) [0|1] "" ECM,VDDM
 SG_ TrsmNRecInpQf1 : 55|2@0+ (1,0) [0|3] "" ECM,VDDM
 SG_ TrsmNRecInpQf2 : 53|2@0+ (1,0) [0|3] "" ECM,VDDM
 SG_ TrsmNRecOutp : 37|14@0+ (1.0,0.0) [0.0|16383.0] "rpm" ECM,VDDM
 SG_ TrsmNRecOutpDir : 6|1@0+ (1,0) [0|1] "" ECM,VDDM
 SG_ TrsmNRecOutpQf : 23|2@0+ (1,0) [0|3] "" ECM,VDDM

BO_ 53 TcmChas1Fr03: 8 TCM
 SG_ TrsmCluSlipCtrlModSts : 5|2@0+ (1,0) [0|3] "" ECM
 SG_ TrsmCluSlipCtrlModSts_UB : 6|1@0+ (1,0) [0|1] "" ECM
 SG_ TrsmCluT1_UB : 3|1@0+ (1,0) [0|1] "" ECM
 SG_ TrsmCluT1Qf : 2|2@0+ (1,0) [0|3] "" ECM
 SG_ TrsmCluT1Val : 0|9@0+ (1.25,-40.0) [-40.0|598.75] "degC" ECM
 SG_ TrsmCluT2_UB : 56|1@0+ (1,0) [0|1] "" ECM
 SG_ TrsmCluT2Qf : 18|2@0+ (1,0) [0|3] "" ECM
 SG_ TrsmCluT2Val : 16|9@0+ (1.25,-40.0) [-40.0|598.75] "degC" ECM
 SG_ TrsmCluTqCpMaxInProgs1 : 44|1@0+ (1,0) [0|1] "" ECM
 SG_ TrsmCluTqCpMaxInProgs1_UB : 63|1@0+ (1,0) [0|1] "" ECM
 SG_ TrsmCluTqCpMaxInProgs2 : 43|1@0+ (1,0) [0|1] "" ECM
 SG_ TrsmCluTqCpMaxInProgs2_UB : 62|1@0+ (1,0) [0|1] "" ECM
 SG_ TrsmCluTqCpMaxPrio1 : 42|2@0+ (1,0) [0|3] "" ECM
 SG_ TrsmCluTqCpMaxPrio1_UB : 61|1@0+ (1,0) [0|1] "" ECM
 SG_ TrsmCluTqCpMaxPrio2 : 55|2@0+ (1,0) [0|3] "" ECM
 SG_ TrsmCluTqCpMaxPrio2_UB : 60|1@0+ (1,0) [0|1] "" ECM
 SG_ TrsmCluTqCpMinInProgs1 : 53|1@0+ (1,0) [0|1] "" ECM
 SG_ TrsmCluTqCpMinInProgs1_UB : 50|1@0+ (1,0) [0|1] "" ECM
 SG_ TrsmCluTqCpMinInProgs2 : 52|1@0+ (1,0) [0|1] "" ECM
 SG_ TrsmCluTqCpMinInProgs2_UB : 49|1@0+ (1,0) [0|1] "" ECM
 SG_ TrsmGearActrScanForRefActv : 39|1@0+ (1,0) [0|1] "" ECM
 SG_ TrsmGearActrScanForRefActv_UB : 48|1@0+ (1,0) [0|1] "" ECM
 SG_ TrsmGearActrScanForRefReq : 47|1@0+ (1,0) [0|1] "" ECM
 SG_ TrsmGearActrScanForRefReq_UB : 59|1@0+ (1,0) [0|1] "" ECM
 SG_ TrsmOilFlow : 23|5@0+ (1,0) [0|31] "" ECM,VDDM
 SG_ TrsmOilFlow_UB : 7|1@0+ (1,0) [0|1] "" ECM,VDDM
 SG_ TrsmOperSts : 37|6@0+ (1.0,0.0) [0.0|63.0] "Unitless" ECM
 SG_ TrsmOperSts_UB : 38|1@0+ (1,0) [0|1] "" ECM
 SG_ TrsmSlipCtrlReq : 51|1@0+ (1,0) [0|1] "" ECM
 SG_ TrsmSlipCtrlReq_UB : 57|1@0+ (1,0) [0|1] "" ECM
 SG_ TrsmSoftRotReq1 : 46|1@0+ (1,0) [0|1] "" ECM
 SG_ TrsmSoftRotReq1_UB : 40|1@0+ (1,0) [0|1] "" ECM
 SG_ TrsmSoftRotReq2 : 45|1@0+ (1,0) [0|1] "" ECM
 SG_ TrsmSoftRotReq2_UB : 58|1@0+ (1,0) [0|1] "" ECM

BO_ 117 TcmChas1Fr04: 8 TCM
 SG_ TrsmCluActrLimd1 : 7|1@0+ (1,0) [0|1] "" ECM
 SG_ TrsmCluActrLimd1_UB : 6|1@0+ (1,0) [0|1] "" ECM
 SG_ TrsmCluActrLimd2 : 5|1@0+ (1,0) [0|1] "" ECM
 SG_ TrsmCluActrLimd2_UB : 4|1@0+ (1,0) [0|1] "" ECM
 SG_ TrsmCluActrOff1 : 3|1@0+ (1,0) [0|1] "" ECM
 SG_ TrsmCluActrOff1_UB : 2|1@0+ (1,0) [0|1] "" ECM
 SG_ TrsmCluActrOff2 : 1|1@0+ (1,0) [0|1] "" ECM
 SG_ TrsmCluActrOff2_UB : 0|1@0+ (1,0) [0|1] "" ECM
 SG_ TrsmCluActrTLvl1 : 9|2@0+ (1,0) [0|3] "" ECM
 SG_ TrsmCluActrTLvl1_UB : 25|1@0+ (1,0) [0|1] "" ECM
 SG_ TrsmCluActrTLvl2 : 23|2@0+ (1,0) [0|3] "" ECM
 SG_ TrsmCluActrTLvl2_UB : 24|1@0+ (1,0) [0|1] "" ECM
 SG_ TrsmCluTqCpCorrln1 : 21|2@0+ (1,0) [0|3] "" ECM
 SG_ TrsmCluTqCpCorrln1_UB : 35|1@0+ (1,0) [0|1] "" ECM
 SG_ TrsmCluTqCpCorrln2 : 19|2@0+ (1,0) [0|3] "" ECM
 SG_ TrsmCluTqCpCorrln2_UB : 51|1@0+ (1,0) [0|1] "" ECM
 SG_ TrsmCluTqCpMax1 : 33|10@0+ (1.0,0.0) [0.0|1023.0] "NewtonMeter" ECM
 SG_ TrsmCluTqCpMax1_UB : 34|1@0+ (1,0) [0|1] "" ECM
 SG_ TrsmCluTqCpMax2 : 49|10@0+ (1.0,0.0) [0.0|1023.0] "NewtonMeter" ECM
 SG_ TrsmCluTqCpMax2_UB : 50|1@0+ (1,0) [0|1] "" ECM
 SG_ TrsmCluTqCpMinPrio1 : 17|2@0+ (1,0) [0|3] "" ECM
 SG_ TrsmCluTqCpMinPrio1_UB : 52|1@0+ (1,0) [0|1] "" ECM
 SG_ TrsmCluTqCpMinPrio2 : 31|2@0+ (1,0) [0|3] "" ECM
 SG_ TrsmCluTqCpMinPrio2_UB : 53|1@0+ (1,0) [0|1] "" ECM
 SG_ TrsmEndOfLineModActv : 15|1@0+ (1,0) [0|1] "" ECM
 SG_ TrsmEndOfLineModActv_UB : 14|1@0+ (1,0) [0|1] "" ECM
 SG_ TrsmGbxActrOff : 13|1@0+ (1,0) [0|1] "" ECM
 SG_ TrsmGbxActrOff_UB : 12|1@0+ (1,0) [0|1] "" ECM
 SG_ TrsmGearActrSts : 11|1@0+ (1,0) [0|1] "" ECM
 SG_ TrsmGearActrSts_UB : 10|1@0+ (1,0) [0|1] "" ECM
 SG_ TrsmGearActrTLvl : 29|2@0+ (1,0) [0|3] "" ECM
 SG_ TrsmGearActrTLvl_UB : 54|1@0+ (1,0) [0|1] "" ECM
 SG_ TrsmHardRotReq1 : 39|1@0+ (1,0) [0|1] "" ECM
 SG_ TrsmHardRotReq1_UB : 38|1@0+ (1,0) [0|1] "" ECM
 SG_ TrsmHardRotReq2 : 37|1@0+ (1,0) [0|1] "" ECM
 SG_ TrsmHardRotReq2_UB : 36|1@0+ (1,0) [0|1] "" ECM
 SG_ TrsmOilPmpTLvl : 27|2@0+ (1,0) [0|3] "" ECM
 SG_ TrsmOilPmpTLvl_UB : 55|1@0+ (1,0) [0|1] "" ECM

// Node Comments
CM_ BU_ ECM "Engine Control Module";
CM_ BU_ ETC "External Tester Connector";
CM_ BU_ PSCM1 "Power Steering Control Module";
CM_ BU_ SAS "Steering Angle Sensor";
CM_ BU_ VDDM "Vehicle Dynamics Domain Master
";

// Signal Comments
CM_ SG_ 147 AsyADL3FuncCtrlStsADMod "ADMod";
CM_ SG_ 147 AsyADL3FuncCtrlStsChks "Checksum";
CM_ SG_ 147 AsyADL3FuncCtrlStsCntr "Counter";
CM_ SG_ 147 AsyADL3FuncCtrlStsCtrlSts "CtrlSts";
CM_ SG_ 147 AsyADL3FuncCtrlStsDegraded "Degraded";
CM_ SG_ 147 AsyADL3FuncCtrlStsQf "Qf";
CM_ SG_ 147 AsyADL3FuncCtrlStsSts "Status";
CM_ SG_ 147 AsyADModeReqADActiveReq "ADActiveRequest";
CM_ SG_ 147 AsyADModeReqADDeactiveReq "AD Deactive Request";
CM_ SG_ 147 AsyADModeReqChks "Checksum";
CM_ SG_ 147 AsyADModeReqCntr "Counter";
CM_ SG_ 147 PASFuncActive "Parking function.";
CM_ SG_ 147 RctaBrkReqQM "Indicating RCTA braking is committed.
This signal complies with QM.";
CM_ SG_ 147 RcwmBrkReqQM "Indicating RCW braking request is committed. This signal complies with QM.";
CM_ SG_ 51 AgCtrlTqLowrLim "Lower limit for angle controller torque request.";
CM_ SG_ 51 AgCtrlTqUpprLim "Upper limit for angle controller torque request.";
CM_ SG_ 51 AsyPinionAgReqSafeAsyPinionAgReq "Steering request signal from Active Safety with end-to-end protection ";
CM_ SG_ 51 AsyPinionAgReqSafeAsyPinionAgReqChks "CRC";
CM_ SG_ 51 AsyPinionAgReqSafeAsyPinionAgReqCntr "Counter";
CM_ SG_ 51 PinionAgRateLim "Upper limit for angle controller torque request.";
CM_ SG_ 565 MvEMIDCMin "Minimum DC current limit";
CM_ SG_ 565 MvEMUDCMaxFullLim "Maximum DC voltage limit. Higth voltage derating upper limit (0Nm allowed)";
CM_ SG_ 565 MvEMUDCMaxUnLim "Begin of maximum DC voltage limit. High voltage derating lower limit (full torque allowed)";
CM_ SG_ 565 MvEMUDCMinFullLim "Minimum DC voltage limit. Low voltage derating lower limit (0Nm allowed)";
CM_ SG_ 565 MvEMUDCMinUnLim "Begin of minimum DC voltage limit. Low voltage derating upper limit (full torque allowed)";
CM_ SG_ 631 MvEMCooltFlowForDtElec "MV emotor estimated coolant flow.";
CM_ SG_ 631 MvEMCooltT "MV emotor inlet coolant temperature.";
CM_ SG_ 564 MonrCycCmpl "OBD Warm Up Cycle Complete. 0= Not Complete; 1= Complete.";
CM_ SG_ 564 MvEMIDCMax "Maximum DC current limit";
CM_ SG_ 564 MvEMTqMax "Maximum positive torque(Speed Control, Torque Control)";
CM_ SG_ 564 MvEMTqMin "Minimum negative torque(Speed Control, Torque Control)";
CM_ SG_ 564 MvEMUReq "Mv EM voltage request";
CM_ SG_ 564 PrpsnSysActv "Indicate whether propulsion system activation has complete or not.";
CM_ SG_ 226 MvEMModReqChks "Checksum for MvEMModReq";
CM_ SG_ 226 MvEMModReqCntr "Counter for MvEMModReq";
CM_ SG_ 226 MvEMModReqMvEMModReq "Functional mode status  0x0: Reserved   0x1: StdBy   0x2: TqCtl   0x3: SpdCtl   0x4: UDcCtl   0x5: GenNoBatCtl  0x6-0x0F:Reserved";
CM_ SG_ 226 MvEMSpdGrdtLim "Positive or negative (symetric) Speed Request Gradient applicable on both sign only for Speed Control Mode";
CM_ SG_ 226 MvEMTqGrdtLim "Positive or Negative Torque Gradient applied for Torque Control Mode";
CM_ SG_ 134 AntiJerkSelect "Anti - jerk filtering level";
CM_ SG_ 134 DrvgCyc " Transition from 0 to 1 indicates a start of a new Driving Cycle.";
CM_ SG_ 134 JOACEnbReq "JOAC enable request";
CM_ SG_ 134 JOACFreqIndex "Frequency JOAC parameters : 
[0x01= 5,0Hz], [0x02= 6,34Hz],[0x03=7,20Hz], [0x04= 8,30Hz], [0x05= 9,73Hz], [0x06= 10,5Hz], [0x07=11,8Hz], [0x8= 13,0Hz].
0x00,0x09-0xF: reserved";
CM_ SG_ 134 JOACModulation "Gain on the torque requested by JOAC";
CM_ SG_ 134 JOACTrqMax "JOAC maximum torque oscillation";
CM_ SG_ 544 AccrPedlRatAccrPedlRat "Accelerator Pedal Position with adapted 0 point. Value as percentage of fully pressed pedal";
CM_ SG_ 544 AccrPedlRatChks "Accelerator Pedal Position with adapted 0 point. Value as percentage of fully pressed pedal. Checksum";
CM_ SG_ 544 AccrPedlRatCntr "Accelerator Pedal Position with adapted 0 point. Value as percentage of fully pressed pedal. Counter";
CM_ SG_ 544 DenoOfDiagcRateGen "To indicate the whether the driving cycle meets the condition as a diagnostics denominator cycle defined in China Six J3.4.3.2";
CM_ SG_ 544 DrvgCycToClrPrmntDtc "China Sixth defines the cycle of clearing permanent fault codes. (J3.2.5.2 (B))";
CM_ SG_ 544 EngTEngT "Engine coolant temperature. Resolution 1 degC
";
CM_ SG_ 544 EngTQf "Engine coolant temperature quality factor.Engine coolant temperature";
CM_ SG_ 544 IuprDenominatorInhb "Inhibition flag of IUPR denominator from China Six.";
CM_ SG_ 544 MvEMVoltGrdtLim "MvEM voltage gradient limit in generator mode";
CM_ SG_ 530 EngTiOn "Time since engine starts or propulsion on with movement for league requirement";
CM_ SG_ 530 LoadValCalcd "The ECU shall make the signal Calculated Load Value according to SAE J1979 available on CAN.";
CM_ SG_ 530 ThrPos " ECM  throttle position (AbsThrottlePosition) on CAN";
CM_ SG_ 32 PtCluSlipCtrlModReq "Slip control mode request";
CM_ SG_ 32 PtCluSlipCtrlReq "Slip shaft request";
CM_ SG_ 32 PtCluSlipCtrlSpdReq "Slip speed request";
CM_ SG_ 32 PtCluTqCpReq1 "Torque capacity request 1";
CM_ SG_ 32 PtCluTqCpReq2 "Torque capacity request 2";
CM_ SG_ 32 PtEngTqDstbcActv "Crankshaft torque currently disturbed.";
CM_ SG_ 32 PtEngTqModlnSts "Crankshaft torque currently modulated.";
CM_ SG_ 32 PtGearActtnReq3 "Gear request 3.";
CM_ SG_ 32 PtRotReqAckd1 "Antibalking rotation performed 1";
CM_ SG_ 32 PtRotReqAckd2 "Antibalking rotation performed 2";
CM_ SG_ 37 PtCluTqCpMaxCmd1 "Maximum torque capacity command 1.";
CM_ SG_ 37 PtCluTqCpMaxCmd2 "Maximum torque capacity command 2.";
CM_ SG_ 37 PtCluTqCpMinCmd1 "Minimum torque capacity command 1.";
CM_ SG_ 37 PtCluTqCpMinCmd2 "Minimum torque capacity command 2.";
CM_ SG_ 37 PtDirAllwdToTrsmActrChks "Checksum for PtDirAllwdToTrsmActr";
CM_ SG_ 37 PtDirAllwdToTrsmActrCntr "Counter for PtDirAllwdToTrsmActr";
CM_ SG_ 37 PtDirAllwdToTrsmActrFwd "Powertrain direction allowance to transmission actuator Forward";
CM_ SG_ 37 PtDirAllwdToTrsmActrNeut "Powertrain direction allowance to transmission actuator Neutral";
CM_ SG_ 37 PtDirAllwdToTrsmActrParkRls "Powertrain direction allowance to transmission actuator Park Release";
CM_ SG_ 37 PtDirAllwdToTrsmActrRvs "Powertrain direction allowance to transmission actuator Reverse";
CM_ SG_ 37 PtGearActrAdpnCmd "Gear actuator adaptation allowed.";
CM_ SG_ 37 PtGearActtnAllwdSts1 " Drivetrain status 1";
CM_ SG_ 37 PtGearActtnAllwdSts2 " Drivetrain status 2";
CM_ SG_ 37 PtGearActtnModReq "Mode request";
CM_ SG_ 37 PtGearActtnPfmncReq "Performance request";
CM_ SG_ 37 PtGearActtnPrio "Gear engagement prioritization";
CM_ SG_ 37 PtGearActtnReq1 "Gear request 1";
CM_ SG_ 37 PtGearActtnReq2 "Gear request 2";
CM_ SG_ 697 EngPmpStatCooltPmpDryErr "water pump MT Dryrun error";
CM_ SG_ 697 EngPmpStatCooltPmpEmgyModSts "water pump MT, Status Emergency mode";
CM_ SG_ 697 EngPmpStatCooltPmpErrSts "water pump error status";
CM_ SG_ 697 EngPmpStatCooltPmpI "Actual current consumption";
CM_ SG_ 697 EngPmpStatCooltPmpIErr "water pump MT current error";
CM_ SG_ 697 EngPmpStatCooltPmpMonrSpd "water pump MT, RPM Monitoring";
CM_ SG_ 697 EngPmpStatCooltPmpPostRunSts "water pump post run status";
CM_ SG_ 697 EngPmpStatCooltPmpSetPostRunReq "water pump set post run speed request";
CM_ SG_ 697 EngPmpStatCooltPmpSetSpdReq "water pump MT Set speed";
CM_ SG_ 697 EngPmpStatCooltPmpSpd "Actual speed from coolant pump";
CM_ SG_ 697 EngPmpStatCooltPmpT "water pump MT Temperature";
CM_ SG_ 697 EngPmpStatCooltPmpTErr "water pump MT temperature error";
CM_ SG_ 697 EngPmpStatCooltPmpU "water pump MT Voltage";
CM_ SG_ 697 EngPmpStatCooltPmpUErr "water pump MT voltage error";
CM_ SG_ 697 EngPmpStatCooltPmpUnstallSts "water pump MT, Deblocking";
CM_ SG_ 80 EngN2 "Engine Speed [rpm]";
CM_ SG_ 80 PtCluTq2PtCluTq "Crankshaft torque";
CM_ SG_ 80 PtCluTq2PtCluTqQly "Crankshaft torque quality factor";
CM_ SG_ 80 PtCluTq2Req "Requset crank shaft torque";
CM_ SG_ 80 PtCluTq2ReqWoTrsmIntv "Arbitrated crankshaft torque to TCM";
CM_ SG_ 554 CmprFbCmprI "Compressor current";
CM_ SG_ 554 CmprFbCmprIPha "Compressor phase current";
CM_ SG_ 554 CmprFbCmprSpd "Compressor rotational speed";
CM_ SG_ 554 CmprFbCmprSts1 "Compressor status";
CM_ SG_ 554 CmprFbCmprSts2 "Compressor status";
CM_ SG_ 554 CmprFbCmprT1 "Compressor IGBT temperature";
CM_ SG_ 554 CmprFbCmprT2 "Compressor capacitor/IGBT temperature";
CM_ SG_ 554 CmprFbCmprU "Compressor high voltage";
CM_ SG_ 1111 PtTqAtWhlFrntActChks "checksum";
CM_ SG_ 1111 PtTqAtWhlFrntActCntr "counter";
CM_ SG_ 1111 PtTqAtWhlFrntActPtTqAtAxleFrntAct "Actual torque delivered by the powertrain to the front axle";
CM_ SG_ 1111 PtTqAtWhlFrntActPtTqAtWhlFrntLeAct "Actual torque delivered by the powertrain to the front left wheel.";
CM_ SG_ 1111 PtTqAtWhlFrntActPtTqAtWhlFrntRiAct "Actual torque delivered by the powertrain to the front right wheel.";
CM_ SG_ 1111 PtTqAtWhlFrntActPtTqAtWhlsFrntQly "quality factor";
CM_ SG_ 708 FanPwmReq "Fan Pwm Request.";
CM_ SG_ 708 PtVehSpdMaxChks "Checksum of PtVehSpdMax";
CM_ SG_ 708 PtVehSpdMaxCntr "Counter of PtVehSpdMax";
CM_ SG_ 708 PtVehSpdMaxReq " The signal shall limit the vehicle speed for e.g. reverse with electric engine and manipulation of the speed signal.";
CM_ SG_ 708 WtrPmpAuxReq "Auxoliary water pump request.";
CM_ SG_ 730 HvBattPmpStatCooltPmpDryErr "water pump MT Dryrun error";
CM_ SG_ 730 HvBattPmpStatCooltPmpEmgyModSts "water pump MT, Status Emergency mode";
CM_ SG_ 730 HvBattPmpStatCooltPmpErrSts "water pump error status";
CM_ SG_ 730 HvBattPmpStatCooltPmpI "Actual current consumption from battery coolant pump.";
CM_ SG_ 730 HvBattPmpStatCooltPmpIErr "water pump MT current error";
CM_ SG_ 730 HvBattPmpStatCooltPmpMonrSpd "water pump MT, RPM Monitoring";
CM_ SG_ 730 HvBattPmpStatCooltPmpPostRunSts "water pump post run status";
CM_ SG_ 730 HvBattPmpStatCooltPmpSetPostRunReq "water pump set post run speed request";
CM_ SG_ 730 HvBattPmpStatCooltPmpSetSpdReq "Coolant pump set speed request";
CM_ SG_ 730 HvBattPmpStatCooltPmpSpd "Coolant pump actual speed";
CM_ SG_ 730 HvBattPmpStatCooltPmpT "water pump MT Temperature ";
CM_ SG_ 730 HvBattPmpStatCooltPmpTErr "water pump MT temperature error";
CM_ SG_ 730 HvBattPmpStatCooltPmpU "Coolant pump voltage";
CM_ SG_ 730 HvBattPmpStatCooltPmpUErr "water pump MT voltage error";
CM_ SG_ 730 HvBattPmpStatCooltPmpUnstallSts "water pump MT, Deblocking";
CM_ SG_ 859 ResrvdSigForCCM1 "Reserved signal 1 for CCM.";
CM_ SG_ 859 ResrvdSigForCCM2 "Reserved signal 2 for CCM.";
CM_ SG_ 859 ResrvdSigForCCM3 "Reserved signal 3 for CCM.";
CM_ SG_ 859 ResrvdSigForCCM4 "Reserved signal 4 for CCM.";
CM_ SG_ 871 BookChrgnTarValFb "Feedback the corresponding signal when receives BookChrgnTarVal from TCAM";
CM_ SG_ 871 DchaChrgnTarValFb "Feedback the corresponding signal when receivesDchaChrgnTarVal from TCAM";
CM_ SG_ 871 HvBattPmpCmdCooltPmpPostRunReq "Coolant pump post run request";
CM_ SG_ 871 HvBattPmpCmdCooltPmpSpdReq "Coolant pump speed request";
CM_ SG_ 871 ReEvapVlvReq "Request to open shut off valve of rear evaporator.";
CM_ SG_ 979 CmprReqCmprSpdReq "AC compressor rotational speed request.";
CM_ SG_ 979 GrlShttrDmdShttrCalEna "AGM shutter calculation enable";
CM_ SG_ 979 GrlShttrDmdShttrPosnReq "AGM shutter position request";
CM_ SG_ 979 SplrShttrDmdShttrCalEna "Spoiler shutter calculation enable";
CM_ SG_ 979 SplrShttrDmdShttrPosnReq "Spoiler shutter position request.";
CM_ SG_ 1039 CmprReqAcCapReqOvr "request aircond compressor displacement duty override.";
CM_ SG_ 1039 CmprReqCluReqOvr "AC compressor run request override.";
CM_ SG_ 1039 EldtPmpCmdCooltPmpPostRunReq "Coolant pump post run request.";
CM_ SG_ 1039 EldtPmpCmdCooltPmpSpdReq "Coolant pump speed request.";
CM_ SG_ 1039 EngCooltPmpSpdReqCooltPmpPostRunReq "Coolant pump post run request";
CM_ SG_ 1039 EngCooltPmpSpdReqCooltPmpSpdReq "Coolant pump speed request.";
CM_ SG_ 1039 TocCooltPmpReq "TOC coolant pump request.";
CM_ SG_ 563 CmprRunTime "Compressor run time.";
CM_ SG_ 563 HeatrPmpIAct "Heater pump actual current.";
CM_ SG_ 563 HeatrPmpPwrCns "Heater pump actual power consumption.";
CM_ SG_ 563 TrsmSailModReq "Request Transmission Sailing mode";
CM_ SG_ 991 AcTqOvr "Final Ac torque after override function.";
CM_ SG_ 991 FanPwmReqForEldt "Fan pwm request for electric drivetrain.";
CM_ SG_ 991 FanPwrCns "Actual electrical power consumed by the engine cooling fan.";
CM_ SG_ 991 HvCooltHeatrICnsSig "contains information of how much current that is consumed  from the high voltage supply.";
CM_ SG_ 304 AccrpedlSts " It should provide acceleration pedal Status signal ( AccrpedlSts ) to predict whether the accelerator pedal  has fault or not.1-Fault; 0-NoFault";
CM_ SG_ 304 BsgDcDcPmpCmdCooltPmpPostRunReq "Coolant pump post run request.";
CM_ SG_ 304 BsgDcDcPmpCmdCooltPmpSpdReq "Coolant pump speed request.";
CM_ SG_ 304 CnvnAllwd "Intelligent charging allow status. 0 = NOK Or 1 = OK";
CM_ SG_ 304 EngNSafeEngN "Engine Speed [rpm] and Engine Speed derivative [rpm/s]";
CM_ SG_ 304 EngNSafeEngNChks "Engine Speed [rpm] and Engine Speed derivative [rpm/s]";
CM_ SG_ 304 EngNSafeEngNCntr "Engine Speed [rpm] and Engine Speed derivative [rpm/s]";
CM_ SG_ 304 EngNSafeEngNGrdt "Engine Speed [rpm] and Engine Speed derivative [rpm/s]";
CM_ SG_ 1135 BattCooltIndcnReq "Battery coolant level indication request";
CM_ SG_ 1135 CooltFlowInCmptmtCirc "Informs of coolant flow in the heat exchange. Created for the short coolant circuit in hybrid cars.";
CM_ SG_ 1135 EngTRefSts "Status bit array to indicate which sensors are used for the calculation of EngTRefT1 and EngTRefT2.";
CM_ SG_ 1135 EngTRefT1 "The lowest of the two reference temperatures that may be used for offset low diagnostics of temperatures in the TCM.";
CM_ SG_ 1135 EngTRefT2 "The highest of the two reference temperatures that may be used for offset low diagnostics of temperatures in the TCM.";
CM_ SG_ 1135 MvIsgDcDcBattFlt "Error indication DCDC, 48vBSG and 48vBattery";
CM_ SG_ 1135 MvIsgRBSModDisp "RBS mode for MMI display";
CM_ SG_ 1135 TelltlPwrLoss "Power loss dection ,which is used to indicate the DIM(turtle indicator)";
CM_ SG_ 576 HeatrPmpSpdAct "Heater pump actual speed.";
CM_ SG_ 576 HeatrPmpSpdReq "Heater pump speed request.";
CM_ SG_ 576 HeatrPmpUAct "Heater pump actual voltage.";
CM_ SG_ 576 HvBattPmpPwrCns "Coolant pump power consumption in battery cooling circuit.";
CM_ SG_ 576 PostHeatgRunTiEstimd "Estimated heating afterrun time.";
CM_ SG_ 455 HvActvSts "Indicate HV avtivation status.";
CM_ SG_ 455 MvBattRgnPerc "Percent of regen drive";
CM_ SG_ 455 PtTrsmOilFlowReq "Transmission oil flow level request";
CM_ SG_ 587 AirTFromHeatgEstimd "Estimated air temperature from heater.";
CM_ SG_ 587 BsgDcDcPmpPwmReq "Bsg DCDC coolant pump pwm request.";
CM_ SG_ 587 BsgDcDcPmpPwrCns "Bsg DCDC coolant pump power consumption.";
CM_ SG_ 543 AcCmprVlvICns "Ac variable displacement valve current consumption.";
CM_ SG_ 543 GearMov "To indicate the case that if any one of gear lever, shifting fork, gear lock button, P-button is intervened when vehicle enter APA/RPA mode";
CM_ SG_ 543 TocCooltPmpPwrCns "Toc coolant pump power consumption.";
CM_ SG_ 609 EldtFanPwrCns "ELDT cooling fan power consumption.";
CM_ SG_ 609 EldtPmpPwrCns "Coolant pump power consumption in ELDT cooling circuit.";
CM_ SG_ 609 EngCooltFlwAct "Engine actual coolant flow.";
CM_ SG_ 609 EngCooltPmpPwrCns "Actual electrical power consumed by engine water pump.";
CM_ SG_ 620 EldtPmpStatCooltPmpDryErr "water pump MT Dryrun error";
CM_ SG_ 620 EldtPmpStatCooltPmpEmgyModSts "water pump MT, Status Emergency mode";
CM_ SG_ 620 EldtPmpStatCooltPmpErrSts "water pump error status";
CM_ SG_ 620 EldtPmpStatCooltPmpI "Actual current consumption";
CM_ SG_ 620 EldtPmpStatCooltPmpIErr "water pump MT current error";
CM_ SG_ 620 EldtPmpStatCooltPmpMonrSpd "water pump MT, RPM Monitoring";
CM_ SG_ 620 EldtPmpStatCooltPmpPostRunSts "water pump post run status";
CM_ SG_ 620 EldtPmpStatCooltPmpSetPostRunReq "water pump set post run speed request";
CM_ SG_ 620 EldtPmpStatCooltPmpSetSpdReq "water pump MT Set speed";
CM_ SG_ 620 EldtPmpStatCooltPmpSpd "Actual speed from coolant pump";
CM_ SG_ 620 EldtPmpStatCooltPmpT "water pump MT Temperature";
CM_ SG_ 620 EldtPmpStatCooltPmpTErr "water pump MT temperature error";
CM_ SG_ 620 EldtPmpStatCooltPmpU "water pump MT Voltage";
CM_ SG_ 620 EldtPmpStatCooltPmpUErr "water pump MT voltage error";
CM_ SG_ 620 EldtPmpStatCooltPmpUnstallSts "water pump MT, Deblocking";
CM_ SG_ 632 GrlShttrStsShttrActrFlt "Indicate malfunctioning mechanical coupling between actuator and grill shutter vanes";
CM_ SG_ 632 GrlShttrStsShttrBlkd "Grill shutter actuator stuck";
CM_ SG_ 632 GrlShttrStsShttrCalActv "Grill shutter actuator end stop adaptation is ongoing";
CM_ SG_ 632 GrlShttrStsShttrCalIndcd "Indicate grill shutter actuator end stop adaptation necessary";
CM_ SG_ 632 GrlShttrStsShttrElecErr "Grill shutter actuator internal electrical fault";
CM_ SG_ 632 GrlShttrStsShttrPosnRaw "Current position of grill shutter actuator. ";
CM_ SG_ 632 GrlShttrStsShttrSnsrFlt "Grill shutter position sensor fault";
CM_ SG_ 632 GrlShttrStsShttrTErr "Grill shutter actuator over temperature";
CM_ SG_ 632 GrlShttrStsShttrULoErr "Grill shutter actuator supply voltage too low/high for movement";
CM_ SG_ 642 SplrShttrStsShttrActrFlt "Spoiler Shutter Lost Mechanical Coupling Monitoring";
CM_ SG_ 642 SplrShttrStsShttrBlkd "Spoiler Shutter Actuator Stuck Monitoring";
CM_ SG_ 642 SplrShttrStsShttrCalActv "Spoiler shutter actuator end stop adaptation is ongoing";
CM_ SG_ 642 SplrShttrStsShttrCalIndcd "Indicate spoiler shutter actuator end stop adaptation necessary";
CM_ SG_ 642 SplrShttrStsShttrElecErr "Spoiler Shutter Electrical Error Monitoring";
CM_ SG_ 642 SplrShttrStsShttrPosnRaw "Current position of spoiler shutter actuator.";
CM_ SG_ 642 SplrShttrStsShttrSnsrFlt "Spoiler shutter sensor fault";
CM_ SG_ 642 SplrShttrStsShttrTErr "Spoiler Shutter Over Temperature Monitoring";
CM_ SG_ 642 SplrShttrStsShttrULoErr "Spoiler shutter supply voltage error";
CM_ SG_ 131 EngSt1WdStsChks "checksum";
CM_ SG_ 131 EngSt1WdStsCntr "counter";
CM_ SG_ 131 EngSt1WdStsEngSt1WdSts "Signaling the state of the powerpack";
CM_ SG_ 131 JOACDampIndex "JOAC(Jerk Oscillation Active Control) Damping Factor";
CM_ SG_ 131 MvEMSpdReq "Requested Speed for Speed Control Mode";
CM_ SG_ 131 MvEMTqReq "Requested Torque for Torque Control Mode";
CM_ SG_ 752 EngSt1WdSts1 "Signaling the state of the powerpack(without E2E)";
CM_ SG_ 1431 PSCMdevelpsignalgroupreq1Functiondevpsignalgroup1 "develop signal group request";
CM_ SG_ 1431 PSCMdevelpsignalgroupreq1Functiondevpsignalgroup2 "develop signal group request";
CM_ SG_ 1431 PSCMdevelpsignalgroupreq1Functiondevpsignalgroup3 "develop signal group request";
CM_ SG_ 1431 PSCMdevelpsignalgroupreq1Functiondevpsignalgroup4 "develop signal group request";
CM_ SG_ 1431 PSCMdevelpsignalgroupreq1Functiondevpsignalgroup5 "develop signal group request";
CM_ SG_ 1431 PSCMdevelpsignalgroupreq1Functiondevpsignalgroup6 "develop signal group request";
CM_ SG_ 1431 PSCMdevelpsignalgroupreq1Functiondevpsignalgroup7 "develop signal group request";
CM_ SG_ 1431 PSCMdevelpsignalgroupreq1Functiondevpsignalgroup8 "develop signal group request";
CM_ SG_ 1432 VDDMdevelpsignalgroupreq1Functiondevpsignalgroup1 "develop signal group request";
CM_ SG_ 1432 VDDMdevelpsignalgroupreq1Functiondevpsignalgroup2 "develop signal group request";
CM_ SG_ 1432 VDDMdevelpsignalgroupreq1Functiondevpsignalgroup3 "develop signal group request";
CM_ SG_ 1432 VDDMdevelpsignalgroupreq1Functiondevpsignalgroup4 "develop signal group request";
CM_ SG_ 1432 VDDMdevelpsignalgroupreq1Functiondevpsignalgroup5 "develop signal group request";
CM_ SG_ 1432 VDDMdevelpsignalgroupreq1Functiondevpsignalgroup6 "develop signal group request";
CM_ SG_ 1432 VDDMdevelpsignalgroupreq1Functiondevpsignalgroup7 "develop signal group request";
CM_ SG_ 1432 VDDMdevelpsignalgroupreq1Functiondevpsignalgroup8 "develop signal group request";
CM_ SG_ 1433 VDDMdevelpsignalgroupreq2Functiondevpsignalgroup1 "VDDM development signal";
CM_ SG_ 1433 VDDMdevelpsignalgroupreq2Functiondevpsignalgroup2 "VDDM development signal";
CM_ SG_ 1433 VDDMdevelpsignalgroupreq2Functiondevpsignalgroup3 "VDDM development signal";
CM_ SG_ 1433 VDDMdevelpsignalgroupreq2Functiondevpsignalgroup4 "VDDM development signal";
CM_ SG_ 1433 VDDMdevelpsignalgroupreq2Functiondevpsignalgroup5 "VDDM development signal";
CM_ SG_ 1433 VDDMdevelpsignalgroupreq2Functiondevpsignalgroup6 "VDDM development signal";
CM_ SG_ 1433 VDDMdevelpsignalgroupreq2Functiondevpsignalgroup7 "VDDM development signal";
CM_ SG_ 1433 VDDMdevelpsignalgroupreq2Functiondevpsignalgroup8 "VDDM development signal";
CM_ SG_ 213 MvEMIDc "Continuous side current during Machine Mode.Invaild MvEMIDc= 0x5DC";
CM_ SG_ 213 MvEMModSts "Machine Mode status";
CM_ SG_ 213 MvEMTqActSafe1MvIsgTq "Estimated torque during machine mode";
CM_ SG_ 213 MvEMTqActSafe1MvIsgTqChks "Chks";
CM_ SG_ 213 MvEMTqActSafe1MvIsgTqCntr "Cntr";
CM_ SG_ 213 MvEMTqActSafe1QualityFactor "QualityFactor";
CM_ SG_ 213 MvEMUDc "+BAT48V terminal voltage.Invaild MvEMUDc= 0x3FF";
CM_ SG_ 225 MvEMLimnIndcn "bit0: MvEMFltLvl1,bit1: MvEMFltLvl2,bit2: MvEMFltLvl3,bit3: MvEMFltLvl4,bit4: MvIsgMILReq,bit5: MvIsgSVSReq";
CM_ SG_ 225 MvEMSpdActSgn "Machine rotor speed measure.Invaild MvEMSpdActSgn= 0x9C40";
CM_ SG_ 225 MvEMTqAvlMax "Potential reachable torque during permanent mode.Invaild MvEMTqAvlMax= 0x00";
CM_ SG_ 225 MvEMTqAvlMin "Potential reachable torque during permanent mode.Invaild MvEMTqAvlMin= 0x00";
CM_ SG_ 499 MvEMFltSts "bit0: CalibErr,bit1: CANErr,bit2: OverSpd,bit3: OverVoltDC,bit4: OverCurrntDC,bit5: MachineSensorErr,bit6: InverterSensorErr,bit7: UnderVolt,bit8: OverVolt,bit9: PhaseErr,bit10: OverCurrntPhase,bit11: OverTmpRotor,bit12: OverTmpStator,bit13: OverTmpCtlBd,bit14: OverTmpPwrModule,bit15: Reserved";
CM_ SG_ 499 MvEMTRate "MVEM Temperature Rate.Invaild MvEMTRate= 0x7F";
CM_ SG_ 529 ImobEngChk3v2ImobEngChkSts "Message from IGM to CEM that challenge is available and 7 bytes of challenge. Message to CEM Challenge available (v2)";
CM_ SG_ 529 ImobEngChk3v2ImobEngDataChk0 "Message from IGM to CEM that challenge is available and 7 bytes of challenge. Byte 0. (v2)";
CM_ SG_ 529 ImobEngChk3v2ImobEngDataChk1 "Message from IGM to CEM that challenge is available and 7 bytes of challenge. Byte 1. (v2)";
CM_ SG_ 529 ImobEngChk3v2ImobEngDataChk2 "Message from IGM to CEM that challenge is available and 7 bytes of challenge. Byte 2. (v2)";
CM_ SG_ 529 ImobEngChk3v2ImobEngDataChk3 "Message from IGM to CEM that challenge is available and 7 bytes of challenge. Byte 3. (v2)";
CM_ SG_ 529 ImobEngChk3v2ImobEngDataChk4 "Message from IGM to CEM that challenge is available and 7 bytes of challenge. Byte 04. (v2)";
CM_ SG_ 529 ImobEngChk3v2ImobEngDataChk5 "Message from IGM to CEM that challenge is available and 7 bytes of challenge. Byte 5. (v2)";
CM_ SG_ 529 ImobEngChk3v2ImobEngDataChk6 "Message from IGM to CEM that challenge is available and 7 bytes of challenge. Byte 6 (v2)";
CM_ SG_ 529 ImobEngSts3v2 "Msg from MVEM to CEM immo status: Undefined, immobilised, motive mobilised or non motive mobilised.";
CM_ SG_ 235 PrkgPinionAgReqGroupParkAssiPinionAgReq "The requested steering pinion angle by the autonomous parking system.";
CM_ SG_ 235 PrkgPinionAgReqGroupParkAssiPinionAgReqChks "counter,For E2E Protection";
CM_ SG_ 235 PrkgPinionAgReqGroupParkAssiPinionAgReqCntr "CRC,to check the signal,For E2E Protection";
CM_ SG_ 235 PrkgPinionAgReqGroupQF "QF";
CM_ SG_ 246 ADL3LatCtrlStsADMod "Steering system AD mode status";
CM_ SG_ 246 ADL3LatCtrlStsChks "Counter of the signal group";
CM_ SG_ 246 ADL3LatCtrlStsCntr "Counter of the signal group";
CM_ SG_ 246 ADL3LatCtrlStsCtrlSts "Inform to AD systems which Channel (Primary/Secondary) signals is being used";
CM_ SG_ 246 ADL3LatCtrlStsDegraded "degraded";
CM_ SG_ 246 ADL3LatCtrlStsQf "quality factor";
CM_ SG_ 246 ADL3LatCtrlStsSts "- Green (2)- Full TJP function, neither input signal nor ECU internal error - Yellow (1)- TJP function but with minor error-  Red (0) - One or more Channel (Primary /Secondary) cant implement TJP for internal ECU or input signal error";
CM_ SG_ 246 DrvrSteerActvChks "Confirmation of driver steer actively Checksum";
CM_ SG_ 246 DrvrSteerActvCntr "Confirmation of driver steer actively Counter";
CM_ SG_ 246 DrvrSteerActvDrvrSteerActv "Indicates if the driver steers actively";
CM_ SG_ 246 FrntSteerFEstimd1 "FrntSteerFEstimd1 (Front Steer Force Estimated) provides estimates of the front steering rack force.";
CM_ SG_ 246 UBoostReqBySteerFrnt "UBoosReqBySteerFrnt is sent to the Electrical Management subsystem to request that sufficient electrical power is prodived for the steering system during special driving situations, e.g. parking manouvers.";
CM_ SG_ 70 LatCtrlModCfmdChks "Confirmation of lateral control request Confirmed lateral mode";
CM_ SG_ 70 LatCtrlModCfmdCntr "Confirmation of lateral control request Confirmed lateral mode";
CM_ SG_ 70 LatCtrlModCfmdLatCtrlMod "Confirmation of lateral control request Confirmed lateral mode";
CM_ SG_ 70 SteerServoSts "Status of lateral control request";
CM_ SG_ 70 SteerWhlTqAddl "Overlay torque from external requests";
CM_ SG_ 70 TqAssAddl "Total torque at motor";
CM_ SG_ 444 DrvrSteerWhlHldGroupDrvrSteerWhlHld "Hands on steering wheel information. Signal indicating whether the driver has his hands on the steering wheel or not.";
CM_ SG_ 444 DrvrSteerWhlHldGroupDrvrSteerWhlHldQly "Hands on steering wheel information. Confidence value for the DrvrSteerWhlHld estimation calculation, specifically indicating the confidence for the hands off state.";
CM_ SG_ 444 SteerErrReq "Sent from steering system to display to notify driver if no steering torque assist is available. Messages sent from Steering system to DIM";
CM_ SG_ 444 SteerExtFctStsChks "Confirmation of steer external function status Checksum";
CM_ SG_ 444 SteerExtFctStsCntr "Confirmation of steer external function status Counter";
CM_ SG_ 444 SteerExtFctStsDrvrSteerOvrd "Steering request of asking driver to take over";
CM_ SG_ 444 SteerExtFctStsExtFctLowerLimActive "Column  Torque Lower Limit ";
CM_ SG_ 444 SteerExtFctStsExtFctRateLimActive "External function rate Limit ";
CM_ SG_ 444 SteerExtFctStsExtFctUpperLimActive "Column Torque Upper Limit ";
CM_ SG_ 444 SteerExtFctStsExtSafeLimActive "External function torque output vs defined safety limiters ";
CM_ SG_ 444 SteerExtFctStsLatAgReqNotInRange "Pinion angle /current trajectory between primary and fall back ";
CM_ SG_ 444 SteerExtFctStsLatCtrlReqNotInRange "Lateral Ctrl request and primary and fall back ";
CM_ SG_ 444 SteerStsToParkAssi "SteerStsToParkAssi contains PSCM status related to execution of SAP.";
CM_ SG_ 955 PinionSteerAgMax1 "PinionSteerAgMax1 contains the current maximal pinion angle. Depends on tire size and vehicle type.";
CM_ SG_ 78 PinionSteerAgGroupChks "Checksum for PinionSteerAgGroup";
CM_ SG_ 78 PinionSteerAgGroupCntr "Counter for PinionSteerAgGroup";
CM_ SG_ 78 PinionSteerAgGroupPinionSteerAg1 "Calculated pinion steer angle at the front steering device";
CM_ SG_ 78 PinionSteerAgGroupPinionSteerAg1Qf "Quality factor for PinionSteerAg1";
CM_ SG_ 78 PinionSteerAgGroupPinionSteerAgSpd1 "Calculated pinion steer angle speed at the front steering device ";
CM_ SG_ 78 PinionSteerAgGroupPinionSteerAgSpd1Qf "Quality factor for PinionSteerAgSpd1";
CM_ SG_ 78 PinionSteerAgGroupSteerWhlTq "Torque on steering wheel";
CM_ SG_ 78 PinionSteerAgGroupSteerWhlTqQf "Quality factor for SteerWhlTq";
CM_ SG_ 1430 PSCMdevelpsignalgroupresp1Functiondevpsignalgroup1 "PSCM development signal";
CM_ SG_ 1430 PSCMdevelpsignalgroupresp1Functiondevpsignalgroup2 "PSCM development signal";
CM_ SG_ 1430 PSCMdevelpsignalgroupresp1Functiondevpsignalgroup3 "PSCM development signal";
CM_ SG_ 1430 PSCMdevelpsignalgroupresp1Functiondevpsignalgroup4 "PSCM development signal";
CM_ SG_ 1430 PSCMdevelpsignalgroupresp1Functiondevpsignalgroup5 "PSCM development signal";
CM_ SG_ 1430 PSCMdevelpsignalgroupresp1Functiondevpsignalgroup6 "PSCM development signal";
CM_ SG_ 1430 PSCMdevelpsignalgroupresp1Functiondevpsignalgroup7 "PSCM development signal";
CM_ SG_ 1430 PSCMdevelpsignalgroupresp1Functiondevpsignalgroup8 "PSCM development signal";
CM_ SG_ 64 SteerWhlSnsrAg "Actual steering wheel angle from the actual centre position of the steering wheel. ";
CM_ SG_ 64 SteerWhlSnsrAgSpd "Actual steering wheel angle from the actual centre position of the steering wheel. Steering angle speed with steering wheel rotation direction.  ";
CM_ SG_ 64 SteerWhlSnsrChks "Checksum for steering wheel sensor data.";
CM_ SG_ 64 SteerWhlSnsrCntr "Counter value for steering wheel sensor data.";
CM_ SG_ 64 SteerWhlSnsrQf "Qf for steering wheel sensor information";
CM_ SG_ 42 TrsmCluSlipPwrIntgl1Idx "Slip power integral 1 (100% means thermo shock) Slip power integral 1";
CM_ SG_ 42 TrsmCluSlipPwrIntgl1Qf "Slip power integral 1 (100% means thermo shock) Slip power integral quality factor 1";
CM_ SG_ 42 TrsmCluSlipPwrIntgl2Idx "Slip power integral 2 (100 percent means thermo shock) Slip power integral 2";
CM_ SG_ 42 TrsmCluSlipPwrIntgl2Qf "Slip power integral 2 (100 percent means thermo shock) Slip power integral quality factor 2";
CM_ SG_ 42 TrsmCluTqCp1 "Actual torque capacity Actual torque capacity 1";
CM_ SG_ 42 TrsmCluTqCp2 "Actual torque capacity Actual torque capacity 2";
CM_ SG_ 42 TrsmGearAct1 "Actual gear Actual gear 1";
CM_ SG_ 42 TrsmGearAct2 "Actual gear Actual gear 2";
CM_ SG_ 42 TrsmGearEngmtSts1 "Actual gear Actual gear engagement status 1";
CM_ SG_ 42 TrsmGearEngmtSts2 "Actual gear Actual gear engagement status 2";
CM_ SG_ 42 TrsmReqForPfmncRedn3 "TCM uses signal Transmission Request For Performance Reduction to send requests to ECM to activate the functionality Intended System Degradation (ISD). ISD will stage by stage reduce the maximum allowed torque for the engine over a number of driving cycles. Default signal - 0 (false)";
CM_ SG_ 48 TrsmNRecChks "E2E checksum";
CM_ SG_ 48 TrsmNRecCntr "Data counter";
CM_ SG_ 48 TrsmNRecInp1 "Transmission input / output speed and direction Transmission input speed 1";
CM_ SG_ 48 TrsmNRecInp2 "Transmission input / output speed and direction Transmission input speed 2";
CM_ SG_ 48 TrsmNRecInpDir1 "Transmission input / output speed and direction Transmission input speed direction 1";
CM_ SG_ 48 TrsmNRecInpDir2 "Transmission input / output speed and direction Transmission input speed direction 2";
CM_ SG_ 48 TrsmNRecInpQf1 "Transmission input / output speed and direction Transmission input speed quality factor 1";
CM_ SG_ 48 TrsmNRecInpQf2 "Transmission input / output speed and direction Transmission input speed quality factor 2";
CM_ SG_ 48 TrsmNRecOutp "Transmission input / output speed and direction Transmission output speed";
CM_ SG_ 48 TrsmNRecOutpDir "Transmission input / output speed and direction Transmission output speed direction";
CM_ SG_ 48 TrsmNRecOutpQf "Transmission input / output speed and direction Transmission output speed quality factor";
CM_ SG_ 53 TrsmCluSlipCtrlModSts "Actual slip mode";
CM_ SG_ 53 TrsmCluT1Qf "Clutch temperature 1 Clutch temperature quality factor 1";
CM_ SG_ 53 TrsmCluT1Val "Clutch temperature 1 Clutch temperature 1";
CM_ SG_ 53 TrsmCluT2Qf "Coding: -40 to 598,75. Estimated temperature is calculated within the clutch control software based upon the energy put into the clutch and the physical properties of the clutch that affect its ability to retain and dissipate heat. Clutch temperature quality factor 2";
CM_ SG_ 53 TrsmCluT2Val "Coding: -40 to 598,75. Estimated temperature is calculated within the clutch control software based upon the energy put into the clutch and the physical properties of the clutch that affect its ability to retain and dissipate heat. Clutch temperature 2";
CM_ SG_ 53 TrsmCluTqCpMaxInProgs1 "Transmission is maximizing torque capacity 1, actual torque does not follow the requested torque.";
CM_ SG_ 53 TrsmCluTqCpMaxInProgs2 "Transmission is maximizing torque capacity 2, actual torque does not follow the requested torque.";
CM_ SG_ 53 TrsmCluTqCpMaxPrio1 "Transmission need to maximize torque capacity 1";
CM_ SG_ 53 TrsmCluTqCpMaxPrio2 "Transmission need to maximize torque capacity 2";
CM_ SG_ 53 TrsmCluTqCpMinInProgs1 "Transmission is minimizing torque capacity 1, actual torque does not follow the requested torque.";
CM_ SG_ 53 TrsmCluTqCpMinInProgs2 "Transmission is minimizing torque capacity 2, actual torque does not follow the requested torque.";
CM_ SG_ 53 TrsmGearActrScanForRefActv "Gear actuator adaption in progress";
CM_ SG_ 53 TrsmGearActrScanForRefReq "Gear actuator adaption request";
CM_ SG_ 53 TrsmOilFlow "Transmission oil flow level";
CM_ SG_ 53 TrsmOperSts "Transmission operation status. Used for failsafe handling and avoidance. Default signal value - 0. Bit 0 - KL30-limited. Bit 1 - Wheellock avoidance active. Bit 2 - Reserved. Bit 3 - reserved. Bit 4 - Reserved. Bit 5 - Reserved";
CM_ SG_ 53 TrsmSlipCtrlReq "Transmission slip mode for adaption request";
CM_ SG_ 53 TrsmSoftRotReq1 "Soft antibalking request 1";
CM_ SG_ 53 TrsmSoftRotReq2 "Soft antibalking request 2";
CM_ SG_ 117 TrsmCluActrLimd1 "Clutch actuator has limited functionality 1";
CM_ SG_ 117 TrsmCluActrLimd2 "Clutch actuator has limited functionality 2";
CM_ SG_ 117 TrsmCluActrOff1 "Clutch actuator is off 1";
CM_ SG_ 117 TrsmCluActrOff2 "Clutch actuator is off 2";
CM_ SG_ 117 TrsmCluActrTLvl1 "Clutch actuator temperature level 1";
CM_ SG_ 117 TrsmCluActrTLvl2 "Clutch actuator temperature level 2";
CM_ SG_ 117 TrsmCluTqCpCorrln1 "Confidence level in torque capacity 1";
CM_ SG_ 117 TrsmCluTqCpCorrln2 "Confidence level in torque capacity 2";
CM_ SG_ 117 TrsmCluTqCpMax1 "Maximum torque capacity 1";
CM_ SG_ 117 TrsmCluTqCpMax2 "Maximum torque capacity 2";
CM_ SG_ 117 TrsmCluTqCpMinPrio1 "Transmission need to minimize torque capacity 1";
CM_ SG_ 117 TrsmCluTqCpMinPrio2 "Transmission need to minimize torque capacity 2";
CM_ SG_ 117 TrsmEndOfLineModActv "Factory adaption in progress";
CM_ SG_ 117 TrsmGbxActrOff "Gearbox actuator off";
CM_ SG_ 117 TrsmGearActrSts "Gear engagement confidence level";
CM_ SG_ 117 TrsmGearActrTLvl "Gear actuator temperature level";
CM_ SG_ 117 TrsmHardRotReq1 "Hard antibalking request 1";
CM_ SG_ 117 TrsmHardRotReq2 "Hard antibalking request 2";
CM_ SG_ 117 TrsmOilPmpTLvl "TrsmOilPmpTLvl";

// Attribute definitions
BA_DEF_  "Baudrate" INT 1000 1000000; // [bps]
BA_DEF_ BO_ "GenMsgSendType" ENUM "cyclic", "spontaneous", "not-used", "not-used", "not-used", "cyclicAndSpontaneous", "not-used", "cyclicIfActive", "NoMsgSendType"; // [us]
BA_DEF_ BO_ "GenMsgCycleTime" INT 0 65536; // [ms]
BA_DEF_ BO_ "GenMsgStartDelayTime" INT 0 65536; // [ms]
BA_DEF_ BO_ "GenMsgDelayTime" INT 0 65536; // [ms]
BA_DEF_ SG_ "GenSigSendType" ENUM "Cyclic","OnWrite","OnWriteWithRepetition","OnChange","OnChangeWithRepetition","IfActive","IfActiveWithRepetition","NoSigSendType";
BA_DEF_ SG_ "GenSigStartValue" HEX 0 80000000;
BA_DEF_ BU_ "NmAsrNodeIdentifier" INT 0 255;
BA_DEF_  "DBName" STRING;
BA_DEF_  "BusType" STRING;
BA_DEF_  "ProtocolType" STRING;
BA_DEF_ BO_ "GenMsgILSupport" ENUM "No","Yes";
BA_DEF_ BO_ "NmAsrMessage" ENUM "No","Yes";
BA_DEF_  "NmAsrBaseAddress" HEX 0 536870911;
BA_DEF_  "NmAsrMessageCount" INT 0 255;
BA_DEF_ BU_ "NodeLayerModules" STRING;
BA_DEF_ BU_ "NmAsrNode" ENUM "No","Yes";
BA_DEF_ BU_ "ILused" ENUM "No","Yes";
BA_DEF_ SG_ "GenSigFuncType" ENUM "NoFunction","n/a","n/a","n/a","n/a","n/a","n/a","n/a","n/a","n/a","n/a","n/a","n/a","n/a","n/a","CHK","CNTR","n/a","n/a","n/a","CNTR_AR_01","CRC_AR_01_BOTH","CRC_AR_01_ALT","CRC_AR_01_LOW","CRC_AR_01_NIBBLE","CNTR_AR_04","CRC_AR_04A","CNTR_AR_05","CRC_AR_05";
BA_DEF_ SG_ "GenSigDataID" STRING;

BA_DEF_DEF_ "GenSigStartValue" 0;
BA_DEF_DEF_ "GenSigSendType" "NoSigSendType";
BA_DEF_DEF_ "DBName" "";
BA_DEF_DEF_ "BusType" "";
BA_DEF_DEF_ "ProtocolType" "";
BA_DEF_DEF_ "GenMsgCycleTime" 0;
BA_DEF_DEF_ "GenMsgDelayTime" 0;
BA_DEF_DEF_ "GenMsgStartDelayTime" 0;
BA_DEF_DEF_ "GenMsgSendType" "NoMsgSendType";
BA_DEF_DEF_ "GenMsgILSupport" "Yes";
BA_DEF_DEF_ "NmAsrMessage" "No";
BA_DEF_DEF_ "NmAsrBaseAddress" 1280;
BA_DEF_DEF_ "NmAsrMessageCount" 64;
BA_DEF_DEF_ "NodeLayerModules" "CANoeILNLSPA.dll";
BA_DEF_DEF_ "NmAsrNode" "No";
BA_DEF_DEF_ "NmAsrNodeIdentifier" 0;
BA_DEF_DEF_ "ILused" "Yes";
BA_DEF_DEF_ "GenSigFuncType" "NoFunction";
BA_DEF_DEF_ "GenSigDataID" "";

// Network
BA_ "DBName" "ChassisCAN1";
BA_ "BusType" "CAN";
BA_ "ProtocolType" "CAN";
BA_ "Baudrate" 500000;
// ECU: ASDM
BA_ "NmAsrNodeIdentifier" BU_ ASDM 41;
BA_ "NmAsrNode" BU_ ASDM 1;
BA_ "NodeLayerModules" BU_ ASDM "CANoeILNLSPA.dll,AsrNM33.dll";
// ECU: ECM
BA_ "NmAsrNodeIdentifier" BU_ ECM 16;
BA_ "NmAsrNode" BU_ ECM 1;
BA_ "NodeLayerModules" BU_ ECM "CANoeILNLSPA.dll,AsrNM33.dll";
// ECU: ETC
BA_ "ILused" BU_ ETC 0;
// ECU: MVEM
BA_ "NmAsrNodeIdentifier" BU_ MVEM 50;
BA_ "NmAsrNode" BU_ MVEM 1;
BA_ "NodeLayerModules" BU_ MVEM "CANoeILNLSPA.dll,AsrNM33.dll";
// ECU: PAS
BA_ "NmAsrNodeIdentifier" BU_ PAS 40;
BA_ "NmAsrNode" BU_ PAS 1;
BA_ "NodeLayerModules" BU_ PAS "CANoeILNLSPA.dll,AsrNM33.dll";
// ECU: PSCM1
BA_ "NmAsrNodeIdentifier" BU_ PSCM1 35;
BA_ "NmAsrNode" BU_ PSCM1 1;
BA_ "NodeLayerModules" BU_ PSCM1 "CANoeILNLSPA.dll,AsrNM33.dll";
// ECU: SAS
BA_ "NmAsrNodeIdentifier" BU_ SAS 39;
BA_ "NmAsrNode" BU_ SAS 1;
BA_ "NodeLayerModules" BU_ SAS "CANoeILNLSPA.dll,AsrNM33.dll";
// ECU: TCM
BA_ "NmAsrNodeIdentifier" BU_ TCM 48;
BA_ "NmAsrNode" BU_ TCM 1;
BA_ "NodeLayerModules" BU_ TCM "CANoeILNLSPA.dll,AsrNM33.dll";
// ECU: VDDM
BA_ "NmAsrNodeIdentifier" BU_ VDDM 33;
BA_ "NmAsrNode" BU_ VDDM 1;
BA_ "NodeLayerModules" BU_ VDDM "CANoeILNLSPA.dll,AsrNM33.dll";
// Frame: AsdmChas1Fr01
BA_ "GenMsgSendType" BO_ 147 0;
BA_ "GenMsgCycleTime" BO_ 147 20.000;
BA_ "GenSigSendType" SG_ 147 AsyADL3FuncCtrlStsADMod 0;
BA_ "GenSigSendType" SG_ 147 AsyADL3FuncCtrlStsChks 0;
BA_ "GenSigFuncType" SG_ 147 AsyADL3FuncCtrlStsChks 15;
BA_ "GenSigDataID" SG_ 147 AsyADL3FuncCtrlStsChks "0xD17";
BA_ "GenSigSendType" SG_ 147 AsyADL3FuncCtrlStsCntr 0;
BA_ "GenSigFuncType" SG_ 147 AsyADL3FuncCtrlStsCntr 16;
BA_ "GenSigSendType" SG_ 147 AsyADL3FuncCtrlStsCtrlSts 0;
BA_ "GenSigSendType" SG_ 147 AsyADL3FuncCtrlStsDegraded 0;
BA_ "GenSigSendType" SG_ 147 AsyADL3FuncCtrlStsQf 0;
BA_ "GenSigSendType" SG_ 147 AsyADL3FuncCtrlStsSts 0;
BA_ "GenSigSendType" SG_ 147 AsyADModeReqADActiveReq 0;
BA_ "GenSigSendType" SG_ 147 AsyADModeReqADDeactiveReq 0;
BA_ "GenSigSendType" SG_ 147 AsyADModeReqChks 0;
BA_ "GenSigFuncType" SG_ 147 AsyADModeReqChks 15;
BA_ "GenSigDataID" SG_ 147 AsyADModeReqChks "0xD18";
BA_ "GenSigSendType" SG_ 147 AsyADModeReqCntr 0;
BA_ "GenSigFuncType" SG_ 147 AsyADModeReqCntr 16;
BA_ "GenSigSendType" SG_ 147 PASFuncActive 0;
BA_ "GenSigSendType" SG_ 147 RctaBrkReqQM 0;
BA_ "GenSigSendType" SG_ 147 RcwmBrkReqQM 0;
// Frame: AsdmChas1Fr03
BA_ "GenMsgSendType" BO_ 51 0;
BA_ "GenMsgCycleTime" BO_ 51 10.000;
BA_ "GenSigStartValue" SG_ 51 AgCtrlTqLowrLim 240;
BA_ "GenSigSendType" SG_ 51 AgCtrlTqLowrLim 0;
BA_ "GenSigStartValue" SG_ 51 AgCtrlTqUpprLim 240;
BA_ "GenSigSendType" SG_ 51 AgCtrlTqUpprLim 0;
BA_ "GenSigStartValue" SG_ 51 AsyPinionAgReqSafeAsyPinionAgReq 14848;
BA_ "GenSigSendType" SG_ 51 AsyPinionAgReqSafeAsyPinionAgReq 0;
BA_ "GenSigSendType" SG_ 51 AsyPinionAgReqSafeAsyPinionAgReqChks 0;
BA_ "GenSigFuncType" SG_ 51 AsyPinionAgReqSafeAsyPinionAgReqChks 15;
BA_ "GenSigDataID" SG_ 51 AsyPinionAgReqSafeAsyPinionAgReqChks "0x2F7";
BA_ "GenSigSendType" SG_ 51 AsyPinionAgReqSafeAsyPinionAgReqCntr 0;
BA_ "GenSigFuncType" SG_ 51 AsyPinionAgReqSafeAsyPinionAgReqCntr 16;
BA_ "GenSigSendType" SG_ 51 PinionAgRateLim 0;
// Frame: AsdmChas1NMFr
BA_ "GenMsgSendType" BO_ 1321 1;
BA_ "GenMsgDelayTime" BO_ 1321 20.000;
BA_ "GenMsgILSupport" BO_ 1321 0;
BA_ "NmAsrMessage" BO_ 1321 1;
// Frame: EcmChas1BsgFr32
BA_ "GenMsgSendType" BO_ 565 0;
BA_ "GenMsgCycleTime" BO_ 565 100.000;
BA_ "GenSigStartValue" SG_ 565 MvEMIDCMin 500;
BA_ "GenSigSendType" SG_ 565 MvEMIDCMin 0;
BA_ "GenSigStartValue" SG_ 565 MvEMUDCMaxFullLim 540;
BA_ "GenSigSendType" SG_ 565 MvEMUDCMaxFullLim 0;
BA_ "GenSigStartValue" SG_ 565 MvEMUDCMaxUnLim 520;
BA_ "GenSigSendType" SG_ 565 MvEMUDCMaxUnLim 0;
BA_ "GenSigStartValue" SG_ 565 MvEMUDCMinFullLim 360;
BA_ "GenSigSendType" SG_ 565 MvEMUDCMinFullLim 0;
BA_ "GenSigStartValue" SG_ 565 MvEMUDCMinUnLim 340;
BA_ "GenSigSendType" SG_ 565 MvEMUDCMinUnLim 0;
// Frame: EcmChas1BsgFr33
BA_ "GenMsgSendType" BO_ 631 0;
BA_ "GenMsgCycleTime" BO_ 631 1000.000;
BA_ "GenSigSendType" SG_ 631 MvEMCooltFlowForDtElec 0;
BA_ "GenSigStartValue" SG_ 631 MvEMCooltT 50;
BA_ "GenSigSendType" SG_ 631 MvEMCooltT 0;
// Frame: EcmChas1BsgFr37
BA_ "GenMsgSendType" BO_ 564 0;
BA_ "GenMsgCycleTime" BO_ 564 100.000;
BA_ "GenSigSendType" SG_ 564 MonrCycCmpl 0;
BA_ "GenSigSendType" SG_ 564 MvEMIDCMax 0;
BA_ "GenSigStartValue" SG_ 564 MvEMTqMax 700;
BA_ "GenSigSendType" SG_ 564 MvEMTqMax 0;
BA_ "GenSigStartValue" SG_ 564 MvEMTqMin 700;
BA_ "GenSigSendType" SG_ 564 MvEMTqMin 0;
BA_ "GenSigSendType" SG_ 564 MvEMUReq 0;
BA_ "GenSigSendType" SG_ 564 PrpsnSysActv 0;
// Frame: EcmChas1BsgFr38
BA_ "GenMsgSendType" BO_ 226 0;
BA_ "GenMsgCycleTime" BO_ 226 20.000;
BA_ "GenSigSendType" SG_ 226 MvEMModReqChks 0;
BA_ "GenSigFuncType" SG_ 226 MvEMModReqChks 15;
BA_ "GenSigDataID" SG_ 226 MvEMModReqChks "0x1F";
BA_ "GenSigSendType" SG_ 226 MvEMModReqCntr 0;
BA_ "GenSigFuncType" SG_ 226 MvEMModReqCntr 16;
BA_ "GenSigStartValue" SG_ 226 MvEMModReqMvEMModReq 1;
BA_ "GenSigSendType" SG_ 226 MvEMModReqMvEMModReq 0;
BA_ "GenSigStartValue" SG_ 226 MvEMSpdGrdtLim 2000;
BA_ "GenSigSendType" SG_ 226 MvEMSpdGrdtLim 0;
BA_ "GenSigStartValue" SG_ 226 MvEMTqGrdtLim 10000;
BA_ "GenSigSendType" SG_ 226 MvEMTqGrdtLim 0;
// Frame: EcmChas1BsgFr40
BA_ "GenMsgSendType" BO_ 134 0;
BA_ "GenMsgCycleTime" BO_ 134 50.000;
BA_ "GenSigSendType" SG_ 134 AntiJerkSelect 0;
BA_ "GenSigSendType" SG_ 134 DrvgCyc 0;
BA_ "GenSigStartValue" SG_ 134 JOACEnbReq 1;
BA_ "GenSigSendType" SG_ 134 JOACEnbReq 0;
BA_ "GenSigStartValue" SG_ 134 JOACFreqIndex 1;
BA_ "GenSigSendType" SG_ 134 JOACFreqIndex 0;
BA_ "GenSigStartValue" SG_ 134 JOACModulation 1;
BA_ "GenSigSendType" SG_ 134 JOACModulation 0;
BA_ "GenSigSendType" SG_ 134 JOACTrqMax 0;
// Frame: EcmChas1BsgFr41
BA_ "GenMsgSendType" BO_ 544 0;
BA_ "GenMsgCycleTime" BO_ 544 100.000;
BA_ "GenSigSendType" SG_ 544 AccrPedlRatAccrPedlRat 0;
BA_ "GenSigSendType" SG_ 544 AccrPedlRatChks 0;
BA_ "GenSigFuncType" SG_ 544 AccrPedlRatChks 15;
BA_ "GenSigDataID" SG_ 544 AccrPedlRatChks "0x364";
BA_ "GenSigSendType" SG_ 544 AccrPedlRatCntr 0;
BA_ "GenSigFuncType" SG_ 544 AccrPedlRatCntr 16;
BA_ "GenSigSendType" SG_ 544 DenoOfDiagcRateGen 0;
BA_ "GenSigSendType" SG_ 544 DrvgCycToClrPrmntDtc 0;
BA_ "GenSigStartValue" SG_ 544 EngTEngT 50;
BA_ "GenSigSendType" SG_ 544 EngTEngT 0;
BA_ "GenSigSendType" SG_ 544 EngTQf 0;
BA_ "GenSigSendType" SG_ 544 IuprDenominatorInhb 0;
BA_ "GenSigSendType" SG_ 544 MvEMVoltGrdtLim 0;
// Frame: EcmChas1BsgFr42
BA_ "GenMsgSendType" BO_ 530 0;
BA_ "GenMsgCycleTime" BO_ 530 100.000;
BA_ "GenSigSendType" SG_ 530 EngTiOn 0;
BA_ "GenSigSendType" SG_ 530 LoadValCalcd 0;
BA_ "GenSigSendType" SG_ 530 ThrPos 0;
// Frame: EcmChas1Fr01
BA_ "GenMsgSendType" BO_ 32 0;
BA_ "GenMsgCycleTime" BO_ 32 10.000;
BA_ "GenSigSendType" SG_ 32 PtCluSlipCtrlModReq 0;
BA_ "GenSigSendType" SG_ 32 PtCluSlipCtrlReq 0;
BA_ "GenSigSendType" SG_ 32 PtCluSlipCtrlSpdReq 0;
BA_ "GenSigSendType" SG_ 32 PtCluTqCpReq1 0;
BA_ "GenSigSendType" SG_ 32 PtCluTqCpReq2 0;
BA_ "GenSigSendType" SG_ 32 PtEngTqDstbcActv 0;
BA_ "GenSigSendType" SG_ 32 PtEngTqModlnSts 0;
BA_ "GenSigSendType" SG_ 32 PtGearActtnReq3 0;
BA_ "GenSigSendType" SG_ 32 PtRotReqAckd1 0;
BA_ "GenSigSendType" SG_ 32 PtRotReqAckd2 0;
// Frame: EcmChas1Fr02
BA_ "GenMsgSendType" BO_ 37 0;
BA_ "GenMsgCycleTime" BO_ 37 10.000;
BA_ "GenSigSendType" SG_ 37 PtCluTqCpMaxCmd1 0;
BA_ "GenSigSendType" SG_ 37 PtCluTqCpMaxCmd2 0;
BA_ "GenSigSendType" SG_ 37 PtCluTqCpMinCmd1 0;
BA_ "GenSigSendType" SG_ 37 PtCluTqCpMinCmd2 0;
BA_ "GenSigSendType" SG_ 37 PtDirAllwdToTrsmActrChks 0;
BA_ "GenSigFuncType" SG_ 37 PtDirAllwdToTrsmActrChks 15;
BA_ "GenSigDataID" SG_ 37 PtDirAllwdToTrsmActrChks "0xC4";
BA_ "GenSigSendType" SG_ 37 PtDirAllwdToTrsmActrCntr 0;
BA_ "GenSigFuncType" SG_ 37 PtDirAllwdToTrsmActrCntr 16;
BA_ "GenSigSendType" SG_ 37 PtDirAllwdToTrsmActrFwd 0;
BA_ "GenSigSendType" SG_ 37 PtDirAllwdToTrsmActrNeut 0;
BA_ "GenSigSendType" SG_ 37 PtDirAllwdToTrsmActrParkRls 0;
BA_ "GenSigSendType" SG_ 37 PtDirAllwdToTrsmActrRvs 0;
BA_ "GenSigSendType" SG_ 37 PtGearActrAdpnCmd 0;
BA_ "GenSigSendType" SG_ 37 PtGearActtnAllwdSts1 0;
BA_ "GenSigSendType" SG_ 37 PtGearActtnAllwdSts2 0;
BA_ "GenSigSendType" SG_ 37 PtGearActtnModReq 0;
BA_ "GenSigSendType" SG_ 37 PtGearActtnPfmncReq 0;
BA_ "GenSigSendType" SG_ 37 PtGearActtnPrio 0;
BA_ "GenSigSendType" SG_ 37 PtGearActtnReq1 0;
BA_ "GenSigSendType" SG_ 37 PtGearActtnReq2 0;
// Frame: EcmChas1Fr03
BA_ "GenMsgSendType" BO_ 697 0;
BA_ "GenMsgCycleTime" BO_ 697 150.000;
BA_ "GenSigSendType" SG_ 697 EngPmpStatCooltPmpDryErr 0;
BA_ "GenSigSendType" SG_ 697 EngPmpStatCooltPmpEmgyModSts 0;
BA_ "GenSigSendType" SG_ 697 EngPmpStatCooltPmpErrSts 0;
BA_ "GenSigSendType" SG_ 697 EngPmpStatCooltPmpI 0;
BA_ "GenSigSendType" SG_ 697 EngPmpStatCooltPmpIErr 0;
BA_ "GenSigSendType" SG_ 697 EngPmpStatCooltPmpMonrSpd 0;
BA_ "GenSigSendType" SG_ 697 EngPmpStatCooltPmpPostRunSts 0;
BA_ "GenSigSendType" SG_ 697 EngPmpStatCooltPmpSetPostRunReq 0;
BA_ "GenSigSendType" SG_ 697 EngPmpStatCooltPmpSetSpdReq 0;
BA_ "GenSigSendType" SG_ 697 EngPmpStatCooltPmpSpd 0;
BA_ "GenSigStartValue" SG_ 697 EngPmpStatCooltPmpT 100;
BA_ "GenSigSendType" SG_ 697 EngPmpStatCooltPmpT 0;
BA_ "GenSigSendType" SG_ 697 EngPmpStatCooltPmpTErr 0;
BA_ "GenSigSendType" SG_ 697 EngPmpStatCooltPmpU 0;
BA_ "GenSigSendType" SG_ 697 EngPmpStatCooltPmpUErr 0;
BA_ "GenSigSendType" SG_ 697 EngPmpStatCooltPmpUnstallSts 0;
// Frame: EcmChas1Fr04
BA_ "GenMsgSendType" BO_ 80 0;
BA_ "GenMsgCycleTime" BO_ 80 10.000;
BA_ "GenSigSendType" SG_ 80 EngN2 0;
BA_ "GenSigStartValue" SG_ 80 PtCluTq2PtCluTq 1024;
BA_ "GenSigSendType" SG_ 80 PtCluTq2PtCluTq 0;
BA_ "GenSigSendType" SG_ 80 PtCluTq2PtCluTqQly 0;
BA_ "GenSigStartValue" SG_ 80 PtCluTq2Req 1024;
BA_ "GenSigSendType" SG_ 80 PtCluTq2Req 0;
BA_ "GenSigStartValue" SG_ 80 PtCluTq2ReqWoTrsmIntv 1024;
BA_ "GenSigSendType" SG_ 80 PtCluTq2ReqWoTrsmIntv 0;
// Frame: EcmChas1Fr07
BA_ "GenMsgSendType" BO_ 554 0;
BA_ "GenMsgCycleTime" BO_ 554 100.000;
BA_ "GenSigSendType" SG_ 554 CmprFbCmprI 0;
BA_ "GenSigSendType" SG_ 554 CmprFbCmprIPha 0;
BA_ "GenSigSendType" SG_ 554 CmprFbCmprSpd 0;
BA_ "GenSigSendType" SG_ 554 CmprFbCmprSts1 0;
BA_ "GenSigSendType" SG_ 554 CmprFbCmprSts2 0;
BA_ "GenSigStartValue" SG_ 554 CmprFbCmprT1 50;
BA_ "GenSigSendType" SG_ 554 CmprFbCmprT1 0;
BA_ "GenSigStartValue" SG_ 554 CmprFbCmprT2 50;
BA_ "GenSigSendType" SG_ 554 CmprFbCmprT2 0;
BA_ "GenSigSendType" SG_ 554 CmprFbCmprU 0;
// Frame: EcmChas1Fr08
BA_ "GenMsgSendType" BO_ 1111 0;
BA_ "GenMsgCycleTime" BO_ 1111 50.000;
BA_ "GenSigSendType" SG_ 1111 PtTqAtWhlFrntActChks 0;
BA_ "GenSigFuncType" SG_ 1111 PtTqAtWhlFrntActChks 15;
BA_ "GenSigDataID" SG_ 1111 PtTqAtWhlFrntActChks "0x4E";
BA_ "GenSigSendType" SG_ 1111 PtTqAtWhlFrntActCntr 0;
BA_ "GenSigFuncType" SG_ 1111 PtTqAtWhlFrntActCntr 16;
BA_ "GenSigSendType" SG_ 1111 PtTqAtWhlFrntActPtTqAtAxleFrntAct 0;
BA_ "GenSigSendType" SG_ 1111 PtTqAtWhlFrntActPtTqAtWhlFrntLeAct 0;
BA_ "GenSigSendType" SG_ 1111 PtTqAtWhlFrntActPtTqAtWhlFrntRiAct 0;
BA_ "GenSigSendType" SG_ 1111 PtTqAtWhlFrntActPtTqAtWhlsFrntQly 0;
// Frame: EcmChas1Fr09
BA_ "GenMsgSendType" BO_ 708 0;
BA_ "GenMsgCycleTime" BO_ 708 130.000;
BA_ "GenSigSendType" SG_ 708 FanPwmReq 0;
BA_ "GenSigSendType" SG_ 708 PtVehSpdMaxChks 0;
BA_ "GenSigSendType" SG_ 708 PtVehSpdMaxCntr 0;
BA_ "GenSigStartValue" SG_ 708 PtVehSpdMaxReq 250;
BA_ "GenSigSendType" SG_ 708 PtVehSpdMaxReq 0;
BA_ "GenSigSendType" SG_ 708 WtrPmpAuxReq 0;
// Frame: EcmChas1Fr11
BA_ "GenMsgSendType" BO_ 730 0;
BA_ "GenMsgCycleTime" BO_ 730 130.000;
BA_ "GenSigSendType" SG_ 730 HvBattPmpStatCooltPmpDryErr 0;
BA_ "GenSigSendType" SG_ 730 HvBattPmpStatCooltPmpEmgyModSts 0;
BA_ "GenSigSendType" SG_ 730 HvBattPmpStatCooltPmpErrSts 0;
BA_ "GenSigSendType" SG_ 730 HvBattPmpStatCooltPmpI 0;
BA_ "GenSigSendType" SG_ 730 HvBattPmpStatCooltPmpIErr 0;
BA_ "GenSigSendType" SG_ 730 HvBattPmpStatCooltPmpMonrSpd 0;
BA_ "GenSigSendType" SG_ 730 HvBattPmpStatCooltPmpPostRunSts 0;
BA_ "GenSigSendType" SG_ 730 HvBattPmpStatCooltPmpSetPostRunReq 0;
BA_ "GenSigSendType" SG_ 730 HvBattPmpStatCooltPmpSetSpdReq 0;
BA_ "GenSigSendType" SG_ 730 HvBattPmpStatCooltPmpSpd 0;
BA_ "GenSigStartValue" SG_ 730 HvBattPmpStatCooltPmpT 100;
BA_ "GenSigSendType" SG_ 730 HvBattPmpStatCooltPmpT 0;
BA_ "GenSigSendType" SG_ 730 HvBattPmpStatCooltPmpTErr 0;
BA_ "GenSigSendType" SG_ 730 HvBattPmpStatCooltPmpU 0;
BA_ "GenSigSendType" SG_ 730 HvBattPmpStatCooltPmpUErr 0;
BA_ "GenSigSendType" SG_ 730 HvBattPmpStatCooltPmpUnstallSts 0;
// Frame: EcmChas1Fr12
BA_ "GenMsgSendType" BO_ 859 0;
BA_ "GenMsgCycleTime" BO_ 859 170.000;
BA_ "GenSigSendType" SG_ 859 ResrvdSigForCCM1 0;
BA_ "GenSigSendType" SG_ 859 ResrvdSigForCCM2 0;
BA_ "GenSigSendType" SG_ 859 ResrvdSigForCCM3 0;
BA_ "GenSigSendType" SG_ 859 ResrvdSigForCCM4 0;
// Frame: EcmChas1Fr13
BA_ "GenMsgSendType" BO_ 871 0;
BA_ "GenMsgCycleTime" BO_ 871 200.000;
BA_ "GenSigStartValue" SG_ 871 BookChrgnTarValFb 1000;
BA_ "GenSigSendType" SG_ 871 BookChrgnTarValFb 0;
BA_ "GenSigStartValue" SG_ 871 DchaChrgnTarValFb 200;
BA_ "GenSigSendType" SG_ 871 DchaChrgnTarValFb 0;
BA_ "GenSigSendType" SG_ 871 HvBattPmpCmdCooltPmpPostRunReq 0;
BA_ "GenSigSendType" SG_ 871 HvBattPmpCmdCooltPmpSpdReq 0;
BA_ "GenSigSendType" SG_ 871 ReEvapVlvReq 0;
// Frame: EcmChas1Fr16
BA_ "GenMsgSendType" BO_ 979 0;
BA_ "GenMsgCycleTime" BO_ 979 260.000;
BA_ "GenSigSendType" SG_ 979 CmprReqCmprSpdReq 0;
BA_ "GenSigSendType" SG_ 979 GrlShttrDmdShttrCalEna 0;
BA_ "GenSigSendType" SG_ 979 GrlShttrDmdShttrPosnReq 0;
BA_ "GenSigSendType" SG_ 979 SplrShttrDmdShttrCalEna 0;
BA_ "GenSigSendType" SG_ 979 SplrShttrDmdShttrPosnReq 0;
// Frame: EcmChas1Fr17
BA_ "GenMsgSendType" BO_ 1039 0;
BA_ "GenMsgCycleTime" BO_ 1039 300.000;
BA_ "GenSigSendType" SG_ 1039 CmprReqAcCapReqOvr 0;
BA_ "GenSigSendType" SG_ 1039 CmprReqCluReqOvr 0;
BA_ "GenSigSendType" SG_ 1039 EldtPmpCmdCooltPmpPostRunReq 0;
BA_ "GenSigSendType" SG_ 1039 EldtPmpCmdCooltPmpSpdReq 0;
BA_ "GenSigSendType" SG_ 1039 EngCooltPmpSpdReqCooltPmpPostRunReq 0;
BA_ "GenSigSendType" SG_ 1039 EngCooltPmpSpdReqCooltPmpSpdReq 0;
BA_ "GenSigSendType" SG_ 1039 TocCooltPmpReq 0;
// Frame: EcmChas1Fr18
BA_ "GenMsgSendType" BO_ 563 0;
BA_ "GenMsgCycleTime" BO_ 563 100.000;
BA_ "GenSigSendType" SG_ 563 CmprRunTime 0;
BA_ "GenSigSendType" SG_ 563 HeatrPmpIAct 0;
BA_ "GenSigSendType" SG_ 563 HeatrPmpPwrCns 0;
BA_ "GenSigSendType" SG_ 563 TrsmSailModReq 0;
// Frame: EcmChas1Fr19
BA_ "GenMsgSendType" BO_ 991 0;
BA_ "GenMsgCycleTime" BO_ 991 270.000;
BA_ "GenSigSendType" SG_ 991 AcTqOvr 0;
BA_ "GenSigSendType" SG_ 991 FanPwmReqForEldt 0;
BA_ "GenSigSendType" SG_ 991 FanPwrCns 0;
BA_ "GenSigSendType" SG_ 991 HvCooltHeatrICnsSig 0;
// Frame: EcmChas1Fr21
BA_ "GenMsgSendType" BO_ 304 0;
BA_ "GenMsgCycleTime" BO_ 304 25.000;
BA_ "GenSigSendType" SG_ 304 AccrpedlSts 0;
BA_ "GenSigSendType" SG_ 304 BsgDcDcPmpCmdCooltPmpPostRunReq 0;
BA_ "GenSigSendType" SG_ 304 BsgDcDcPmpCmdCooltPmpSpdReq 0;
BA_ "GenSigSendType" SG_ 304 CnvnAllwd 0;
BA_ "GenSigSendType" SG_ 304 EngNSafeEngN 0;
BA_ "GenSigSendType" SG_ 304 EngNSafeEngNChks 0;
BA_ "GenSigFuncType" SG_ 304 EngNSafeEngNChks 15;
BA_ "GenSigDataID" SG_ 304 EngNSafeEngNChks "0x44";
BA_ "GenSigSendType" SG_ 304 EngNSafeEngNCntr 0;
BA_ "GenSigFuncType" SG_ 304 EngNSafeEngNCntr 16;
BA_ "GenSigSendType" SG_ 304 EngNSafeEngNGrdt 0;
// Frame: EcmChas1Fr22
BA_ "GenMsgSendType" BO_ 1135 0;
BA_ "GenMsgCycleTime" BO_ 1135 400.000;
BA_ "GenSigSendType" SG_ 1135 BattCooltIndcnReq 0;
BA_ "GenSigSendType" SG_ 1135 CooltFlowInCmptmtCirc 0;
BA_ "GenSigSendType" SG_ 1135 EngTRefSts 0;
BA_ "GenSigStartValue" SG_ 1135 EngTRefT1 50;
BA_ "GenSigSendType" SG_ 1135 EngTRefT1 0;
BA_ "GenSigStartValue" SG_ 1135 EngTRefT2 50;
BA_ "GenSigSendType" SG_ 1135 EngTRefT2 0;
BA_ "GenSigSendType" SG_ 1135 MvIsgDcDcBattFlt 0;
BA_ "GenSigSendType" SG_ 1135 MvIsgRBSModDisp 0;
BA_ "GenSigSendType" SG_ 1135 TelltlPwrLoss 0;
// Frame: EcmChas1Fr23
BA_ "GenMsgSendType" BO_ 576 0;
BA_ "GenMsgCycleTime" BO_ 576 800.000;
BA_ "GenSigSendType" SG_ 576 HeatrPmpSpdAct 0;
BA_ "GenSigSendType" SG_ 576 HeatrPmpSpdReq 0;
BA_ "GenSigSendType" SG_ 576 HeatrPmpUAct 0;
BA_ "GenSigSendType" SG_ 576 HvBattPmpPwrCns 0;
BA_ "GenSigSendType" SG_ 576 PostHeatgRunTiEstimd 0;
// Frame: EcmChas1Fr24
BA_ "GenMsgSendType" BO_ 455 0;
BA_ "GenMsgCycleTime" BO_ 455 30.000;
BA_ "GenSigSendType" SG_ 455 HvActvSts 0;
BA_ "GenSigSendType" SG_ 455 MvBattRgnPerc 0;
BA_ "GenSigSendType" SG_ 455 PtTrsmOilFlowReq 0;
// Frame: EcmChas1Fr25
BA_ "GenMsgSendType" BO_ 587 0;
BA_ "GenMsgCycleTime" BO_ 587 100.000;
BA_ "GenSigSendType" SG_ 587 AirTFromHeatgEstimd 0;
BA_ "GenSigSendType" SG_ 587 BsgDcDcPmpPwmReq 0;
BA_ "GenSigSendType" SG_ 587 BsgDcDcPmpPwrCns 0;
// Frame: EcmChas1Fr26
BA_ "GenMsgSendType" BO_ 543 0;
BA_ "GenMsgCycleTime" BO_ 543 40.000;
BA_ "GenSigSendType" SG_ 543 AcCmprVlvICns 0;
BA_ "GenSigStartValue" SG_ 543 GearMov 2;
BA_ "GenSigSendType" SG_ 543 GearMov 0;
BA_ "GenSigSendType" SG_ 543 TocCooltPmpPwrCns 0;
// Frame: EcmChas1Fr27
BA_ "GenMsgSendType" BO_ 609 0;
BA_ "GenMsgCycleTime" BO_ 609 100.000;
BA_ "GenSigSendType" SG_ 609 EldtFanPwrCns 0;
BA_ "GenSigSendType" SG_ 609 EldtPmpPwrCns 0;
BA_ "GenSigSendType" SG_ 609 EngCooltFlwAct 0;
BA_ "GenSigSendType" SG_ 609 EngCooltPmpPwrCns 0;
// Frame: EcmChas1Fr28
BA_ "GenMsgSendType" BO_ 620 0;
BA_ "GenMsgCycleTime" BO_ 620 100.000;
BA_ "GenSigSendType" SG_ 620 EldtPmpStatCooltPmpDryErr 0;
BA_ "GenSigSendType" SG_ 620 EldtPmpStatCooltPmpEmgyModSts 0;
BA_ "GenSigSendType" SG_ 620 EldtPmpStatCooltPmpErrSts 0;
BA_ "GenSigSendType" SG_ 620 EldtPmpStatCooltPmpI 0;
BA_ "GenSigSendType" SG_ 620 EldtPmpStatCooltPmpIErr 0;
BA_ "GenSigSendType" SG_ 620 EldtPmpStatCooltPmpMonrSpd 0;
BA_ "GenSigSendType" SG_ 620 EldtPmpStatCooltPmpPostRunSts 0;
BA_ "GenSigSendType" SG_ 620 EldtPmpStatCooltPmpSetPostRunReq 0;
BA_ "GenSigSendType" SG_ 620 EldtPmpStatCooltPmpSetSpdReq 0;
BA_ "GenSigSendType" SG_ 620 EldtPmpStatCooltPmpSpd 0;
BA_ "GenSigStartValue" SG_ 620 EldtPmpStatCooltPmpT 100;
BA_ "GenSigSendType" SG_ 620 EldtPmpStatCooltPmpT 0;
BA_ "GenSigSendType" SG_ 620 EldtPmpStatCooltPmpTErr 0;
BA_ "GenSigSendType" SG_ 620 EldtPmpStatCooltPmpU 0;
BA_ "GenSigSendType" SG_ 620 EldtPmpStatCooltPmpUErr 0;
BA_ "GenSigSendType" SG_ 620 EldtPmpStatCooltPmpUnstallSts 0;
// Frame: EcmChas1Fr29
BA_ "GenMsgSendType" BO_ 632 0;
BA_ "GenMsgCycleTime" BO_ 632 100.000;
BA_ "GenSigSendType" SG_ 632 GrlShttrStsShttrActrFlt 0;
BA_ "GenSigSendType" SG_ 632 GrlShttrStsShttrBlkd 0;
BA_ "GenSigSendType" SG_ 632 GrlShttrStsShttrCalActv 0;
BA_ "GenSigSendType" SG_ 632 GrlShttrStsShttrCalIndcd 0;
BA_ "GenSigSendType" SG_ 632 GrlShttrStsShttrElecErr 0;
BA_ "GenSigSendType" SG_ 632 GrlShttrStsShttrPosnRaw 0;
BA_ "GenSigSendType" SG_ 632 GrlShttrStsShttrSnsrFlt 0;
BA_ "GenSigSendType" SG_ 632 GrlShttrStsShttrTErr 0;
BA_ "GenSigSendType" SG_ 632 GrlShttrStsShttrULoErr 0;
// Frame: EcmChas1Fr30
BA_ "GenMsgSendType" BO_ 642 0;
BA_ "GenMsgCycleTime" BO_ 642 100.000;
BA_ "GenSigSendType" SG_ 642 SplrShttrStsShttrActrFlt 0;
BA_ "GenSigSendType" SG_ 642 SplrShttrStsShttrBlkd 0;
BA_ "GenSigSendType" SG_ 642 SplrShttrStsShttrCalActv 0;
BA_ "GenSigSendType" SG_ 642 SplrShttrStsShttrCalIndcd 0;
BA_ "GenSigSendType" SG_ 642 SplrShttrStsShttrElecErr 0;
BA_ "GenSigSendType" SG_ 642 SplrShttrStsShttrPosnRaw 0;
BA_ "GenSigSendType" SG_ 642 SplrShttrStsShttrSnsrFlt 0;
BA_ "GenSigSendType" SG_ 642 SplrShttrStsShttrTErr 0;
BA_ "GenSigSendType" SG_ 642 SplrShttrStsShttrULoErr 0;
// Frame: EcmChas1Fr31
BA_ "GenMsgSendType" BO_ 131 0;
BA_ "GenMsgCycleTime" BO_ 131 10.000;
BA_ "GenSigSendType" SG_ 131 EngSt1WdStsChks 0;
BA_ "GenSigFuncType" SG_ 131 EngSt1WdStsChks 15;
BA_ "GenSigDataID" SG_ 131 EngSt1WdStsChks "0x89";
BA_ "GenSigSendType" SG_ 131 EngSt1WdStsCntr 0;
BA_ "GenSigFuncType" SG_ 131 EngSt1WdStsCntr 16;
BA_ "GenSigSendType" SG_ 131 EngSt1WdStsEngSt1WdSts 0;
BA_ "GenSigSendType" SG_ 131 JOACDampIndex 0;
BA_ "GenSigStartValue" SG_ 131 MvEMSpdReq 10000;
BA_ "GenSigSendType" SG_ 131 MvEMSpdReq 0;
BA_ "GenSigStartValue" SG_ 131 MvEMTqReq 700;
BA_ "GenSigSendType" SG_ 131 MvEMTqReq 0;
// Frame: EcmChas1Fr37
BA_ "GenMsgSendType" BO_ 752 0;
BA_ "GenMsgCycleTime" BO_ 752 80.000;
BA_ "GenSigSendType" SG_ 752 EngSt1WdSts1 0;
// Frame: EcmChas1NMFr
BA_ "GenMsgSendType" BO_ 1296 1;
BA_ "GenMsgDelayTime" BO_ 1296 20.000;
BA_ "GenMsgILSupport" BO_ 1296 0;
BA_ "NmAsrMessage" BO_ 1296 1;
// Frame: EtcToMvemXcpFr01
BA_ "GenMsgSendType" BO_ 1429 1;
BA_ "GenMsgDelayTime" BO_ 1429 5.000;
// Frame: EtcToMvemXcpFr02
BA_ "GenMsgSendType" BO_ 1424 1;
BA_ "GenMsgDelayTime" BO_ 1424 5.000;
// Frame: EtcToMvemXcpFr03
BA_ "GenMsgSendType" BO_ 1425 1;
BA_ "GenMsgDelayTime" BO_ 1425 5.000;
// Frame: EtcToPscm1cChas1XcpFr01
BA_ "GenMsgSendType" BO_ 1441 1;
BA_ "GenMsgDelayTime" BO_ 1441 5.000;
// Frame: EtcToPscmChas1XcpFr01
BA_ "GenMsgSendType" BO_ 1409 1;
BA_ "GenMsgDelayTime" BO_ 1409 5.000;
// Frame: EtcToPscmChas1XcpFr02
BA_ "GenMsgSendType" BO_ 1416 1;
BA_ "GenMsgDelayTime" BO_ 1416 5.000;
// Frame: EtcToPscmChas1XcpFr03
BA_ "GenMsgSendType" BO_ 1418 1;
BA_ "GenMsgDelayTime" BO_ 1418 5.000;
// Frame: EtcToPscmChas1XcpFr04
BA_ "GenMsgSendType" BO_ 1420 1;
BA_ "GenMsgDelayTime" BO_ 1420 5.000;
// Frame: EtcToPscmDevelFr
BA_ "GenMsgSendType" BO_ 1431 1;
BA_ "GenMsgDelayTime" BO_ 1431 95.000;
BA_ "GenSigSendType" SG_ 1431 PSCMdevelpsignalgroupreq1Functiondevpsignalgroup1 1;
BA_ "GenSigSendType" SG_ 1431 PSCMdevelpsignalgroupreq1Functiondevpsignalgroup2 1;
BA_ "GenSigSendType" SG_ 1431 PSCMdevelpsignalgroupreq1Functiondevpsignalgroup3 1;
BA_ "GenSigSendType" SG_ 1431 PSCMdevelpsignalgroupreq1Functiondevpsignalgroup4 1;
BA_ "GenSigSendType" SG_ 1431 PSCMdevelpsignalgroupreq1Functiondevpsignalgroup5 1;
BA_ "GenSigSendType" SG_ 1431 PSCMdevelpsignalgroupreq1Functiondevpsignalgroup6 1;
BA_ "GenSigSendType" SG_ 1431 PSCMdevelpsignalgroupreq1Functiondevpsignalgroup7 1;
BA_ "GenSigSendType" SG_ 1431 PSCMdevelpsignalgroupreq1Functiondevpsignalgroup8 1;
// Frame: EtcToRasmChas1XcpFr01
BA_ "GenMsgSendType" BO_ 1442 1;
BA_ "GenMsgDelayTime" BO_ 1442 5.000;
// Frame: EtcToTcmXcpFr01
BA_ "GenMsgSendType" BO_ 1414 1;
BA_ "GenMsgDelayTime" BO_ 1414 10.000;
// Frame: EtcToTcmXcpFr02
BA_ "GenMsgSendType" BO_ 1411 1;
BA_ "GenMsgDelayTime" BO_ 1411 10.000;
// Frame: EtctoVddmBcmXCPFr01
BA_ "GenMsgSendType" BO_ 1421 1;
BA_ "GenMsgDelayTime" BO_ 1421 10.000;
// Frame: EtctoVddmDevelFr01
BA_ "GenMsgSendType" BO_ 1432 1;
BA_ "GenMsgDelayTime" BO_ 1432 95.000;
BA_ "GenSigSendType" SG_ 1432 VDDMdevelpsignalgroupreq1Functiondevpsignalgroup1 1;
BA_ "GenSigSendType" SG_ 1432 VDDMdevelpsignalgroupreq1Functiondevpsignalgroup2 1;
BA_ "GenSigSendType" SG_ 1432 VDDMdevelpsignalgroupreq1Functiondevpsignalgroup3 1;
BA_ "GenSigSendType" SG_ 1432 VDDMdevelpsignalgroupreq1Functiondevpsignalgroup4 1;
BA_ "GenSigSendType" SG_ 1432 VDDMdevelpsignalgroupreq1Functiondevpsignalgroup5 1;
BA_ "GenSigSendType" SG_ 1432 VDDMdevelpsignalgroupreq1Functiondevpsignalgroup6 1;
BA_ "GenSigSendType" SG_ 1432 VDDMdevelpsignalgroupreq1Functiondevpsignalgroup7 1;
BA_ "GenSigSendType" SG_ 1432 VDDMdevelpsignalgroupreq1Functiondevpsignalgroup8 1;
// Frame: EtctoVddmDevelFr02
BA_ "GenMsgSendType" BO_ 1433 1;
BA_ "GenMsgDelayTime" BO_ 1433 95.000;
BA_ "GenSigSendType" SG_ 1433 VDDMdevelpsignalgroupreq2Functiondevpsignalgroup1 1;
BA_ "GenSigSendType" SG_ 1433 VDDMdevelpsignalgroupreq2Functiondevpsignalgroup2 1;
BA_ "GenSigSendType" SG_ 1433 VDDMdevelpsignalgroupreq2Functiondevpsignalgroup3 1;
BA_ "GenSigSendType" SG_ 1433 VDDMdevelpsignalgroupreq2Functiondevpsignalgroup4 1;
BA_ "GenSigSendType" SG_ 1433 VDDMdevelpsignalgroupreq2Functiondevpsignalgroup5 1;
BA_ "GenSigSendType" SG_ 1433 VDDMdevelpsignalgroupreq2Functiondevpsignalgroup6 1;
BA_ "GenSigSendType" SG_ 1433 VDDMdevelpsignalgroupreq2Functiondevpsignalgroup7 1;
BA_ "GenSigSendType" SG_ 1433 VDDMdevelpsignalgroupreq2Functiondevpsignalgroup8 1;
// Frame: MvemChas1Fr01
BA_ "GenMsgSendType" BO_ 213 0;
BA_ "GenMsgCycleTime" BO_ 213 10.000;
BA_ "GenSigStartValue" SG_ 213 MvEMIDc 500;
BA_ "GenSigSendType" SG_ 213 MvEMIDc 0;
BA_ "GenSigStartValue" SG_ 213 MvEMModSts 1;
BA_ "GenSigSendType" SG_ 213 MvEMModSts 0;
BA_ "GenSigStartValue" SG_ 213 MvEMTqActSafe1MvIsgTq 700;
BA_ "GenSigSendType" SG_ 213 MvEMTqActSafe1MvIsgTq 0;
BA_ "GenSigSendType" SG_ 213 MvEMTqActSafe1MvIsgTqChks 0;
BA_ "GenSigFuncType" SG_ 213 MvEMTqActSafe1MvIsgTqChks 15;
BA_ "GenSigDataID" SG_ 213 MvEMTqActSafe1MvIsgTqChks "0x53";
BA_ "GenSigSendType" SG_ 213 MvEMTqActSafe1MvIsgTqCntr 0;
BA_ "GenSigFuncType" SG_ 213 MvEMTqActSafe1MvIsgTqCntr 16;
BA_ "GenSigStartValue" SG_ 213 MvEMTqActSafe1QualityFactor 3;
BA_ "GenSigSendType" SG_ 213 MvEMTqActSafe1QualityFactor 0;
BA_ "GenSigSendType" SG_ 213 MvEMUDc 0;
// Frame: MvemChas1Fr02
BA_ "GenMsgSendType" BO_ 225 0;
BA_ "GenMsgCycleTime" BO_ 225 20.000;
BA_ "GenSigSendType" SG_ 225 MvEMLimnIndcn 0;
BA_ "GenSigStartValue" SG_ 225 MvEMSpdActSgn 10000;
BA_ "GenSigSendType" SG_ 225 MvEMSpdActSgn 0;
BA_ "GenSigSendType" SG_ 225 MvEMTqAvlMax 0;
BA_ "GenSigStartValue" SG_ 225 MvEMTqAvlMin 140;
BA_ "GenSigSendType" SG_ 225 MvEMTqAvlMin 0;
// Frame: MvemChas1Fr03
BA_ "GenMsgSendType" BO_ 499 0;
BA_ "GenMsgCycleTime" BO_ 499 200.000;
BA_ "GenSigSendType" SG_ 499 MvEMFltSts 0;
BA_ "GenSigSendType" SG_ 499 MvEMTRate 0;
// Frame: MvemChas1Fr04
BA_ "GenMsgSendType" BO_ 529 0;
BA_ "GenMsgCycleTime" BO_ 529 80.000;
BA_ "GenSigSendType" SG_ 529 ImobEngChk3v2ImobEngChkSts 0;
BA_ "GenSigSendType" SG_ 529 ImobEngChk3v2ImobEngDataChk0 0;
BA_ "GenSigSendType" SG_ 529 ImobEngChk3v2ImobEngDataChk1 0;
BA_ "GenSigSendType" SG_ 529 ImobEngChk3v2ImobEngDataChk2 0;
BA_ "GenSigSendType" SG_ 529 ImobEngChk3v2ImobEngDataChk3 0;
BA_ "GenSigSendType" SG_ 529 ImobEngChk3v2ImobEngDataChk4 0;
BA_ "GenSigSendType" SG_ 529 ImobEngChk3v2ImobEngDataChk5 0;
BA_ "GenSigSendType" SG_ 529 ImobEngChk3v2ImobEngDataChk6 0;
BA_ "GenSigSendType" SG_ 529 ImobEngSts3v2 0;
// Frame: MvemChas1NMFr
BA_ "GenMsgSendType" BO_ 1330 1;
BA_ "GenMsgDelayTime" BO_ 1330 20.000;
BA_ "GenMsgILSupport" BO_ 1330 0;
BA_ "NmAsrMessage" BO_ 1330 1;
// Frame: MvemToEtcXcpFr01
BA_ "GenMsgSendType" BO_ 1426 1;
BA_ "GenMsgDelayTime" BO_ 1426 5.000;
// Frame: MvemToEtcXcpFr02
BA_ "GenMsgSendType" BO_ 1427 1;
BA_ "GenMsgDelayTime" BO_ 1427 5.000;
// Frame: MvemToEtcXcpFr03
BA_ "GenMsgSendType" BO_ 1428 1;
BA_ "GenMsgDelayTime" BO_ 1428 5.000;
// Frame: PasChas1Fr02
BA_ "GenMsgSendType" BO_ 235 0;
BA_ "GenMsgCycleTime" BO_ 235 15.000;
BA_ "GenSigStartValue" SG_ 235 PrkgPinionAgReqGroupParkAssiPinionAgReq 14847.992;
BA_ "GenSigSendType" SG_ 235 PrkgPinionAgReqGroupParkAssiPinionAgReq 0;
BA_ "GenSigSendType" SG_ 235 PrkgPinionAgReqGroupParkAssiPinionAgReqChks 0;
BA_ "GenSigFuncType" SG_ 235 PrkgPinionAgReqGroupParkAssiPinionAgReqChks 15;
BA_ "GenSigDataID" SG_ 235 PrkgPinionAgReqGroupParkAssiPinionAgReqChks "0x1B1";
BA_ "GenSigSendType" SG_ 235 PrkgPinionAgReqGroupParkAssiPinionAgReqCntr 0;
BA_ "GenSigFuncType" SG_ 235 PrkgPinionAgReqGroupParkAssiPinionAgReqCntr 16;
BA_ "GenSigStartValue" SG_ 235 PrkgPinionAgReqGroupQF 1;
BA_ "GenSigSendType" SG_ 235 PrkgPinionAgReqGroupQF 0;
// Frame: PasChas1NMFr
BA_ "GenMsgSendType" BO_ 1320 1;
BA_ "GenMsgDelayTime" BO_ 1320 20.000;
BA_ "GenMsgILSupport" BO_ 1320 0;
BA_ "NmAsrMessage" BO_ 1320 1;
// Frame: PscmChas1Fr01
BA_ "GenMsgSendType" BO_ 246 0;
BA_ "GenMsgCycleTime" BO_ 246 10.000;
BA_ "GenSigSendType" SG_ 246 ADL3LatCtrlStsADMod 0;
BA_ "GenSigSendType" SG_ 246 ADL3LatCtrlStsChks 0;
BA_ "GenSigFuncType" SG_ 246 ADL3LatCtrlStsChks 15;
BA_ "GenSigDataID" SG_ 246 ADL3LatCtrlStsChks "0x463";
BA_ "GenSigSendType" SG_ 246 ADL3LatCtrlStsCntr 0;
BA_ "GenSigFuncType" SG_ 246 ADL3LatCtrlStsCntr 16;
BA_ "GenSigSendType" SG_ 246 ADL3LatCtrlStsCtrlSts 0;
BA_ "GenSigSendType" SG_ 246 ADL3LatCtrlStsDegraded 0;
BA_ "GenSigSendType" SG_ 246 ADL3LatCtrlStsQf 0;
BA_ "GenSigSendType" SG_ 246 ADL3LatCtrlStsSts 0;
BA_ "GenSigSendType" SG_ 246 DrvrSteerActvChks 0;
BA_ "GenSigFuncType" SG_ 246 DrvrSteerActvChks 15;
BA_ "GenSigDataID" SG_ 246 DrvrSteerActvChks "0xBC";
BA_ "GenSigSendType" SG_ 246 DrvrSteerActvCntr 0;
BA_ "GenSigFuncType" SG_ 246 DrvrSteerActvCntr 16;
BA_ "GenSigSendType" SG_ 246 DrvrSteerActvDrvrSteerActv 0;
BA_ "GenSigSendType" SG_ 246 FrntSteerFEstimd1 0;
BA_ "GenSigSendType" SG_ 246 UBoostReqBySteerFrnt 0;
// Frame: PscmChas1Fr02
BA_ "GenMsgSendType" BO_ 70 0;
BA_ "GenMsgCycleTime" BO_ 70 15.000;
BA_ "GenSigSendType" SG_ 70 LatCtrlModCfmdChks 0;
BA_ "GenSigFuncType" SG_ 70 LatCtrlModCfmdChks 15;
BA_ "GenSigDataID" SG_ 70 LatCtrlModCfmdChks "0x3A";
BA_ "GenSigSendType" SG_ 70 LatCtrlModCfmdCntr 0;
BA_ "GenSigFuncType" SG_ 70 LatCtrlModCfmdCntr 16;
BA_ "GenSigSendType" SG_ 70 LatCtrlModCfmdLatCtrlMod 0;
BA_ "GenSigSendType" SG_ 70 SteerServoSts 0;
BA_ "GenSigSendType" SG_ 70 SteerWhlTqAddl 0;
BA_ "GenSigSendType" SG_ 70 TqAssAddl 0;
// Frame: PscmChas1Fr03
BA_ "GenMsgSendType" BO_ 444 0;
BA_ "GenMsgCycleTime" BO_ 444 25.000;
BA_ "GenSigSendType" SG_ 444 DrvrSteerWhlHldGroupDrvrSteerWhlHld 0;
BA_ "GenSigSendType" SG_ 444 DrvrSteerWhlHldGroupDrvrSteerWhlHldQly 0;
BA_ "GenSigStartValue" SG_ 444 SteerErrReq 1;
BA_ "GenSigSendType" SG_ 444 SteerErrReq 0;
BA_ "GenSigSendType" SG_ 444 SteerExtFctStsChks 0;
BA_ "GenSigSendType" SG_ 444 SteerExtFctStsCntr 0;
BA_ "GenSigSendType" SG_ 444 SteerExtFctStsDrvrSteerOvrd 0;
BA_ "GenSigSendType" SG_ 444 SteerExtFctStsExtFctLowerLimActive 0;
BA_ "GenSigSendType" SG_ 444 SteerExtFctStsExtFctRateLimActive 0;
BA_ "GenSigSendType" SG_ 444 SteerExtFctStsExtFctUpperLimActive 0;
BA_ "GenSigSendType" SG_ 444 SteerExtFctStsExtSafeLimActive 0;
BA_ "GenSigSendType" SG_ 444 SteerExtFctStsLatAgReqNotInRange 0;
BA_ "GenSigSendType" SG_ 444 SteerExtFctStsLatCtrlReqNotInRange 0;
BA_ "GenSigSendType" SG_ 444 SteerStsToParkAssi 0;
// Frame: PscmChas1Fr06
BA_ "GenMsgSendType" BO_ 955 0;
BA_ "GenMsgCycleTime" BO_ 955 400.000;
BA_ "GenSigSendType" SG_ 955 PinionSteerAgMax1 0;
// Frame: PscmChas1Fr07
BA_ "GenMsgSendType" BO_ 78 0;
BA_ "GenMsgCycleTime" BO_ 78 10.000;
BA_ "GenSigSendType" SG_ 78 PinionSteerAgGroupChks 0;
BA_ "GenSigFuncType" SG_ 78 PinionSteerAgGroupChks 15;
BA_ "GenSigDataID" SG_ 78 PinionSteerAgGroupChks "0x40D";
BA_ "GenSigSendType" SG_ 78 PinionSteerAgGroupCntr 0;
BA_ "GenSigFuncType" SG_ 78 PinionSteerAgGroupCntr 16;
BA_ "GenSigSendType" SG_ 78 PinionSteerAgGroupPinionSteerAg1 0;
BA_ "GenSigStartValue" SG_ 78 PinionSteerAgGroupPinionSteerAg1Qf 1;
BA_ "GenSigSendType" SG_ 78 PinionSteerAgGroupPinionSteerAg1Qf 0;
BA_ "GenSigSendType" SG_ 78 PinionSteerAgGroupPinionSteerAgSpd1 0;
BA_ "GenSigStartValue" SG_ 78 PinionSteerAgGroupPinionSteerAgSpd1Qf 1;
BA_ "GenSigSendType" SG_ 78 PinionSteerAgGroupPinionSteerAgSpd1Qf 0;
BA_ "GenSigSendType" SG_ 78 PinionSteerAgGroupSteerWhlTq 0;
BA_ "GenSigStartValue" SG_ 78 PinionSteerAgGroupSteerWhlTqQf 1;
BA_ "GenSigSendType" SG_ 78 PinionSteerAgGroupSteerWhlTqQf 0;
// Frame: PscmChas1NMFr
BA_ "GenMsgSendType" BO_ 1315 1;
BA_ "GenMsgDelayTime" BO_ 1315 20.000;
BA_ "GenMsgILSupport" BO_ 1315 0;
BA_ "NmAsrMessage" BO_ 1315 1;
// Frame: PscmDevelpFr
BA_ "GenMsgSendType" BO_ 1430 1;
BA_ "GenMsgDelayTime" BO_ 1430 95.000;
BA_ "GenSigSendType" SG_ 1430 PSCMdevelpsignalgroupresp1Functiondevpsignalgroup1 1;
BA_ "GenSigSendType" SG_ 1430 PSCMdevelpsignalgroupresp1Functiondevpsignalgroup2 1;
BA_ "GenSigSendType" SG_ 1430 PSCMdevelpsignalgroupresp1Functiondevpsignalgroup3 1;
BA_ "GenSigSendType" SG_ 1430 PSCMdevelpsignalgroupresp1Functiondevpsignalgroup4 1;
BA_ "GenSigSendType" SG_ 1430 PSCMdevelpsignalgroupresp1Functiondevpsignalgroup5 1;
BA_ "GenSigSendType" SG_ 1430 PSCMdevelpsignalgroupresp1Functiondevpsignalgroup6 1;
BA_ "GenSigSendType" SG_ 1430 PSCMdevelpsignalgroupresp1Functiondevpsignalgroup7 1;
BA_ "GenSigSendType" SG_ 1430 PSCMdevelpsignalgroupresp1Functiondevpsignalgroup8 1;
// Frame: PscmToEtcChas1XcpFr01
BA_ "GenMsgSendType" BO_ 1410 1;
BA_ "GenMsgDelayTime" BO_ 1410 5.000;
// Frame: PscmToEtcChas1XcpFr02
BA_ "GenMsgSendType" BO_ 1417 1;
BA_ "GenMsgDelayTime" BO_ 1417 5.000;
// Frame: PscmToEtcChas1XcpFr03
BA_ "GenMsgSendType" BO_ 1419 1;
BA_ "GenMsgDelayTime" BO_ 1419 5.000;
// Frame: PscmToEtcChas1XcpFr04
BA_ "GenMsgSendType" BO_ 1415 1;
BA_ "GenMsgDelayTime" BO_ 1415 5.000;
// Frame: PscmToEtcChas1XcpFr05
BA_ "GenMsgSendType" BO_ 1412 1;
BA_ "GenMsgDelayTime" BO_ 1412 5.000;
// Frame: PscmToEtcChas1XcpFr06
BA_ "GenMsgSendType" BO_ 1423 1;
BA_ "GenMsgDelayTime" BO_ 1423 5.000;
// Frame: PscmToVddmChas1DiagResFrame
BA_ "GenMsgSendType" BO_ 1648 1;
BA_ "GenMsgDelayTime" BO_ 1648 5.000;
// Frame: SasChas1Fr01
BA_ "GenMsgSendType" BO_ 64 0;
BA_ "GenMsgCycleTime" BO_ 64 10.000;
BA_ "GenSigSendType" SG_ 64 SteerWhlSnsrAg 0;
BA_ "GenSigSendType" SG_ 64 SteerWhlSnsrAgSpd 0;
BA_ "GenSigSendType" SG_ 64 SteerWhlSnsrChks 0;
BA_ "GenSigFuncType" SG_ 64 SteerWhlSnsrChks 15;
BA_ "GenSigDataID" SG_ 64 SteerWhlSnsrChks "0x33";
BA_ "GenSigSendType" SG_ 64 SteerWhlSnsrCntr 0;
BA_ "GenSigFuncType" SG_ 64 SteerWhlSnsrCntr 16;
BA_ "GenSigStartValue" SG_ 64 SteerWhlSnsrQf 1;
BA_ "GenSigSendType" SG_ 64 SteerWhlSnsrQf 0;
// Frame: SasChas1NMFr
BA_ "GenMsgSendType" BO_ 1319 1;
BA_ "GenMsgDelayTime" BO_ 1319 20.000;
BA_ "GenMsgILSupport" BO_ 1319 0;
BA_ "NmAsrMessage" BO_ 1319 1;
// Frame: SasToVddmChas1DiagResFrame
BA_ "GenMsgSendType" BO_ 1650 1;
BA_ "GenMsgDelayTime" BO_ 1650 5.000;
// Frame: TcmChas1Fr01
BA_ "GenMsgSendType" BO_ 42 0;
BA_ "GenMsgCycleTime" BO_ 42 10.000;
BA_ "GenSigSendType" SG_ 42 TrsmCluSlipPwrIntgl1Idx 0;
BA_ "GenSigSendType" SG_ 42 TrsmCluSlipPwrIntgl1Qf 0;
BA_ "GenSigSendType" SG_ 42 TrsmCluSlipPwrIntgl2Idx 0;
BA_ "GenSigSendType" SG_ 42 TrsmCluSlipPwrIntgl2Qf 0;
BA_ "GenSigSendType" SG_ 42 TrsmCluTqCp1 0;
BA_ "GenSigSendType" SG_ 42 TrsmCluTqCp2 0;
BA_ "GenSigSendType" SG_ 42 TrsmGearAct1 0;
BA_ "GenSigSendType" SG_ 42 TrsmGearAct2 0;
BA_ "GenSigStartValue" SG_ 42 TrsmGearEngmtSts1 2;
BA_ "GenSigSendType" SG_ 42 TrsmGearEngmtSts1 0;
BA_ "GenSigStartValue" SG_ 42 TrsmGearEngmtSts2 2;
BA_ "GenSigSendType" SG_ 42 TrsmGearEngmtSts2 0;
BA_ "GenSigSendType" SG_ 42 TrsmReqForPfmncRedn3 0;
// Frame: TcmChas1Fr02
BA_ "GenMsgSendType" BO_ 48 0;
BA_ "GenMsgCycleTime" BO_ 48 10.000;
BA_ "GenSigSendType" SG_ 48 TrsmNRecChks 0;
BA_ "GenSigFuncType" SG_ 48 TrsmNRecChks 15;
BA_ "GenSigDataID" SG_ 48 TrsmNRecChks "0xA9";
BA_ "GenSigSendType" SG_ 48 TrsmNRecCntr 0;
BA_ "GenSigFuncType" SG_ 48 TrsmNRecCntr 16;
BA_ "GenSigSendType" SG_ 48 TrsmNRecInp1 0;
BA_ "GenSigSendType" SG_ 48 TrsmNRecInp2 0;
BA_ "GenSigSendType" SG_ 48 TrsmNRecInpDir1 0;
BA_ "GenSigSendType" SG_ 48 TrsmNRecInpDir2 0;
BA_ "GenSigSendType" SG_ 48 TrsmNRecInpQf1 0;
BA_ "GenSigSendType" SG_ 48 TrsmNRecInpQf2 0;
BA_ "GenSigSendType" SG_ 48 TrsmNRecOutp 0;
BA_ "GenSigSendType" SG_ 48 TrsmNRecOutpDir 0;
BA_ "GenSigSendType" SG_ 48 TrsmNRecOutpQf 0;
// Frame: TcmChas1Fr03
BA_ "GenMsgSendType" BO_ 53 0;
BA_ "GenMsgCycleTime" BO_ 53 10.000;
BA_ "GenSigSendType" SG_ 53 TrsmCluSlipCtrlModSts 0;
BA_ "GenSigSendType" SG_ 53 TrsmCluT1Qf 0;
BA_ "GenSigStartValue" SG_ 53 TrsmCluT1Val 32;
BA_ "GenSigSendType" SG_ 53 TrsmCluT1Val 0;
BA_ "GenSigSendType" SG_ 53 TrsmCluT2Qf 0;
BA_ "GenSigStartValue" SG_ 53 TrsmCluT2Val 32;
BA_ "GenSigSendType" SG_ 53 TrsmCluT2Val 0;
BA_ "GenSigSendType" SG_ 53 TrsmCluTqCpMaxInProgs1 0;
BA_ "GenSigSendType" SG_ 53 TrsmCluTqCpMaxInProgs2 0;
BA_ "GenSigSendType" SG_ 53 TrsmCluTqCpMaxPrio1 0;
BA_ "GenSigSendType" SG_ 53 TrsmCluTqCpMaxPrio2 0;
BA_ "GenSigSendType" SG_ 53 TrsmCluTqCpMinInProgs1 0;
BA_ "GenSigSendType" SG_ 53 TrsmCluTqCpMinInProgs2 0;
BA_ "GenSigSendType" SG_ 53 TrsmGearActrScanForRefActv 0;
BA_ "GenSigSendType" SG_ 53 TrsmGearActrScanForRefReq 0;
BA_ "GenSigSendType" SG_ 53 TrsmOilFlow 0;
BA_ "GenSigSendType" SG_ 53 TrsmOperSts 0;
BA_ "GenSigSendType" SG_ 53 TrsmSlipCtrlReq 0;
BA_ "GenSigSendType" SG_ 53 TrsmSoftRotReq1 0;
BA_ "GenSigSendType" SG_ 53 TrsmSoftRotReq2 0;
// Frame: TcmChas1Fr04
BA_ "GenMsgSendType" BO_ 117 0;
BA_ "GenMsgCycleTime" BO_ 117 30.000;
BA_ "GenSigSendType" SG_ 117 TrsmCluActrLimd1 0;
BA_ "GenSigSendType" SG_ 117 TrsmCluActrLimd2 0;
BA_ "GenSigSendType" SG_ 117 TrsmCluActrOff1 0;
BA_ "GenSigSendType" SG_ 117 TrsmCluActrOff2 0;
BA_ "GenSigSendType" SG_ 117 TrsmCluActrTLvl1 0;
BA_ "GenSigSendType" SG_ 117 TrsmCluActrTLvl2 0;
BA_ "GenSigSendType" SG_ 117 TrsmCluTqCpCorrln1 0;
BA_ "GenSigSendType" SG_ 117 TrsmCluTqCpCorrln2 0;
BA_ "GenSigSendType" SG_ 117 TrsmCluTqCpMax1 0;
BA_ "GenSigSendType" SG_ 117 TrsmCluTqCpMax2 0;
BA_ "GenSigSendType" SG_ 117 TrsmCluTqCpMinPrio1 0;
BA_ "GenSigSendType" SG_ 117 TrsmCluTqCpMinPrio2 0;
BA_ "GenSigSendType" SG_ 117 TrsmEndOfLineModActv 0;
BA_ "GenSigSendType" SG_ 117 TrsmGbxActrOff 0;
BA_ "GenSigSendType" SG_ 117 TrsmGearActrSts 0;
BA_ "GenSigSendType" SG_ 117 TrsmGearActrTLvl 0;
BA_ "GenSigSendType" SG_ 117 TrsmHardRotReq1 0;
BA_ "GenSigSendType" SG_ 117 TrsmHardRotReq2 0;
BA_ "GenSigSendType" SG_ 117 TrsmOilPmpTLvl 0;

VAL_ 147 AsyADL3FuncCtrlStsADMod 0 "ADMod_NAD_Mod" 1 "ADMod_TJP" 2 "ADMod_SHWA" 3 "ADMod_Reserved";
VAL_ 147 AsyADL3FuncCtrlStsCtrlSts 0 "Primary" 1 "Secondary";
VAL_ 147 AsyADL3FuncCtrlStsQf 0 "GenQf1_UndefindDataAccur" 1 "GenQf1_TmpUndefdData" 2 "GenQf1_DataAccurNotWithinSpcn" 3 "GenQf1_AccurData";
VAL_ 147 AsyADL3FuncCtrlStsSts 0 "ColorSts_Red" 1 "ColorSts_Yellow" 2 "ColorSts_Green" 3 "ColorSts_Reserved";
VAL_ 147 AsyADModeReqADActiveReq 0 "ADMod_NAD_Mod" 1 "ADMod_TJP" 2 "ADMod_SHWA" 3 "ADMod_Reserved";
VAL_ 147 AsyADModeReqADDeactiveReq 0 "ReqSts1_NotReqd" 1 "ReqSts1_Reqd";
VAL_ 147 PASFuncActive 0 "OnOff1_Off" 1 "OnOff1_On";
VAL_ 147 RctaBrkReqQM 0 "OnOff1_Off" 1 "OnOff1_On";
VAL_ 147 RcwmBrkReqQM 0 "OnOff1_Off" 1 "OnOff1_On";
VAL_ 564 MonrCycCmpl 0 "NotCmpl1_NotCmpl" 1 "NotCmpl1_Cmpl";
VAL_ 564 PrpsnSysActv 0 "NotCmpl1_NotCmpl" 1 "NotCmpl1_Cmpl";
VAL_ 226 MvEMModReqMvEMModReq 0 "MvEMModReq_Openbridge" 1 "MvEMModReq_StdBy" 2 "MvEMModReq_TqCtl" 3 "MvEMModReq_SpdCtl" 4 "MvEMModReq_UDcCtl" 5 "MvEMModReq_GenNoBatCtl" 6 "MvEMModReq_ZeroTqCtrl" 7 "MvEMModReq_Reserved5" 8 "MvEMModReq_Reserved6" 9 "MvEMModReq_Reserved7" 10 "MvEMModReq_Reserved8" 11 "MvEMModReq_Reserved9" 12 "MvEMModReq_Reserved10" 13 "MvEMModReq_Reserved11" 14 "MvEMModReq_Reserved12" 15 "MvEMModReq_Reserved13";
VAL_ 134 AntiJerkSelect 0 "JerkSelect_NoOrderFilter" 1 "JerkSelect_FirstOrderFilter" 2 "JerkSelect_SecondOrderFilter";
VAL_ 134 DrvgCyc 0 "OnOff1_Off" 1 "OnOff1_On";
VAL_ 134 JOACEnbReq 0 "EnableDisableCoding_Disabled" 1 "EnableDisableCoding_Enabled";
VAL_ 134 JOACFreqIndex 1 "FreqIndex_5Hz" 2 "FreqIndex_6_34Hz" 3 "FreqIndex_7_2Hz" 4 "FreqIndex_8_3Hz" 5 "FreqIndex_9_73Hz" 6 "FreqIndex_10_5Hz" 7 "FreqIndex_11_8Hz" 8 "FreqIndex_13Hz";
VAL_ 544 DenoOfDiagcRateGen 0 "Boolean_FALSE" 1 "Boolean_TRUE";
VAL_ 544 DrvgCycToClrPrmntDtc 0 "Boolean_FALSE" 1 "Boolean_TRUE";
VAL_ 544 EngTQf 0 "Qf1_DevOfDataUndefd" 1 "Qf1_DataTmpUndefdAndEvlnInProgs" 2 "Qf1_DevOfDataNotWithinRngAllwd" 3 "Qf1_DataCalcdWithDevDefd";
VAL_ 544 IuprDenominatorInhb 0 "InhibitSts_NotInhibited" 1 "InhibitSts_Inhibited";
VAL_ 32 PtCluSlipCtrlModReq 0 "PtCluSlipCtrlModReq_NotAllwd" 1 "PtCluSlipCtrlModReq_AdpvAllwd" 2 "PtCluSlipCtrlModReq_AdpvAllwd2" 3 "PtCluSlipCtrlModReq_AdpvAllwd3";
VAL_ 32 PtCluSlipCtrlReq 0 "PtCluSlipCtrlReq_Clu1" 1 "PtCluSlipCtrlReq_Clu2";
VAL_ 32 PtEngTqDstbcActv 0 "Boolean_FALSE" 1 "Boolean_TRUE";
VAL_ 32 PtEngTqModlnSts 0 "PtEngTqModlnSts_InActv" 1 "PtEngTqModlnSts_Actv" 2 "PtEngTqModlnSts_ActvNoSlip" 3 "PtEngTqModlnSts_Resd";
VAL_ 32 PtGearActtnReq3 0 "TrsmGear_Neut" 1 "TrsmGear_Gear1" 2 "TrsmGear_Gear2" 3 "TrsmGear_Gear3" 4 "TrsmGear_Gear4" 5 "TrsmGear_Gear5" 6 "TrsmGear_Gear6" 7 "TrsmGear_Gear7" 8 "TrsmGear_Gear8" 9 "TrsmGear_Gear9" 10 "TrsmGear_Gear10" 11 "TrsmGear_Gear11" 12 "TrsmGear_Gear12" 13 "TrsmGear_Gear13" 14 "TrsmGear_Rvs" 15 "TrsmGear_Park";
VAL_ 32 PtRotReqAckd1 0 "Boolean_FALSE" 1 "Boolean_TRUE";
VAL_ 32 PtRotReqAckd2 0 "Boolean_FALSE" 1 "Boolean_TRUE";
VAL_ 37 PtCluTqCpMaxCmd1 0 "Boolean_FALSE" 1 "Boolean_TRUE";
VAL_ 37 PtCluTqCpMaxCmd2 0 "Boolean_FALSE" 1 "Boolean_TRUE";
VAL_ 37 PtCluTqCpMinCmd1 0 "Boolean_FALSE" 1 "Boolean_TRUE";
VAL_ 37 PtCluTqCpMinCmd2 0 "Boolean_FALSE" 1 "Boolean_TRUE";
VAL_ 37 PtDirAllwdToTrsmActrFwd 0 "Flg1_Rst" 1 "Flg1_Set";
VAL_ 37 PtDirAllwdToTrsmActrNeut 0 "Flg1_Rst" 1 "Flg1_Set";
VAL_ 37 PtDirAllwdToTrsmActrParkRls 0 "Flg1_Rst" 1 "Flg1_Set";
VAL_ 37 PtDirAllwdToTrsmActrRvs 0 "Flg1_Rst" 1 "Flg1_Set";
VAL_ 37 PtGearActrAdpnCmd 0 "Boolean_FALSE" 1 "Boolean_TRUE";
VAL_ 37 PtGearActtnAllwdSts1 0 "PtGearActtnAllwdSts_DtInUse" 1 "PtGearActtnAllwdSts_DtSafeToDisengmt" 2 "PtGearActtnAllwdSts_DtSafeToSync" 3 "PtGearActtnAllwdSts_Resd";
VAL_ 37 PtGearActtnAllwdSts2 0 "PtGearActtnAllwdSts_DtInUse" 1 "PtGearActtnAllwdSts_DtSafeToDisengmt" 2 "PtGearActtnAllwdSts_DtSafeToSync" 3 "PtGearActtnAllwdSts_Resd";
VAL_ 37 PtGearActtnModReq 0 "PtGearActtnModReq_Mod0" 1 "PtGearActtnModReq_Mod1" 2 "PtGearActtnModReq_Mod2" 3 "PtGearActtnModReq_Mod3";
VAL_ 37 PtGearActtnPrio 0 "PtGearActtnPrio_Shaft1" 1 "PtGearActtnPrio_Shaft2";
VAL_ 37 PtGearActtnReq1 0 "TrsmGear_Neut" 1 "TrsmGear_Gear1" 2 "TrsmGear_Gear2" 3 "TrsmGear_Gear3" 4 "TrsmGear_Gear4" 5 "TrsmGear_Gear5" 6 "TrsmGear_Gear6" 7 "TrsmGear_Gear7" 8 "TrsmGear_Gear8" 9 "TrsmGear_Gear9" 10 "TrsmGear_Gear10" 11 "TrsmGear_Gear11" 12 "TrsmGear_Gear12" 13 "TrsmGear_Gear13" 14 "TrsmGear_Rvs" 15 "TrsmGear_Park";
VAL_ 37 PtGearActtnReq2 0 "TrsmGear_Neut" 1 "TrsmGear_Gear1" 2 "TrsmGear_Gear2" 3 "TrsmGear_Gear3" 4 "TrsmGear_Gear4" 5 "TrsmGear_Gear5" 6 "TrsmGear_Gear6" 7 "TrsmGear_Gear7" 8 "TrsmGear_Gear8" 9 "TrsmGear_Gear9" 10 "TrsmGear_Gear10" 11 "TrsmGear_Gear11" 12 "TrsmGear_Gear12" 13 "TrsmGear_Gear13" 14 "TrsmGear_Rvs" 15 "TrsmGear_Park";
VAL_ 697 EngPmpStatCooltPmpDryErr 0 "CooltPmpDryErr_RunDryNotDetd" 1 "CooltPmpDryErr_RunDryDetd" 2 "CooltPmpDryErr_Resd1" 3 "CooltPmpDryErr_Resd2";
VAL_ 697 EngPmpStatCooltPmpEmgyModSts 0 "CooltPmpEmgyModSts_EmgyRunNotActv" 1 "CooltPmpEmgyModSts_EmgyRunActv" 2 "CooltPmpEmgyModSts_Resd1" 3 "CooltPmpEmgyModSts_Resd2";
VAL_ 697 EngPmpStatCooltPmpErrSts 0 "CooltPmpErrSts_StNoErr" 1 "CooltPmpErrSts_StErr" 2 "CooltPmpErrSts_StNewErr" 3 "CooltPmpErrSts_Resd";
VAL_ 697 EngPmpStatCooltPmpIErr 0 "CooltPmpIErr_INoErr" 1 "CooltPmpIErr_IErr" 2 "CooltPmpIErr_Resd1" 3 "CooltPmpIErr_Resd2";
VAL_ 697 EngPmpStatCooltPmpMonrSpd 0 "CooltPmpMonrSpd_MonrSpdActv" 1 "CooltPmpMonrSpd_MonrSpdNoActv" 2 "CooltPmpMonrSpd_Resd1" 3 "CooltPmpMonrSpd_Resd2";
VAL_ 697 EngPmpStatCooltPmpPostRunSts 0 "CooltPmpPostRunSts_CooltPmpPostRunFinshd" 1 "CooltPmpPostRunSts_CooltPmpPostRunCncld" 2 "CooltPmpPostRunSts_Resd1" 3 "CooltPmpPostRunSts_Resd2";
VAL_ 697 EngPmpStatCooltPmpSetPostRunReq 0 "CooltPmpSetPostRunReq_CooltPmpSetNoPostRun" 1 "CooltPmpSetPostRunReq_CooltPmpSetPostRun1" 2 "CooltPmpSetPostRunReq_CooltPmpSetPostRun2" 3 "CooltPmpSetPostRunReq_CooltPmpSetPostRun3" 4 "CooltPmpSetPostRunReq_CooltPmpSetPostRun4" 5 "CooltPmpSetPostRunReq_CooltPmpSetPostRun5" 6 "CooltPmpSetPostRunReq_Resd1" 7 "CooltPmpSetPostRunReq_Resd2";
VAL_ 697 EngPmpStatCooltPmpTErr 0 "CooltPmpTErr_CooltPmpNoTErr" 1 "CooltPmpTErr_CooltPmpTErr" 2 "CooltPmpTErr_Resd1" 3 "CooltPmpTErr_Resd2";
VAL_ 697 EngPmpStatCooltPmpUErr 0 "CooltPmpUErr_CooltPmpNoUErr" 1 "CooltPmpUErr_CooltPmpUErr" 2 "CooltPmpUErr_Resd1" 3 "CooltPmpUErr_Resd2";
VAL_ 697 EngPmpStatCooltPmpUnstallSts 0 "CooltPmpUnstallSts_CooltPmpUnstallNotActv" 1 "CooltPmpUnstallSts_CooltPmpUnstallActv" 2 "CooltPmpUnstallSts_Resd1" 3 "CooltPmpUnstallSts_Resd2";
VAL_ 80 PtCluTq2PtCluTqQly 0 "Qly3_De0" 1 "Qly3_De1" 2 "Qly3_De2" 3 "Qly3_De3" 4 "Qly3_De4" 5 "Qly3_De5" 6 "Qly3_De6" 7 "Qly3_De7";
VAL_ 554 CmprFbCmprSts1 0 "CmprSts_CmprOff" 1 "CmprSts_CmprOn" 2 "CmprSts_CmprPwrLimd" 3 "CmprSts_CmprPreHeat" 4 "CmprSts_Reserved1" 5 "CmprSts_Reserved2" 6 "CmprSts_Reserved3" 7 "CmprSts_SigNotAvl";
VAL_ 554 CmprFbCmprSts2 0 "CompStat_NormalOperation" 1 "CompStat_DegradedOperation" 2 "CompStat_Inoperative";
VAL_ 1111 PtTqAtWhlFrntActPtTqAtWhlsFrntQly 0 "Qly3_De0" 1 "Qly3_De1" 2 "Qly3_De2" 3 "Qly3_De3" 4 "Qly3_De4" 5 "Qly3_De5" 6 "Qly3_De6" 7 "Qly3_De7";
VAL_ 730 HvBattPmpStatCooltPmpDryErr 0 "CooltPmpDryErr_RunDryNotDetd" 1 "CooltPmpDryErr_RunDryDetd" 2 "CooltPmpDryErr_Resd1" 3 "CooltPmpDryErr_Resd2";
VAL_ 730 HvBattPmpStatCooltPmpEmgyModSts 0 "CooltPmpEmgyModSts_EmgyRunNotActv" 1 "CooltPmpEmgyModSts_EmgyRunActv" 2 "CooltPmpEmgyModSts_Resd1" 3 "CooltPmpEmgyModSts_Resd2";
VAL_ 730 HvBattPmpStatCooltPmpErrSts 0 "CooltPmpErrSts_StNoErr" 1 "CooltPmpErrSts_StErr" 2 "CooltPmpErrSts_StNewErr" 3 "CooltPmpErrSts_Resd";
VAL_ 730 HvBattPmpStatCooltPmpIErr 0 "CooltPmpIErr_INoErr" 1 "CooltPmpIErr_IErr" 2 "CooltPmpIErr_Resd1" 3 "CooltPmpIErr_Resd2";
VAL_ 730 HvBattPmpStatCooltPmpMonrSpd 0 "CooltPmpMonrSpd_MonrSpdActv" 1 "CooltPmpMonrSpd_MonrSpdNoActv" 2 "CooltPmpMonrSpd_Resd1" 3 "CooltPmpMonrSpd_Resd2";
VAL_ 730 HvBattPmpStatCooltPmpPostRunSts 0 "CooltPmpPostRunSts_CooltPmpPostRunFinshd" 1 "CooltPmpPostRunSts_CooltPmpPostRunCncld" 2 "CooltPmpPostRunSts_Resd1" 3 "CooltPmpPostRunSts_Resd2";
VAL_ 730 HvBattPmpStatCooltPmpSetPostRunReq 0 "CooltPmpSetPostRunReq_CooltPmpSetNoPostRun" 1 "CooltPmpSetPostRunReq_CooltPmpSetPostRun1" 2 "CooltPmpSetPostRunReq_CooltPmpSetPostRun2" 3 "CooltPmpSetPostRunReq_CooltPmpSetPostRun3" 4 "CooltPmpSetPostRunReq_CooltPmpSetPostRun4" 5 "CooltPmpSetPostRunReq_CooltPmpSetPostRun5" 6 "CooltPmpSetPostRunReq_Resd1" 7 "CooltPmpSetPostRunReq_Resd2";
VAL_ 730 HvBattPmpStatCooltPmpTErr 0 "CooltPmpTErr_CooltPmpNoTErr" 1 "CooltPmpTErr_CooltPmpTErr" 2 "CooltPmpTErr_Resd1" 3 "CooltPmpTErr_Resd2";
VAL_ 730 HvBattPmpStatCooltPmpUErr 0 "CooltPmpUErr_CooltPmpNoUErr" 1 "CooltPmpUErr_CooltPmpUErr" 2 "CooltPmpUErr_Resd1" 3 "CooltPmpUErr_Resd2";
VAL_ 730 HvBattPmpStatCooltPmpUnstallSts 0 "CooltPmpUnstallSts_CooltPmpUnstallNotActv" 1 "CooltPmpUnstallSts_CooltPmpUnstallActv" 2 "CooltPmpUnstallSts_Resd1" 3 "CooltPmpUnstallSts_Resd2";
VAL_ 871 HvBattPmpCmdCooltPmpPostRunReq 0 "CooltPmpPostRun_CooltPmpNoPostRun" 1 "CooltPmpPostRun_CooltPmpPostRun1" 2 "CooltPmpPostRun_CooltPmpPostRun2" 3 "CooltPmpPostRun_CooltPmpPostRun3" 4 "CooltPmpPostRun_CooltPmpPostRun4" 5 "CooltPmpPostRun_Resvd1" 6 "CooltPmpPostRun_Resvd2" 7 "CooltPmpPostRun_Resvd3";
VAL_ 871 ReEvapVlvReq 0 "OnOff1_Off" 1 "OnOff1_On";
VAL_ 979 GrlShttrDmdShttrCalEna 0 "ShttrCalEna_ShttrCalNotEnad" 1 "ShttrCalEna_ShttrCalEnad";
VAL_ 979 SplrShttrDmdShttrCalEna 0 "ShttrCalEna_ShttrCalNotEnad" 1 "ShttrCalEna_ShttrCalEnad";
VAL_ 1039 CmprReqCluReqOvr 0 "CmprRunReq_CmprOff" 1 "CmprRunReq_CmprOn" 2 "CmprRunReq_Resd" 3 "CmprRunReq_SigNotAvl";
VAL_ 1039 EldtPmpCmdCooltPmpPostRunReq 0 "CooltPmpPostRun_CooltPmpNoPostRun" 1 "CooltPmpPostRun_CooltPmpPostRun1" 2 "CooltPmpPostRun_CooltPmpPostRun2" 3 "CooltPmpPostRun_CooltPmpPostRun3" 4 "CooltPmpPostRun_CooltPmpPostRun4" 5 "CooltPmpPostRun_Resvd1" 6 "CooltPmpPostRun_Resvd2" 7 "CooltPmpPostRun_Resvd3";
VAL_ 1039 EngCooltPmpSpdReqCooltPmpPostRunReq 0 "CooltPmpPostRun_CooltPmpNoPostRun" 1 "CooltPmpPostRun_CooltPmpPostRun1" 2 "CooltPmpPostRun_CooltPmpPostRun2" 3 "CooltPmpPostRun_CooltPmpPostRun3" 4 "CooltPmpPostRun_CooltPmpPostRun4" 5 "CooltPmpPostRun_Resvd1" 6 "CooltPmpPostRun_Resvd2" 7 "CooltPmpPostRun_Resvd3";
VAL_ 563 TrsmSailModReq 0 "TrsmSailModReq_NormalMode" 1 "TrsmSailModReq_Sailing" 2 "TrsmSailModReq_SailingFaulty" 3 "TrsmSailModReq_Reserved";
VAL_ 304 AccrpedlSts 0 "Flt_NoFault" 1 "Flt_Fault";
VAL_ 304 BsgDcDcPmpCmdCooltPmpPostRunReq 0 "CooltPmpPostRun_CooltPmpNoPostRun" 1 "CooltPmpPostRun_CooltPmpPostRun1" 2 "CooltPmpPostRun_CooltPmpPostRun2" 3 "CooltPmpPostRun_CooltPmpPostRun3" 4 "CooltPmpPostRun_CooltPmpPostRun4" 5 "CooltPmpPostRun_Resvd1" 6 "CooltPmpPostRun_Resvd2" 7 "CooltPmpPostRun_Resvd3";
VAL_ 304 CnvnAllwd 0 "OkNotOk_NotOk" 1 "OkNotOk_Ok";
VAL_ 1135 BattCooltIndcnReq 0 "Boolean_FALSE" 1 "Boolean_TRUE";
VAL_ 1135 MvIsgDcDcBattFlt 0 "MvIsgDcDcBattFlt_NoFault" 1 "MvIsgDcDcBattFlt_FaultLevel1" 2 "MvIsgDcDcBattFlt_FaultLevel2" 3 "MvIsgDcDcBattFlt_FaultLevel3" 4 "MvIsgDcDcBattFlt_FaultLevel4";
VAL_ 1135 MvIsgRBSModDisp 0 "MvIsgRBSModDisp_NoDisplay" 1 "MvIsgRBSModDisp_EMOffAndOnlyICEDriving" 2 "MvIsgRBSModDisp_EMDrivingAndICEDriving" 3 "MvIsgRBSModDisp_EMGeneratingAndICEDrivingClutchClose" 4 "MvIsgRBSModDisp_EMGenerating" 5 "MvIsgRBSModDisp_OnlyEMDriving" 6 "MvIsgRBSModDisp_EMGeneratingAndICEDrivingAndClutchOpen" 7 "MvIsgRBSModDisp_Sailing";
VAL_ 1135 TelltlPwrLoss 0 "OnOff1_Off" 1 "OnOff1_On";
VAL_ 455 HvActvSts 0 "HvActvSts_Default" 1 "HvActvSts_CPSRIsActivated" 2 "HvActvSts_CPSRPlusContactorsIsActivated" 3 "HvActvSts_Error";
VAL_ 455 PtTrsmOilFlowReq 0 "TrsmOilFlow_Lvl0" 1 "TrsmOilFlow_Lvl1" 2 "TrsmOilFlow_Lvl2" 3 "TrsmOilFlow_Lvl3" 4 "TrsmOilFlow_Lvl4" 5 "TrsmOilFlow_Lvl5" 6 "TrsmOilFlow_Lvl6" 7 "TrsmOilFlow_Lvl7" 8 "TrsmOilFlow_Lvl8" 9 "TrsmOilFlow_Lvl9" 10 "TrsmOilFlow_Lvl10" 11 "TrsmOilFlow_Lvl11" 12 "TrsmOilFlow_Lvl12" 13 "TrsmOilFlow_Lvl13" 14 "TrsmOilFlow_Lvl14" 15 "TrsmOilFlow_Lvl15" 16 "TrsmOilFlow_Lvl16" 17 "TrsmOilFlow_Lvl17" 18 "TrsmOilFlow_Lvl18" 19 "TrsmOilFlow_Lvl19" 20 "TrsmOilFlow_Lvl20";
VAL_ 543 GearMov 0 "NoYesUnknown_No" 1 "NoYesUnknown_Yes" 2 "NoYesUnknown_Unknown";
VAL_ 620 EldtPmpStatCooltPmpDryErr 0 "CooltPmpDryErr_RunDryNotDetd" 1 "CooltPmpDryErr_RunDryDetd" 2 "CooltPmpDryErr_Resd1" 3 "CooltPmpDryErr_Resd2";
VAL_ 620 EldtPmpStatCooltPmpEmgyModSts 0 "CooltPmpEmgyModSts_EmgyRunNotActv" 1 "CooltPmpEmgyModSts_EmgyRunActv" 2 "CooltPmpEmgyModSts_Resd1" 3 "CooltPmpEmgyModSts_Resd2";
VAL_ 620 EldtPmpStatCooltPmpErrSts 0 "CooltPmpErrSts_StNoErr" 1 "CooltPmpErrSts_StErr" 2 "CooltPmpErrSts_StNewErr" 3 "CooltPmpErrSts_Resd";
VAL_ 620 EldtPmpStatCooltPmpIErr 0 "CooltPmpIErr_INoErr" 1 "CooltPmpIErr_IErr" 2 "CooltPmpIErr_Resd1" 3 "CooltPmpIErr_Resd2";
VAL_ 620 EldtPmpStatCooltPmpMonrSpd 0 "CooltPmpMonrSpd_MonrSpdActv" 1 "CooltPmpMonrSpd_MonrSpdNoActv" 2 "CooltPmpMonrSpd_Resd1" 3 "CooltPmpMonrSpd_Resd2";
VAL_ 620 EldtPmpStatCooltPmpPostRunSts 0 "CooltPmpPostRunSts_CooltPmpPostRunFinshd" 1 "CooltPmpPostRunSts_CooltPmpPostRunCncld" 2 "CooltPmpPostRunSts_Resd1" 3 "CooltPmpPostRunSts_Resd2";
VAL_ 620 EldtPmpStatCooltPmpSetPostRunReq 0 "CooltPmpSetPostRunReq_CooltPmpSetNoPostRun" 1 "CooltPmpSetPostRunReq_CooltPmpSetPostRun1" 2 "CooltPmpSetPostRunReq_CooltPmpSetPostRun2" 3 "CooltPmpSetPostRunReq_CooltPmpSetPostRun3" 4 "CooltPmpSetPostRunReq_CooltPmpSetPostRun4" 5 "CooltPmpSetPostRunReq_CooltPmpSetPostRun5" 6 "CooltPmpSetPostRunReq_Resd1" 7 "CooltPmpSetPostRunReq_Resd2";
VAL_ 620 EldtPmpStatCooltPmpTErr 0 "CooltPmpTErr_CooltPmpNoTErr" 1 "CooltPmpTErr_CooltPmpTErr" 2 "CooltPmpTErr_Resd1" 3 "CooltPmpTErr_Resd2";
VAL_ 620 EldtPmpStatCooltPmpUErr 0 "CooltPmpUErr_CooltPmpNoUErr" 1 "CooltPmpUErr_CooltPmpUErr" 2 "CooltPmpUErr_Resd1" 3 "CooltPmpUErr_Resd2";
VAL_ 620 EldtPmpStatCooltPmpUnstallSts 0 "CooltPmpUnstallSts_CooltPmpUnstallNotActv" 1 "CooltPmpUnstallSts_CooltPmpUnstallActv" 2 "CooltPmpUnstallSts_Resd1" 3 "CooltPmpUnstallSts_Resd2";
VAL_ 632 GrlShttrStsShttrActrFlt 0 "ShttrActrFlt_ShttrActrNoFlt" 1 "ShttrActrFlt_ShttrActrFlt";
VAL_ 632 GrlShttrStsShttrBlkd 0 "ShttrBlkd_ShttrNotBlkd" 1 "ShttrBlkd_ShttrBlkd";
VAL_ 632 GrlShttrStsShttrCalActv 0 "ShttrCalActv_NotActv" 1 "ShttrCalActv_Actv";
VAL_ 632 GrlShttrStsShttrCalIndcd 0 "ShttrCalIndcd_ShttrCalNotIndcd" 1 "ShttrCalIndcd_ShttrCalIndcd";
VAL_ 632 GrlShttrStsShttrElecErr 0 "ShttrElecErr_ShttrNoElecErr" 1 "ShttrElecErr_ShttrElecErr";
VAL_ 632 GrlShttrStsShttrSnsrFlt 0 "ShttrSnsrFlt_ShttrSnsrNoFlt" 1 "ShttrSnsrFlt_ShttrSnsrFlt";
VAL_ 632 GrlShttrStsShttrTErr 0 "ShttrTErr_ShttrTNoErr" 1 "ShttrTErr_ShttrTErr";
VAL_ 632 GrlShttrStsShttrULoErr 0 "ShttrULoErr_ShttrNoULoErr" 1 "ShttrULoErr_ShttrULoErr";
VAL_ 642 SplrShttrStsShttrActrFlt 0 "ShttrActrFlt_ShttrActrNoFlt" 1 "ShttrActrFlt_ShttrActrFlt";
VAL_ 642 SplrShttrStsShttrBlkd 0 "ShttrBlkd_ShttrNotBlkd" 1 "ShttrBlkd_ShttrBlkd";
VAL_ 642 SplrShttrStsShttrCalActv 0 "ShttrCalActv_NotActv" 1 "ShttrCalActv_Actv";
VAL_ 642 SplrShttrStsShttrCalIndcd 0 "ShttrCalIndcd_ShttrCalNotIndcd" 1 "ShttrCalIndcd_ShttrCalIndcd";
VAL_ 642 SplrShttrStsShttrElecErr 0 "ShttrElecErr_ShttrNoElecErr" 1 "ShttrElecErr_ShttrElecErr";
VAL_ 642 SplrShttrStsShttrSnsrFlt 0 "ShttrSnsrFlt_ShttrSnsrNoFlt" 1 "ShttrSnsrFlt_ShttrSnsrFlt";
VAL_ 642 SplrShttrStsShttrTErr 0 "ShttrTErr_ShttrTNoErr" 1 "ShttrTErr_ShttrTErr";
VAL_ 642 SplrShttrStsShttrULoErr 0 "ShttrULoErr_ShttrNoULoErr" 1 "ShttrULoErr_ShttrULoErr";
VAL_ 131 EngSt1WdStsEngSt1WdSts 0 "EngSt1_Ini" 1 "EngSt1_Awake" 2 "EngSt1_Rdy" 3 "EngSt1_PreStrtg" 4 "EngSt1_StrtgInProgs" 5 "EngSt1_RunngRunng" 6 "EngSt1_RunngStb" 7 "EngSt1_RunngStrtgInProgs" 8 "EngSt1_RunngRemStrtd" 9 "EngSt1_AftRun";
VAL_ 131 JOACDampIndex 0 "DampIndex_GainN0" 1 "DampIndex_GainN1" 2 "DampIndex_GainN2" 3 "DampIndex_GainN3" 4 "DampIndex_GainN4" 5 "DampIndex_GainN5" 6 "DampIndex_GainN6" 7 "DampIndex_GainN7";
VAL_ 752 EngSt1WdSts1 0 "EngSt1_Ini" 1 "EngSt1_Awake" 2 "EngSt1_Rdy" 3 "EngSt1_PreStrtg" 4 "EngSt1_StrtgInProgs" 5 "EngSt1_RunngRunng" 6 "EngSt1_RunngStb" 7 "EngSt1_RunngStrtgInProgs" 8 "EngSt1_RunngRemStrtd" 9 "EngSt1_AftRun";
VAL_ 213 MvEMModSts 0 "MvEMModSts_Openbridge" 1 "MvEMModSts_Stdby" 2 "MvEMModSts_Failure" 3 "MvEMModSts_TqCtl" 4 "MvEMModSts_TqCtlDer" 5 "MvEMModSts_SpdCtl" 6 "MvEMModSts_SpdCtlDer" 7 "MvEMModSts_Initial" 8 "MvEMModSts_PwrDwn" 9 "MvEMModSts_UDcCtl" 10 "MvEMModSts_UDcCtlDer" 11 "MvEMModSts_GenNoBatCtl" 12 "MvEMModSts_GenNoBatCtlDer" 13 "MvEMModSts_ZeroTqCtrl" 14 "MvEMModSts_InitFlt";
VAL_ 213 MvEMTqActSafe1QualityFactor 0 "QualityFactor_QfUndefd" 1 "QualityFactor_QfInProgs" 2 "QualityFactor_QfNotSpc" 3 "QualityFactor_QfSnsrDataOk";
VAL_ 529 ImobEngChk3v2ImobEngChkSts 0 "AvlSts2_NotAvl" 1 "AvlSts2_Avl";
VAL_ 529 ImobEngSts3v2 0 "ImobSts_ImobUndefd" 1 "ImobSts_ImobImobn" 2 "ImobSts_ImobMtn" 3 "ImobSts_ImobNoMtn";
VAL_ 235 PrkgPinionAgReqGroupQF 0 "GenQf1_UndefindDataAccur" 1 "GenQf1_TmpUndefdData" 2 "GenQf1_DataAccurNotWithinSpcn" 3 "GenQf1_AccurData";
VAL_ 246 ADL3LatCtrlStsADMod 0 "ADMod_NAD_Mod" 1 "ADMod_TJP" 2 "ADMod_SHWA" 3 "ADMod_Reserved";
VAL_ 246 ADL3LatCtrlStsCtrlSts 0 "Primary" 1 "Secondary";
VAL_ 246 ADL3LatCtrlStsDegraded 0 "LatDegrad_NoDegradation_Green" 1 "LatDegrad_Red_fault1" 2 "LatDegrad_Yellow_fault2" 3 "LatDegrad_Yellow_fault3" 4 "LatDegrad_Yellow_fault4" 5 "LatDegrad_Yellow_fault5" 6 "LatDegrad_Yellow_fault6" 7 "LatDegrad_Yellow_fault7" 8 "LatDegrad_Yellow_fault8" 9 "LatDegrad_Yellow_fault9" 10 "LatDegrad_Yellow_fault10" 11 "LatDegrad_Reserved1";
VAL_ 246 ADL3LatCtrlStsQf 0 "GenQf1_UndefindDataAccur" 1 "GenQf1_TmpUndefdData" 2 "GenQf1_DataAccurNotWithinSpcn" 3 "GenQf1_AccurData";
VAL_ 246 ADL3LatCtrlStsSts 0 "ColorSts_Red" 1 "ColorSts_Yellow" 2 "ColorSts_Green" 3 "ColorSts_Reserved";
VAL_ 246 DrvrSteerActvDrvrSteerActv 0 "OnOff1_Off" 1 "OnOff1_On";
VAL_ 246 UBoostReqBySteerFrnt 0 "ReqStsSteer_NoReq" 1 "ReqStsSteer_ParkReq" 2 "ReqStsSteer_EvasiveReq" 3 "ReqStsSteer_Spare01";
VAL_ 70 LatCtrlModCfmdLatCtrlMod 0 "LatCtrlMod1_NoReq" 1 "LatCtrlMod1_HighWayAssist" 2 "LatCtrlMod1_EmgyLaneKeepAidForObjRe" 3 "LatCtrlMod1_EmgyLaneKeepAidForStat" 4 "LatCtrlMod1_SftyLaneKeepAid" 5 "LatCtrlMod1_SteerAssc" 6 "LatCtrlMod1_DsrOversteer" 7 "LatCtrlMod1_DsrMueSplit" 8 "LatCtrlMod1_DsrTrlrStaby" 9 "LatCtrlMod1_EmgyManvAssi" 10 "LatCtrlMod1_Reserved1" 11 "LatCtrlMod1_Reserved2" 12 "LatCtrlMod1_SHWA" 13 "LatCtrlMod1_APA" 14 "LatCtrlMod1_RPA" 15 "LatCtrlMod1_HPA";
VAL_ 70 SteerServoSts 0 "SteerServoSts1_SteerPwrAssidElecFullFct" 1 "SteerServoSts1_SteerPwrAssidElecCritErr";
VAL_ 444 DrvrSteerWhlHldGroupDrvrSteerWhlHld 0 "OnOffDetd1_NoInfo" 1 "OnOffDetd1_OffDetd" 2 "OnOffDetd1_NotOnOrOffDetd" 3 "OnOffDetd1_OnDetd";
VAL_ 444 SteerErrReq 0 "SteerErrReq3_NoReq" 1 "SteerErrReq3_SteerAssiSrvRqrd" 2 "SteerErrReq3_SteerErrStopSfty" 3 "SteerErrReq3_SteerAssiUrgentSrvRqrd" 4 "SteerErrReq3_SteerAssiTmpRedn" 5 "SteerErrReq3_Spare01" 6 "SteerErrReq3_Spare02" 7 "SteerErrReq3_Spare03";
VAL_ 444 SteerExtFctStsDrvrSteerOvrd 0 "Boolean_FALSE" 1 "Boolean_TRUE";
VAL_ 444 SteerExtFctStsExtFctLowerLimActive 0 "Boolean_FALSE" 1 "Boolean_TRUE";
VAL_ 444 SteerExtFctStsExtFctRateLimActive 0 "Boolean_FALSE" 1 "Boolean_TRUE";
VAL_ 444 SteerExtFctStsExtFctUpperLimActive 0 "Boolean_FALSE" 1 "Boolean_TRUE";
VAL_ 444 SteerExtFctStsExtSafeLimActive 0 "Boolean_FALSE" 1 "Boolean_TRUE";
VAL_ 444 SteerExtFctStsLatAgReqNotInRange 0 "Boolean_FALSE" 1 "Boolean_TRUE";
VAL_ 444 SteerExtFctStsLatCtrlReqNotInRange 0 "Boolean_FALSE" 1 "Boolean_TRUE";
VAL_ 444 SteerStsToParkAssi 0 "SteerStsToParkAssi_NormOper" 1 "SteerStsToParkAssi_SteerAbortBySpdHi" 2 "SteerStsToParkAssi_CtrlDifHi" 3 "SteerStsToParkAssi_SteerCtrlIntErr" 4 "SteerStsToParkAssi_SteerAbortByDrvrIntv" 5 "SteerStsToParkAssi_SteerTqHi" 6 "SteerStsToParkAssi_Spare1" 7 "SteerStsToParkAssi_Spare2";
VAL_ 78 PinionSteerAgGroupPinionSteerAg1Qf 0 "GenQf1_UndefindDataAccur" 1 "GenQf1_TmpUndefdData" 2 "GenQf1_DataAccurNotWithinSpcn" 3 "GenQf1_AccurData";
VAL_ 78 PinionSteerAgGroupPinionSteerAgSpd1Qf 0 "GenQf1_UndefindDataAccur" 1 "GenQf1_TmpUndefdData" 2 "GenQf1_DataAccurNotWithinSpcn" 3 "GenQf1_AccurData";
VAL_ 78 PinionSteerAgGroupSteerWhlTqQf 0 "GenQf1_UndefindDataAccur" 1 "GenQf1_TmpUndefdData" 2 "GenQf1_DataAccurNotWithinSpcn" 3 "GenQf1_AccurData";
VAL_ 64 SteerWhlSnsrQf 0 "GenQf1_UndefindDataAccur" 1 "GenQf1_TmpUndefdData" 2 "GenQf1_DataAccurNotWithinSpcn" 3 "GenQf1_AccurData";
VAL_ 42 TrsmCluSlipPwrIntgl1Qf 0 "TrsmCluSlipPwrIntglIdxQf_Invld" 1 "TrsmCluSlipPwrIntglIdxQf_Ini" 2 "TrsmCluSlipPwrIntglIdxQf_NotWithinRng" 3 "TrsmCluSlipPwrIntglIdxQf_Ok";
VAL_ 42 TrsmCluSlipPwrIntgl2Qf 0 "TrsmCluSlipPwrIntglIdxQf_Invld" 1 "TrsmCluSlipPwrIntglIdxQf_Ini" 2 "TrsmCluSlipPwrIntglIdxQf_NotWithinRng" 3 "TrsmCluSlipPwrIntglIdxQf_Ok";
VAL_ 42 TrsmGearAct1 0 "TrsmGear_Neut" 1 "TrsmGear_Gear1" 2 "TrsmGear_Gear2" 3 "TrsmGear_Gear3" 4 "TrsmGear_Gear4" 5 "TrsmGear_Gear5" 6 "TrsmGear_Gear6" 7 "TrsmGear_Gear7" 8 "TrsmGear_Gear8" 9 "TrsmGear_Gear9" 10 "TrsmGear_Gear10" 11 "TrsmGear_Gear11" 12 "TrsmGear_Gear12" 13 "TrsmGear_Gear13" 14 "TrsmGear_Rvs" 15 "TrsmGear_Park";
VAL_ 42 TrsmGearAct2 0 "TrsmGear_Neut" 1 "TrsmGear_Gear1" 2 "TrsmGear_Gear2" 3 "TrsmGear_Gear3" 4 "TrsmGear_Gear4" 5 "TrsmGear_Gear5" 6 "TrsmGear_Gear6" 7 "TrsmGear_Gear7" 8 "TrsmGear_Gear8" 9 "TrsmGear_Gear9" 10 "TrsmGear_Gear10" 11 "TrsmGear_Gear11" 12 "TrsmGear_Gear12" 13 "TrsmGear_Gear13" 14 "TrsmGear_Rvs" 15 "TrsmGear_Park";
VAL_ 42 TrsmGearEngmtSts1 0 "TrsmGearEngmtSts_HiNeut" 1 "TrsmGearEngmtSts_NomNeut" 2 "TrsmGearEngmtSts_GearUkwn" 3 "TrsmGearEngmtSts_PtlEngd" 4 "TrsmGearEngmtSts_GearEngd" 5 "TrsmGearEngmtSts_Gear";
VAL_ 42 TrsmGearEngmtSts2 0 "TrsmGearEngmtSts_HiNeut" 1 "TrsmGearEngmtSts_NomNeut" 2 "TrsmGearEngmtSts_GearUkwn" 3 "TrsmGearEngmtSts_PtlEngd" 4 "TrsmGearEngmtSts_GearEngd" 5 "TrsmGearEngmtSts_Gear";
VAL_ 42 TrsmReqForPfmncRedn3 0 "Boolean_FALSE" 1 "Boolean_TRUE";
VAL_ 48 TrsmNRecInpDir1 0 "TrsmNInpOutpDir_NotBackw" 1 "TrsmNInpOutpDir_Backw";
VAL_ 48 TrsmNRecInpDir2 0 "TrsmNInpOutpDir_NotBackw" 1 "TrsmNInpOutpDir_Backw";
VAL_ 48 TrsmNRecInpQf1 0 "TrsmNInpOutpQf_Nok" 1 "TrsmNInpOutpQf_Lvl0" 2 "TrsmNInpOutpQf_Lvl1" 3 "TrsmNInpOutpQf_Lvl2";
VAL_ 48 TrsmNRecInpQf2 0 "TrsmNInpOutpQf_Nok" 1 "TrsmNInpOutpQf_Lvl0" 2 "TrsmNInpOutpQf_Lvl1" 3 "TrsmNInpOutpQf_Lvl2";
VAL_ 48 TrsmNRecOutpDir 0 "TrsmNInpOutpDir_NotBackw" 1 "TrsmNInpOutpDir_Backw";
VAL_ 48 TrsmNRecOutpQf 0 "TrsmNInpOutpQf_Nok" 1 "TrsmNInpOutpQf_Lvl0" 2 "TrsmNInpOutpQf_Lvl1" 3 "TrsmNInpOutpQf_Lvl2";
VAL_ 53 TrsmCluSlipCtrlModSts 0 "TrsmCluSlipCtrlModSts_SlipCtrlNotActv" 1 "TrsmCluSlipCtrlModSts_SlipCtrlMod" 2 "TrsmCluSlipCtrlModSts_TqFolwMod" 3 "TrsmCluSlipCtrlModSts_SlipCtrlEndFctFinshd";
VAL_ 53 TrsmCluT1Qf 0 "TrsmCluTQf_Invld" 1 "TrsmCluTQf_Ini" 2 "TrsmCluTQf_NotWithinRng" 3 "TrsmCluTQf_Ok";
VAL_ 53 TrsmCluT2Qf 0 "TrsmCluTQf_Invld" 1 "TrsmCluTQf_Ini" 2 "TrsmCluTQf_NotWithinRng" 3 "TrsmCluTQf_Ok";
VAL_ 53 TrsmCluTqCpMaxInProgs1 0 "Boolean_FALSE" 1 "Boolean_TRUE";
VAL_ 53 TrsmCluTqCpMaxInProgs2 0 "Boolean_FALSE" 1 "Boolean_TRUE";
VAL_ 53 TrsmCluTqCpMaxPrio1 0 "TrsmCluTqCpMaxMinPrio_Not" 1 "TrsmCluTqCpMaxMinPrio_Now" 2 "TrsmCluTqCpMaxMinPrio_Imdt" 3 "TrsmCluTqCpMaxMinPrio_Psbl";
VAL_ 53 TrsmCluTqCpMaxPrio2 0 "TrsmCluTqCpMaxMinPrio_Not" 1 "TrsmCluTqCpMaxMinPrio_Now" 2 "TrsmCluTqCpMaxMinPrio_Imdt" 3 "TrsmCluTqCpMaxMinPrio_Psbl";
VAL_ 53 TrsmCluTqCpMinInProgs1 0 "Boolean_FALSE" 1 "Boolean_TRUE";
VAL_ 53 TrsmCluTqCpMinInProgs2 0 "Boolean_FALSE" 1 "Boolean_TRUE";
VAL_ 53 TrsmGearActrScanForRefActv 0 "TrsmGearActrScanForRefActv_ScanRefNotActv" 1 "TrsmGearActrScanForRefActv_ScanRefActv";
VAL_ 53 TrsmGearActrScanForRefReq 0 "TrsmGearActrScanForRefReq_ScanRefNotReqd" 1 "TrsmGearActrScanForRefReq_ScanRefReqd";
VAL_ 53 TrsmOilFlow 0 "TrsmOilFlow_Lvl0" 1 "TrsmOilFlow_Lvl1" 2 "TrsmOilFlow_Lvl2" 3 "TrsmOilFlow_Lvl3" 4 "TrsmOilFlow_Lvl4" 5 "TrsmOilFlow_Lvl5" 6 "TrsmOilFlow_Lvl6" 7 "TrsmOilFlow_Lvl7" 8 "TrsmOilFlow_Lvl8" 9 "TrsmOilFlow_Lvl9" 10 "TrsmOilFlow_Lvl10" 11 "TrsmOilFlow_Lvl11" 12 "TrsmOilFlow_Lvl12" 13 "TrsmOilFlow_Lvl13" 14 "TrsmOilFlow_Lvl14" 15 "TrsmOilFlow_Lvl15" 16 "TrsmOilFlow_Lvl16" 17 "TrsmOilFlow_Lvl17" 18 "TrsmOilFlow_Lvl18" 19 "TrsmOilFlow_Lvl19" 20 "TrsmOilFlow_Lvl20";
VAL_ 53 TrsmSlipCtrlReq 0 "TrsmSlipCtrlReq_NoReqForSlipCtrl" 1 "TrsmSlipCtrlReq_ReqForSlipCtrl";
VAL_ 53 TrsmSoftRotReq1 0 "Boolean_FALSE" 1 "Boolean_TRUE";
VAL_ 53 TrsmSoftRotReq2 0 "Boolean_FALSE" 1 "Boolean_TRUE";
VAL_ 117 TrsmCluActrLimd1 0 "TrsmCluActrLimd_NotLimd" 1 "TrsmCluActrLimd_Limd";
VAL_ 117 TrsmCluActrLimd2 0 "TrsmCluActrLimd_NotLimd" 1 "TrsmCluActrLimd_Limd";
VAL_ 117 TrsmCluActrOff1 0 "Boolean_FALSE" 1 "Boolean_TRUE";
VAL_ 117 TrsmCluActrOff2 0 "Boolean_FALSE" 1 "Boolean_TRUE";
VAL_ 117 TrsmCluActrTLvl1 0 "TrsmCluActrTLvl_NormOper" 1 "TrsmCluActrTLvl_Warn1" 2 "TrsmCluActrTLvl_Warn2" 3 "TrsmCluActrTLvl_NoOper";
VAL_ 117 TrsmCluActrTLvl2 0 "TrsmCluActrTLvl_NormOper" 1 "TrsmCluActrTLvl_Warn1" 2 "TrsmCluActrTLvl_Warn2" 3 "TrsmCluActrTLvl_NoOper";
VAL_ 117 TrsmCluTqCpCorrln1 0 "TrsmCluTqCpCorrln_Not" 1 "TrsmCluTqCpCorrln_Low" 2 "TrsmCluTqCpCorrln_Med" 3 "TrsmCluTqCpCorrln_Hi";
VAL_ 117 TrsmCluTqCpCorrln2 0 "TrsmCluTqCpCorrln_Not" 1 "TrsmCluTqCpCorrln_Low" 2 "TrsmCluTqCpCorrln_Med" 3 "TrsmCluTqCpCorrln_Hi";
VAL_ 117 TrsmCluTqCpMinPrio1 0 "TrsmCluTqCpMaxMinPrio_Not" 1 "TrsmCluTqCpMaxMinPrio_Now" 2 "TrsmCluTqCpMaxMinPrio_Imdt" 3 "TrsmCluTqCpMaxMinPrio_Psbl";
VAL_ 117 TrsmCluTqCpMinPrio2 0 "TrsmCluTqCpMaxMinPrio_Not" 1 "TrsmCluTqCpMaxMinPrio_Now" 2 "TrsmCluTqCpMaxMinPrio_Imdt" 3 "TrsmCluTqCpMaxMinPrio_Psbl";
VAL_ 117 TrsmEndOfLineModActv 0 "Boolean_FALSE" 1 "Boolean_TRUE";
VAL_ 117 TrsmGbxActrOff 0 "TrsmGbxActrOff_NotOff" 1 "TrsmGbxActrOff_Faild";
VAL_ 117 TrsmGearActrSts 0 "TrsmGearActrSts_StsNotOk" 1 "TrsmGearActrSts_StsOk";
VAL_ 117 TrsmGearActrTLvl 0 "TrsmGearActrTLvl_NormOper" 1 "TrsmGearActrTLvl_TLvl1" 2 "TrsmGearActrTLvl_TLvl2" 3 "TrsmGearActrTLvl_TLvl3";
VAL_ 117 TrsmHardRotReq1 0 "Boolean_FALSE" 1 "Boolean_TRUE";
VAL_ 117 TrsmHardRotReq2 0 "Boolean_FALSE" 1 "Boolean_TRUE";
VAL_ 117 TrsmOilPmpTLvl 0 "TrsmOilPmpTLvl_NormOper" 1 "TrsmOilPmpTLvl_TLvl1" 2 "TrsmOilPmpTLvl_TLvl2" 3 "TrsmOilPmpTLvl_TLvl3";
SIG_GROUP_ 544 AccrPedlRat 1 : AccrPedlRatAccrPedlRat AccrPedlRatChks AccrPedlRatCntr;
SIG_GROUP_ 246 ADL3LatCtrlSts 1 : ADL3LatCtrlStsADMod ADL3LatCtrlStsChks ADL3LatCtrlStsCntr ADL3LatCtrlStsCtrlSts ADL3LatCtrlStsDegraded ADL3LatCtrlStsQf ADL3LatCtrlStsSts;
SIG_GROUP_ 147 AsyADL3FuncCtrlSts 1 : AsyADL3FuncCtrlStsADMod AsyADL3FuncCtrlStsChks AsyADL3FuncCtrlStsCntr AsyADL3FuncCtrlStsCtrlSts AsyADL3FuncCtrlStsDegraded AsyADL3FuncCtrlStsQf AsyADL3FuncCtrlStsSts;
SIG_GROUP_ 147 AsyADModeReq 1 : AsyADModeReqADActiveReq AsyADModeReqADDeactiveReq AsyADModeReqChks AsyADModeReqCntr;
SIG_GROUP_ 51 AsyPinionAgReqSafe 1 : AsyPinionAgReqSafeAsyPinionAgReq AsyPinionAgReqSafeAsyPinionAgReqChks AsyPinionAgReqSafeAsyPinionAgReqCntr;
SIG_GROUP_ 304 BsgDcDcPmpCmd 1 : BsgDcDcPmpCmdCooltPmpPostRunReq BsgDcDcPmpCmdCooltPmpSpdReq;
SIG_GROUP_ 554 CmprFb 1 : CmprFbCmprI CmprFbCmprIPha CmprFbCmprSpd CmprFbCmprSts1 CmprFbCmprSts2 CmprFbCmprT1 CmprFbCmprT2 CmprFbCmprU;
SIG_GROUP_ 246 DrvrSteerActv 1 : DrvrSteerActvChks DrvrSteerActvCntr DrvrSteerActvDrvrSteerActv;
SIG_GROUP_ 444 DrvrSteerWhlHldGroup 1 : DrvrSteerWhlHldGroupDrvrSteerWhlHld DrvrSteerWhlHldGroupDrvrSteerWhlHldQly;
SIG_GROUP_ 1039 EldtPmpCmd 1 : EldtPmpCmdCooltPmpPostRunReq EldtPmpCmdCooltPmpSpdReq;
SIG_GROUP_ 620 EldtPmpStat 1 : EldtPmpStatCooltPmpDryErr EldtPmpStatCooltPmpEmgyModSts EldtPmpStatCooltPmpErrSts EldtPmpStatCooltPmpI EldtPmpStatCooltPmpIErr EldtPmpStatCooltPmpMonrSpd EldtPmpStatCooltPmpPostRunSts EldtPmpStatCooltPmpSetPostRunReq EldtPmpStatCooltPmpSetSpdReq EldtPmpStatCooltPmpSpd EldtPmpStatCooltPmpT EldtPmpStatCooltPmpTErr EldtPmpStatCooltPmpU EldtPmpStatCooltPmpUErr EldtPmpStatCooltPmpUnstallSts;
SIG_GROUP_ 1039 EngCooltPmpSpdReq 1 : EngCooltPmpSpdReqCooltPmpPostRunReq EngCooltPmpSpdReqCooltPmpSpdReq;
SIG_GROUP_ 304 EngNSafe 1 : EngNSafeEngN EngNSafeEngNChks EngNSafeEngNCntr EngNSafeEngNGrdt;
SIG_GROUP_ 697 EngPmpStat 1 : EngPmpStatCooltPmpDryErr EngPmpStatCooltPmpEmgyModSts EngPmpStatCooltPmpErrSts EngPmpStatCooltPmpI EngPmpStatCooltPmpIErr EngPmpStatCooltPmpMonrSpd EngPmpStatCooltPmpPostRunSts EngPmpStatCooltPmpSetPostRunReq EngPmpStatCooltPmpSetSpdReq EngPmpStatCooltPmpSpd EngPmpStatCooltPmpT EngPmpStatCooltPmpTErr EngPmpStatCooltPmpU EngPmpStatCooltPmpUErr EngPmpStatCooltPmpUnstallSts;
SIG_GROUP_ 131 EngSt1WdSts 1 : EngSt1WdStsChks EngSt1WdStsCntr EngSt1WdStsEngSt1WdSts;
SIG_GROUP_ 544 EngT 1 : EngTEngT EngTQf;
SIG_GROUP_ 1135 EngTRef 1 : EngTRefSts EngTRefT1 EngTRefT2;
SIG_GROUP_ 979 GrlShttrDmd 1 : GrlShttrDmdShttrCalEna GrlShttrDmdShttrPosnReq;
SIG_GROUP_ 632 GrlShttrSts 1 : GrlShttrStsShttrActrFlt GrlShttrStsShttrBlkd GrlShttrStsShttrCalActv GrlShttrStsShttrCalIndcd GrlShttrStsShttrElecErr GrlShttrStsShttrPosnRaw GrlShttrStsShttrSnsrFlt GrlShttrStsShttrTErr GrlShttrStsShttrULoErr;
SIG_GROUP_ 871 HvBattPmpCmd 1 : HvBattPmpCmdCooltPmpPostRunReq HvBattPmpCmdCooltPmpSpdReq;
SIG_GROUP_ 730 HvBattPmpStat 1 : HvBattPmpStatCooltPmpDryErr HvBattPmpStatCooltPmpEmgyModSts HvBattPmpStatCooltPmpErrSts HvBattPmpStatCooltPmpI HvBattPmpStatCooltPmpIErr HvBattPmpStatCooltPmpMonrSpd HvBattPmpStatCooltPmpPostRunSts HvBattPmpStatCooltPmpSetPostRunReq HvBattPmpStatCooltPmpSetSpdReq HvBattPmpStatCooltPmpSpd HvBattPmpStatCooltPmpT HvBattPmpStatCooltPmpTErr HvBattPmpStatCooltPmpU HvBattPmpStatCooltPmpUErr HvBattPmpStatCooltPmpUnstallSts;
SIG_GROUP_ 529 ImobEngChk3v2 1 : ImobEngChk3v2ImobEngChkSts ImobEngChk3v2ImobEngDataChk0 ImobEngChk3v2ImobEngDataChk1 ImobEngChk3v2ImobEngDataChk2 ImobEngChk3v2ImobEngDataChk3 ImobEngChk3v2ImobEngDataChk4 ImobEngChk3v2ImobEngDataChk5 ImobEngChk3v2ImobEngDataChk6;
SIG_GROUP_ 70 LatCtrlModCfmd 1 : LatCtrlModCfmdChks LatCtrlModCfmdCntr LatCtrlModCfmdLatCtrlMod;
SIG_GROUP_ 226 MvEMModReq 1 : MvEMModReqChks MvEMModReqCntr MvEMModReqMvEMModReq;
SIG_GROUP_ 213 MvEMTqActSafe1 1 : MvEMTqActSafe1MvIsgTq MvEMTqActSafe1MvIsgTqChks MvEMTqActSafe1MvIsgTqCntr MvEMTqActSafe1QualityFactor;
SIG_GROUP_ 78 PinionSteerAgGroup 1 : PinionSteerAgGroupChks PinionSteerAgGroupCntr PinionSteerAgGroupPinionSteerAg1 PinionSteerAgGroupPinionSteerAg1Qf PinionSteerAgGroupPinionSteerAgSpd1 PinionSteerAgGroupPinionSteerAgSpd1Qf PinionSteerAgGroupSteerWhlTq PinionSteerAgGroupSteerWhlTqQf;
SIG_GROUP_ 235 PrkgPinionAgReqGroup 1 : PrkgPinionAgReqGroupParkAssiPinionAgReq PrkgPinionAgReqGroupParkAssiPinionAgReqChks PrkgPinionAgReqGroupParkAssiPinionAgReqCntr PrkgPinionAgReqGroupQF;
SIG_GROUP_ 1431 PSCMdevelpsignalgroupreq1 1 : PSCMdevelpsignalgroupreq1Functiondevpsignalgroup1 PSCMdevelpsignalgroupreq1Functiondevpsignalgroup2 PSCMdevelpsignalgroupreq1Functiondevpsignalgroup3 PSCMdevelpsignalgroupreq1Functiondevpsignalgroup4 PSCMdevelpsignalgroupreq1Functiondevpsignalgroup5 PSCMdevelpsignalgroupreq1Functiondevpsignalgroup6 PSCMdevelpsignalgroupreq1Functiondevpsignalgroup7 PSCMdevelpsignalgroupreq1Functiondevpsignalgroup8;
SIG_GROUP_ 1430 PSCMdevelpsignalgroupresp1 1 : PSCMdevelpsignalgroupresp1Functiondevpsignalgroup1 PSCMdevelpsignalgroupresp1Functiondevpsignalgroup2 PSCMdevelpsignalgroupresp1Functiondevpsignalgroup3 PSCMdevelpsignalgroupresp1Functiondevpsignalgroup4 PSCMdevelpsignalgroupresp1Functiondevpsignalgroup5 PSCMdevelpsignalgroupresp1Functiondevpsignalgroup6 PSCMdevelpsignalgroupresp1Functiondevpsignalgroup7 PSCMdevelpsignalgroupresp1Functiondevpsignalgroup8;
SIG_GROUP_ 32 PtCluSlipCtrl 1 : PtCluSlipCtrlModReq PtCluSlipCtrlReq PtCluSlipCtrlSpdReq;
SIG_GROUP_ 80 PtCluTq2 1 : PtCluTq2PtCluTq PtCluTq2PtCluTqQly;
SIG_GROUP_ 32 PtCluTqCp 1 : PtCluTqCpReq1 PtCluTqCpReq2;
SIG_GROUP_ 37 PtDirAllwdToTrsmActr 1 : PtDirAllwdToTrsmActrChks PtDirAllwdToTrsmActrCntr PtDirAllwdToTrsmActrFwd PtDirAllwdToTrsmActrNeut PtDirAllwdToTrsmActrParkRls PtDirAllwdToTrsmActrRvs;
SIG_GROUP_ 37 PtGearActtn 1 : PtGearActtnAllwdSts1 PtGearActtnAllwdSts2 PtGearActtnModReq PtGearActtnPfmncReq PtGearActtnPrio PtGearActtnReq1 PtGearActtnReq2;
SIG_GROUP_ 1111 PtTqAtWhlFrntAct 1 : PtTqAtWhlFrntActChks PtTqAtWhlFrntActCntr PtTqAtWhlFrntActPtTqAtAxleFrntAct PtTqAtWhlFrntActPtTqAtWhlFrntLeAct PtTqAtWhlFrntActPtTqAtWhlFrntRiAct PtTqAtWhlFrntActPtTqAtWhlsFrntQly;
SIG_GROUP_ 708 PtVehSpdMax 1 : PtVehSpdMaxChks PtVehSpdMaxCntr PtVehSpdMaxReq;
SIG_GROUP_ 979 SplrShttrDmd 1 : SplrShttrDmdShttrCalEna SplrShttrDmdShttrPosnReq;
SIG_GROUP_ 642 SplrShttrSts 1 : SplrShttrStsShttrActrFlt SplrShttrStsShttrBlkd SplrShttrStsShttrCalActv SplrShttrStsShttrCalIndcd SplrShttrStsShttrElecErr SplrShttrStsShttrPosnRaw SplrShttrStsShttrSnsrFlt SplrShttrStsShttrTErr SplrShttrStsShttrULoErr;
SIG_GROUP_ 444 SteerExtFctSts 1 : SteerExtFctStsChks SteerExtFctStsCntr SteerExtFctStsDrvrSteerOvrd SteerExtFctStsExtFctLowerLimActive SteerExtFctStsExtFctRateLimActive SteerExtFctStsExtFctUpperLimActive SteerExtFctStsExtSafeLimActive SteerExtFctStsLatAgReqNotInRange SteerExtFctStsLatCtrlReqNotInRange;
SIG_GROUP_ 64 SteerWhlSnsr 1 : SteerWhlSnsrAg SteerWhlSnsrAgSpd SteerWhlSnsrChks SteerWhlSnsrCntr SteerWhlSnsrQf;
SIG_GROUP_ 42 TrsmCluSlipPwrIntgl1 1 : TrsmCluSlipPwrIntgl1Idx TrsmCluSlipPwrIntgl1Qf;
SIG_GROUP_ 42 TrsmCluSlipPwrIntgl2 1 : TrsmCluSlipPwrIntgl2Idx TrsmCluSlipPwrIntgl2Qf;
SIG_GROUP_ 53 TrsmCluT1 1 : TrsmCluT1Qf TrsmCluT1Val;
SIG_GROUP_ 53 TrsmCluT2 1 : TrsmCluT2Qf TrsmCluT2Val;
SIG_GROUP_ 42 TrsmCluTq 1 : TrsmCluTqCp1 TrsmCluTqCp2;
SIG_GROUP_ 42 TrsmGear 1 : TrsmGearAct1 TrsmGearAct2 TrsmGearEngmtSts1 TrsmGearEngmtSts2;
SIG_GROUP_ 48 TrsmNRec 1 : TrsmNRecChks TrsmNRecCntr TrsmNRecInp1 TrsmNRecInp2 TrsmNRecInpDir1 TrsmNRecInpDir2 TrsmNRecInpQf1 TrsmNRecInpQf2 TrsmNRecOutp TrsmNRecOutpDir TrsmNRecOutpQf;
SIG_GROUP_ 1432 VDDMdevelpsignalgroupreq1 1 : VDDMdevelpsignalgroupreq1Functiondevpsignalgroup1 VDDMdevelpsignalgroupreq1Functiondevpsignalgroup2 VDDMdevelpsignalgroupreq1Functiondevpsignalgroup3 VDDMdevelpsignalgroupreq1Functiondevpsignalgroup4 VDDMdevelpsignalgroupreq1Functiondevpsignalgroup5 VDDMdevelpsignalgroupreq1Functiondevpsignalgroup6 VDDMdevelpsignalgroupreq1Functiondevpsignalgroup7 VDDMdevelpsignalgroupreq1Functiondevpsignalgroup8;
SIG_GROUP_ 1433 VDDMdevelpsignalgroupreq2 1 : VDDMdevelpsignalgroupreq2Functiondevpsignalgroup1 VDDMdevelpsignalgroupreq2Functiondevpsignalgroup2 VDDMdevelpsignalgroupreq2Functiondevpsignalgroup3 VDDMdevelpsignalgroupreq2Functiondevpsignalgroup4 VDDMdevelpsignalgroupreq2Functiondevpsignalgroup5 VDDMdevelpsignalgroupreq2Functiondevpsignalgroup6 VDDMdevelpsignalgroupreq2Functiondevpsignalgroup7 VDDMdevelpsignalgroupreq2Functiondevpsignalgroup8;
